VERSION "June 2, 2025"

NS_ :

BS_:

BU_: VEH CH Receiver Receiver ChassisBus VehicleBus PartyBus

BO_ 832 VCFRONT_alertMatrix: 8 VEH
 SG_ VCFRONT_matrixIndex M : 0|4@1+ (1,0) [0|0] "" Vector__XXX
 SG_ VCFRONT_a001_WatchdogReset m0 : 4|1@1+ (1,0) [0|0] "" Vector__XXX
 SG_ VCFRONT_a002_PowerLossReset m0 : 5|1@1+ (1,0) [0|0] "" Vector__XXX
 SG_ VCFRONT_a003_SWAssertion m0 : 6|1@1+ (1,0) [0|0] "" Vector__XXX
 SG_ VCFRONT_a010_ExtSupplyVoltError m0 : 13|1@1+ (1,0) [0|0] "" Vector__XXX
 SG_ VCFRONT_a012_CPUReset m0 : 15|1@1+ (1,0) [0|0] "" Vector__XXX
 SG_ VCFRONT_a013_AlertManagerFault m0 : 16|1@1+ (1,0) [0|0] "" Vector__XXX
 SG_ VCFRONT_a015_NVMMAlert m0 : 18|1@1+ (1,0) [0|0] "" Vector__XXX
 SG_ VCFRONT_a021_TaskSchedulerError m0 : 24|1@1+ (1,0) [0|0] "" Vector__XXX
 SG_ VCFRONT_a022_TaskInitError m0 : 25|1@1+ (1,0) [0|0] "" Vector__XXX
 SG_ VCFRONT_a031_UDSActive m0 : 34|1@1+ (1,0) [0|0] "" Vector__XXX
 SG_ VCFRONT_a041_HighCPULoad m0 : 44|1@1+ (1,0) [0|0] "" Vector__XXX
 SG_ VCFRONT_a042_HighStackUsage m0 : 45|1@1+ (1,0) [0|0] "" Vector__XXX
 SG_ VCFRONT_a043_Task1msError m0 : 46|1@1+ (1,0) [0|0] "" Vector__XXX
 SG_ VCFRONT_a044_Task10msError m0 : 47|1@1+ (1,0) [0|0] "" Vector__XXX
 SG_ VCFRONT_a045_Task100msError m0 : 48|1@1+ (1,0) [0|0] "" Vector__XXX
 SG_ VCFRONT_a046_Task1000msError m0 : 49|1@1+ (1,0) [0|0] "" Vector__XXX
 SG_ VCFRONT_a059_inputResistanceHigh m0 : 62|1@1+ (1,0) [0|0] "" Vector__XXX
 SG_ VCFRONT_a060_engineeringBuild m0 : 63|1@1+ (1,0) [0|0] "" Vector__XXX
 SG_ VCFRONT_a061_XCPConnected m1 : 4|1@1+ (1,0) [0|0] "" Vector__XXX
 SG_ VCFRONT_a062_XCPWasConnected m1 : 5|1@1+ (1,0) [0|0] "" Vector__XXX
 SG_ VCFRONT_a063_SwitchFault m1 : 6|1@1+ (1,0) [0|0] "" Vector__XXX
 SG_ VCFRONT_a064_busSleepReqTimeout m1 : 7|1@1+ (1,0) [0|0] "" Vector__XXX
 SG_ VCFRONT_a097_CMP_MIA m1 : 40|1@1+ (1,0) [0|0] "" Vector__XXX
 SG_ VCFRONT_a098_DI_THERMAL_MIA m1 : 41|1@1+ (1,0) [0|0] "" Vector__XXX
 SG_ VCFRONT_a099_PARK_MIA m1 : 42|1@1+ (1,0) [0|0] "" Vector__XXX
 SG_ VCFRONT_a100_CANbus_MIA m1 : 43|1@1+ (1,0) [0|0] "" Vector__XXX
 SG_ VCFRONT_a101_PM_MIA m1 : 44|1@1+ (1,0) [0|0] "" Vector__XXX
 SG_ VCFRONT_a102_PTC_MIA m1 : 45|1@1+ (1,0) [0|0] "" Vector__XXX
 SG_ VCFRONT_a103_CP_MIA m1 : 46|1@1+ (1,0) [0|0] "" Vector__XXX
 SG_ VCFRONT_a104_DAS_MIA m1 : 47|1@1+ (1,0) [0|0] "" Vector__XXX
 SG_ VCFRONT_a105_TAS_MIA m1 : 48|1@1+ (1,0) [0|0] "" Vector__XXX
 SG_ VCFRONT_a106_PCS_MIA m1 : 49|1@1+ (1,0) [0|0] "" Vector__XXX
 SG_ VCFRONT_a107_BMS_MIA m1 : 50|1@1+ (1,0) [0|0] "" Vector__XXX
 SG_ VCFRONT_a108_DIS_MIA m1 : 51|1@1+ (1,0) [0|0] "" Vector__XXX
 SG_ VCFRONT_a109_RCM_MIA m1 : 52|1@1+ (1,0) [0|0] "" Vector__XXX
 SG_ VCFRONT_a110_GTW_MIA m1 : 53|1@1+ (1,0) [0|0] "" Vector__XXX
 SG_ VCFRONT_a111_EPBR_MIA m1 : 54|1@1+ (1,0) [0|0] "" Vector__XXX
 SG_ VCFRONT_a112_EPBL_MIA m1 : 55|1@1+ (1,0) [0|0] "" Vector__XXX
 SG_ VCFRONT_a113_UI_MIA m1 : 56|1@1+ (1,0) [0|0] "" Vector__XXX
 SG_ VCFRONT_a114_ESP_MIA m1 : 57|1@1+ (1,0) [0|0] "" Vector__XXX
 SG_ VCFRONT_a115_VCSEC_MIA m1 : 58|1@1+ (1,0) [0|0] "" Vector__XXX
 SG_ VCFRONT_a116_VCRIGHT_MIA m1 : 59|1@1+ (1,0) [0|0] "" Vector__XXX
 SG_ VCFRONT_a117_VCLEFT_MIA m1 : 60|1@1+ (1,0) [0|0] "" Vector__XXX
 SG_ VCFRONT_a118_VCFRONT_MIA m1 : 61|1@1+ (1,0) [0|0] "" Vector__XXX
 SG_ VCFRONT_a119_SCCM_MIA m1 : 62|1@1+ (1,0) [0|0] "" Vector__XXX
 SG_ VCFRONT_a120_DI_DRIVE_MIA m1 : 63|1@1+ (1,0) [0|0] "" Vector__XXX
 SG_ VCFRONT_a121_pumpBatICLatchFault m2 : 4|1@1+ (1,0) [0|0] "" Vector__XXX
 SG_ VCFRONT_a122_pumpBatICWarning m2 : 5|1@1+ (1,0) [0|0] "" Vector__XXX
 SG_ VCFRONT_a123_pumpPtICLatchFault m2 : 6|1@1+ (1,0) [0|0] "" Vector__XXX
 SG_ VCFRONT_a124_pumpPtICWarning m2 : 7|1@1+ (1,0) [0|0] "" Vector__XXX
 SG_ VCFRONT_a125_thmlFanICLatchFault m2 : 8|1@1+ (1,0) [0|0] "" Vector__XXX
 SG_ VCFRONT_a126_thmlFanICWarning m2 : 9|1@1+ (1,0) [0|0] "" Vector__XXX
 SG_ VCFRONT_a127_vcleftEFuseTrip m2 : 10|1@1+ (1,0) [0|0] "" Vector__XXX
 SG_ VCFRONT_a128_vcrightEFuseTrip m2 : 11|1@1+ (1,0) [0|0] "" Vector__XXX
 SG_ VCFRONT_a129_pcsEFuseTrip m2 : 12|1@1+ (1,0) [0|0] "" Vector__XXX
 SG_ VCFRONT_a130_epas3pEFuseTrip m2 : 13|1@1+ (1,0) [0|0] "" Vector__XXX
 SG_ VCFRONT_a131_epas3sEFuseTrip m2 : 14|1@1+ (1,0) [0|0] "" Vector__XXX
 SG_ VCFRONT_a132_iBoosterEFuseTrip m2 : 15|1@1+ (1,0) [0|0] "" Vector__XXX
 SG_ VCFRONT_a133_espEFuseTrip m2 : 16|1@1+ (1,0) [0|0] "" Vector__XXX
 SG_ VCFRONT_a134_fusedHighEFuseTrip m2 : 17|1@1+ (1,0) [0|0] "" Vector__XXX
 SG_ VCFRONT_a135_coolantLevelLow m2 : 18|1@1+ (1,0) [0|0] "" Vector__XXX
 SG_ VCFRONT_a136_refrigDischTempSns m2 : 19|1@1+ (1,0) [0|0] "" Vector__XXX
 SG_ VCFRONT_a137_refrigDischPresSns m2 : 20|1@1+ (1,0) [0|0] "" Vector__XXX
 SG_ VCFRONT_a138_refrigSuctTempSns m2 : 21|1@1+ (1,0) [0|0] "" Vector__XXX
 SG_ VCFRONT_a139_refrigSuctPresSns m2 : 22|1@1+ (1,0) [0|0] "" Vector__XXX
 SG_ VCFRONT_a140_coolantTempPtSns m2 : 23|1@1+ (1,0) [0|0] "" Vector__XXX
 SG_ VCFRONT_a141_coolantTempBatSns m2 : 24|1@1+ (1,0) [0|0] "" Vector__XXX
 SG_ VCFRONT_a142_exvMotorFault m2 : 25|1@1+ (1,0) [0|0] "" Vector__XXX
 SG_ VCFRONT_a143_pumpBatICTransFault m2 : 26|1@1+ (1,0) [0|0] "" Vector__XXX
 SG_ VCFRONT_a144_pumpPtICTransFault m2 : 27|1@1+ (1,0) [0|0] "" Vector__XXX
 SG_ VCFRONT_a145_thmlFanICTransFault m2 : 28|1@1+ (1,0) [0|0] "" Vector__XXX
 SG_ VCFRONT_a146_pumpBatSoftStall m2 : 29|1@1+ (1,0) [0|0] "" Vector__XXX
 SG_ VCFRONT_a147_pumpPtSoftStall m2 : 30|1@1+ (1,0) [0|0] "" Vector__XXX
 SG_ VCFRONT_a148_thmlFanSoftStall m2 : 31|1@1+ (1,0) [0|0] "" Vector__XXX
 SG_ VCFRONT_a149_BLEFrontPowerCycled m2 : 32|1@1+ (1,0) [0|0] "" Vector__XXX
 SG_ VCFRONT_a150_pumpBatLowRPMCBang m2 : 33|1@1+ (1,0) [0|0] "" Vector__XXX
 SG_ VCFRONT_a151_pumpPtLowRPMCBang m2 : 34|1@1+ (1,0) [0|0] "" Vector__XXX
 SG_ VCFRONT_a152_thmlFanLowRPMCBang m2 : 35|1@1+ (1,0) [0|0] "" Vector__XXX
 SG_ VCFRONT_a156_louverBlockage m2 : 39|1@1+ (1,0) [0|0] "" Vector__XXX
 SG_ VCFRONT_a157_louverBreakage m2 : 40|1@1+ (1,0) [0|0] "" Vector__XXX
 SG_ VCFRONT_a158_louverDisconnected m2 : 41|1@1+ (1,0) [0|0] "" Vector__XXX
 SG_ VCFRONT_a159_fiveWayValveFault m2 : 42|1@1+ (1,0) [0|0] "" Vector__XXX
 SG_ VCFRONT_a160_compressorInhibited m2 : 43|1@1+ (1,0) [0|0] "" Vector__XXX
 SG_ VCFRONT_a161_compressorSelfFault m2 : 44|1@1+ (1,0) [0|0] "" Vector__XXX
 SG_ VCFRONT_a164_eFuseLckoutMissing m2 : 47|1@1+ (1,0) [0|0] "" Vector__XXX
 SG_ VCFRONT_a165_unxpctdEFuseLckout m2 : 48|1@1+ (1,0) [0|0] "" Vector__XXX
 SG_ VCFRONT_a166_rightHCMMIA m2 : 49|1@1+ (1,0) [0|0] "" Vector__XXX
 SG_ VCFRONT_a167_leftHCMMIA m2 : 50|1@1+ (1,0) [0|0] "" Vector__XXX
 SG_ VCFRONT_a168_hcmShortToVBAT m2 : 51|1@1+ (1,0) [0|0] "" Vector__XXX
 SG_ VCFRONT_a169_hcmPhaseEnableFail m2 : 52|1@1+ (1,0) [0|0] "" Vector__XXX
 SG_ VCFRONT_a170_hcmUnderVoltage m2 : 53|1@1+ (1,0) [0|0] "" Vector__XXX
 SG_ VCFRONT_a171_driveBlckdByMsmtch m2 : 54|1@1+ (1,0) [0|0] "" Vector__XXX
 SG_ VCFRONT_a172_wsteHtBlckdByMsmtch m2 : 55|1@1+ (1,0) [0|0] "" Vector__XXX
 SG_ VCFRONT_a173_HVBlckdByMsmtch m2 : 56|1@1+ (1,0) [0|0] "" Vector__XXX
 SG_ VCFRONT_a174_driveNotAuthed m2 : 57|1@1+ (1,0) [0|0] "" Vector__XXX
 SG_ VCFRONT_a175_ambientTempSns m2 : 58|1@1+ (1,0) [0|0] "" Vector__XXX
 SG_ VCFRONT_a176_vehicleInSelfTest m2 : 59|1@1+ (1,0) [0|0] "" Vector__XXX
 SG_ VCFRONT_a177_mcuAudioEFuseFault m2 : 60|1@1+ (1,0) [0|0] "" Vector__XXX
 SG_ VCFRONT_a179_highLVAmpsIntoPCS m2 : 62|1@1+ (1,0) [0|0] "" Vector__XXX
 SG_ VCFRONT_a180_12VNotSupported m2 : 63|1@1+ (1,0) [0|0] "" Vector__XXX
 SG_ VCFRONT_a182_replace12VBattery m3 : 5|1@1+ (1,0) [0|0] "" Vector__XXX
 SG_ VCFRONT_a183_low12VCapacity m3 : 6|1@1+ (1,0) [0|0] "" Vector__XXX
 SG_ VCFRONT_a185_washerFluidLow m3 : 8|1@1+ (1,0) [0|0] "" Vector__XXX
 SG_ VCFRONT_a186_noDriveChgCableCon m3 : 9|1@1+ (1,0) [0|0] "" Vector__XXX
 SG_ VCFRONT_a187_busesNotSleeping m3 : 10|1@1+ (1,0) [0|0] "" Vector__XXX
 SG_ VCFRONT_a188_sleepFailed m3 : 11|1@1+ (1,0) [0|0] "" Vector__XXX
 SG_ VCFRONT_a189_IBSMIA m3 : 12|1@1+ (1,0) [0|0] "" Vector__XXX
 SG_ VCFRONT_a190_DCDCNotOperational m3 : 13|1@1+ (1,0) [0|0] "" Vector__XXX
 SG_ VCFRONT_a191_exitDriveLow12V m3 : 14|1@1+ (1,0) [0|0] "" Vector__XXX
 SG_ VCFRONT_a192_criticalLoadShed m3 : 15|1@1+ (1,0) [0|0] "" Vector__XXX
 SG_ VCFRONT_a193_mcuAudioRetry m3 : 16|1@1+ (1,0) [0|0] "" Vector__XXX
 SG_ VCFRONT_a194_iBoosterRetry m3 : 17|1@1+ (1,0) [0|0] "" Vector__XXX
 SG_ VCFRONT_a195_drveBlckdVltgeTooHgh m3 : 18|1@1+ (1,0) [0|0] "" Vector__XXX
 SG_ VCFRONT_a196_discnctd12VBattery m3 : 19|1@1+ (1,0) [0|0] "" Vector__XXX
 SG_ VCFRONT_a198_PRVCANOverterminate m3 : 21|1@1+ (1,0) [0|0] "" Vector__XXX
 SG_ VCFRONT_a199_PRVCANUndertrminate m3 : 22|1@1+ (1,0) [0|0] "" Vector__XXX
 SG_ VCFRONT_a200_vcleftSelfTestFail m3 : 23|1@1+ (1,0) [0|0] "" Vector__XXX
 SG_ VCFRONT_a201_vcrightSelfTestFail m3 : 24|1@1+ (1,0) [0|0] "" Vector__XXX
 SG_ VCFRONT_a202_pcsSelfTestFail m3 : 25|1@1+ (1,0) [0|0] "" Vector__XXX
 SG_ VCFRONT_a203_epas3pSelfTestFail m3 : 26|1@1+ (1,0) [0|0] "" Vector__XXX
 SG_ VCFRONT_a204_epas3sSelfTestFail m3 : 27|1@1+ (1,0) [0|0] "" Vector__XXX
 SG_ VCFRONT_a205_iBoosterSelfTestFail m3 : 28|1@1+ (1,0) [0|0] "" Vector__XXX
 SG_ VCFRONT_a206_espSelfTestFail m3 : 29|1@1+ (1,0) [0|0] "" Vector__XXX
 SG_ VCFRONT_a207_vbatFusdSelfTestFail m3 : 30|1@1+ (1,0) [0|0] "" Vector__XXX
 SG_ VCFRONT_a208_brakeFluidLow m3 : 31|1@1+ (1,0) [0|0] "" Vector__XXX
 SG_ VCFRONT_a209_brakeFluidSNA m3 : 32|1@1+ (1,0) [0|0] "" Vector__XXX
 SG_ VCFRONT_a210_fiveWayValveCalib m3 : 33|1@1+ (1,0) [0|0] "" Vector__XXX
 SG_ VCFRONT_a211_I2CFault m3 : 34|1@1+ (1,0) [0|0] "" Vector__XXX
 SG_ VCFRONT_a212_IBSOverTemp m3 : 35|1@1+ (1,0) [0|0] "" Vector__XXX
 SG_ VCFRONT_a213_12VOvercharge m3 : 36|1@1+ (1,0) [0|0] "" Vector__XXX
 SG_ VCFRONT_a214_airCompUnderCurrent m3 : 37|1@1+ (1,0) [0|0] "" Vector__XXX
 SG_ VCFRONT_a215_airCompDriverFault m3 : 38|1@1+ (1,0) [0|0] "" Vector__XXX
 SG_ VCFRONT_a219_12VVoltFloorRchd m3 : 42|1@1+ (1,0) [0|0] "" Vector__XXX
 SG_ VCFRONT_a220_reverseBatteryFault m3 : 43|1@1+ (1,0) [0|0] "" Vector__XXX
 SG_ VCFRONT_a221_leftTurnLightFault m3 : 44|1@1+ (1,0) [0|0] "" Vector__XXX
 SG_ VCFRONT_a222_rightTurnLightFault m3 : 45|1@1+ (1,0) [0|0] "" Vector__XXX
 SG_ VCFRONT_a223_12VTempSensDiscnect m3 : 46|1@1+ (1,0) [0|0] "" Vector__XXX
 SG_ VCFRONT_a224_revBatChrgPmpFault m3 : 47|1@1+ (1,0) [0|0] "" Vector__XXX
 SG_ VCFRONT_a225_driveBlckdByShowroom m3 : 48|1@1+ (1,0) [0|0] "" Vector__XXX
 SG_ VCFRONT_a226_railAPoweredForFrunk m3 : 49|1@1+ (1,0) [0|0] "" Vector__XXX
 SG_ VCFRONT_a228_pumpBatFbkSanity m3 : 51|1@1+ (1,0) [0|0] "" Vector__XXX
 SG_ VCFRONT_a229_pumpPtFbkSanity m3 : 52|1@1+ (1,0) [0|0] "" Vector__XXX
 SG_ VCFRONT_a230_thmlFanFbkSanity m3 : 53|1@1+ (1,0) [0|0] "" Vector__XXX
 SG_ VCFRONT_a231_12VTempSensShort m3 : 54|1@1+ (1,0) [0|0] "" Vector__XXX
 SG_ VCFRONT_a233_autopilot1EFuseFault m3 : 56|1@1+ (1,0) [0|0] "" Vector__XXX
 SG_ VCFRONT_a234_autopilot2EFuseFault m3 : 57|1@1+ (1,0) [0|0] "" Vector__XXX
 SG_ VCFRONT_a235_ptTempSnsIrrational m3 : 58|1@1+ (1,0) [0|0] "" Vector__XXX
 SG_ VCFRONT_a236_batTempSnsIrrational m3 : 59|1@1+ (1,0) [0|0] "" Vector__XXX
 SG_ VCFRONT_a237_pumpBatChipComms m3 : 60|1@1+ (1,0) [0|0] "" Vector__XXX
 SG_ VCFRONT_a238_pumpPtChipComms m3 : 61|1@1+ (1,0) [0|0] "" Vector__XXX
 SG_ VCFRONT_a239_thmlFanChipComms m3 : 62|1@1+ (1,0) [0|0] "" Vector__XXX
 SG_ VCFRONT_a243_12VOverchargeInstc m4 : 6|1@1+ (1,0) [0|0] "" Vector__XXX
 SG_ VCFRONT_a244_sleepBypassFault m4 : 7|1@1+ (1,0) [0|0] "" Vector__XXX
 SG_ VCFRONT_a245_pump1EFuseFault m4 : 8|1@1+ (1,0) [0|0] "" Vector__XXX
 SG_ VCFRONT_a246_pump2EFuseFault m4 : 9|1@1+ (1,0) [0|0] "" Vector__XXX
 SG_ VCFRONT_a247_evapSolenoidFault m4 : 10|1@1+ (1,0) [0|0] "" Vector__XXX
 SG_ VCFRONT_a248_voltageOutOfSpec m4 : 11|1@1+ (1,0) [0|0] "" Vector__XXX
 SG_ VCFRONT_a249_fiveWayValveBadMode m4 : 12|1@1+ (1,0) [0|0] "" Vector__XXX
 SG_ VCFRONT_a250_headlampsNotAimed m4 : 13|1@1+ (1,0) [0|0] "" Vector__XXX
 SG_ VCFRONT_a251_UIWakeupTrigger m4 : 14|1@1+ (1,0) [0|0] "" Vector__XXX
 SG_ VCFRONT_a252_frontControllerWakeup m4 : 15|1@1+ (1,0) [0|0] "" Vector__XXX
 SG_ VCFRONT_a253_maxChrgeSssionTmeout m4 : 16|1@1+ (1,0) [0|0] "" Vector__XXX
 SG_ VCFRONT_a254_pumpBatStopped m4 : 17|1@1+ (1,0) [0|0] "" Vector__XXX
 SG_ VCFRONT_a255_pumpPtStopped m4 : 18|1@1+ (1,0) [0|0] "" Vector__XXX
 SG_ VCFRONT_a256_compTornShaftSeal m4 : 19|1@1+ (1,0) [0|0] "" Vector__XXX
 SG_ VCFRONT_a257_portExpanderVOR m4 : 20|1@1+ (1,0) [0|0] "" Vector__XXX
 SG_ VCFRONT_a258_resistanceEstimationRun m4 : 21|1@1+ (1,0) [0|0] "" Vector__XXX
 SG_ VCFRONT_a259_12vVoltageDropOnHighLoadCurrent m4 : 22|1@1+ (1,0) [0|0] "" Vector__XXX

BO_ 837 PTC_info: 8 VEH
 SG_ PTC_infoIndex M : 0|8@1+ (1,0) [0|0] "" Vector__XXX
 SG_ PTC_infoBuildType m10 : 8|3@1+ (1,0) [0|0] "" Vector__XXX
 SG_ PTC_infoBuildConfigId m10 : 16|16@1+ (1,0) [0|0] "" Vector__XXX
 SG_ PTC_infoHardwareId m10 : 32|16@1+ (1,0) [0|0] "" Vector__XXX
 SG_ PTC_infoComponentId m10 : 48|16@1+ (1,0) [0|0] "" Vector__XXX
 SG_ PTC_infoPcbaId m11 : 16|8@1+ (1,0) [0|0] "" Vector__XXX
 SG_ PTC_infoAssemblyId m11 : 24|8@1+ (1,0) [0|0] "" Vector__XXX
 SG_ PTC_infoUsageId m11 : 32|16@1+ (1,0) [0|0] "" Vector__XXX
 SG_ PTC_infoSubUsageId m11 : 48|16@1+ (1,0) [0|0] "" Vector__XXX
 SG_ PTC_infoBootUdsProtoVersion m20 : 8|8@1+ (1,0) [0|0] "" Vector__XXX
 SG_ PTC_infoBootCrc m20 : 32|32@1+ (1,0) [0|0] "" Vector__XXX
 SG_ PTC_infoPlatformType m13 : 8|8@1+ (1,0) [0|0] "" Vector__XXX
 SG_ PTC_infoAppCrc m13 : 32|32@1+ (1,0) [0|0] "" Vector__XXX

BO_ 840 GTW_status: 1 VEH
 SG_ GTW_autopilotTrial : 0|1@1+ (1,0) [0|0] "" Vector__XXX
 SG_ GTW_vehicleVersionMatchStatus : 1|2@1+ (1,0) [0|0] "" Vector__XXX

BO_ 841 DAS_warningMatrix2: 8 VEH
 SG_ DAS_w129_mainCamExtNotCal : 0|1@1+ (1,0) [0|0] "" Vector__XXX
 SG_ DAS_w130_narrowCamExtNotCal : 1|1@1+ (1,0) [0|0] "" Vector__XXX
 SG_ DAS_w131_mainCamCalSaved : 2|1@1+ (1,0) [0|0] "" Vector__XXX
 SG_ DAS_w132_narrowCamCalSaved : 3|1@1+ (1,0) [0|0] "" Vector__XXX
 SG_ DAS_w133_mainCamInitFault : 4|1@1+ (1,0) [0|0] "" Vector__XXX
 SG_ DAS_w134_narrowCamInitFault : 5|1@1+ (1,0) [0|0] "" Vector__XXX
 SG_ DAS_w135_fisheyeCamInitFault : 6|1@1+ (1,0) [0|0] "" Vector__XXX
 SG_ DAS_w136_lPillarCamInitFault : 7|1@1+ (1,0) [0|0] "" Vector__XXX
 SG_ DAS_w137_rPillarCamInitFault : 8|1@1+ (1,0) [0|0] "" Vector__XXX
 SG_ DAS_w138_lRepeatCamInitFault : 9|1@1+ (1,0) [0|0] "" Vector__XXX
 SG_ DAS_w139_rRepeatCamInitFault : 10|1@1+ (1,0) [0|0] "" Vector__XXX
 SG_ DAS_w140_backupCamInitFault : 11|1@1+ (1,0) [0|0] "" Vector__XXX
 SG_ DAS_w141_ECU_Thermal_Issue : 12|1@1+ (1,0) [0|0] "" Vector__XXX
 SG_ DAS_w142_fwdCamPitchProblem : 13|1@1+ (1,0) [0|0] "" Vector__XXX
 SG_ DAS_w143_IDF_event : 14|1@1+ (1,0) [0|0] "" Vector__XXX
 SG_ DAS_w144_selfieCamInitFault : 15|1@1+ (1,0) [0|0] "" Vector__XXX
 SG_ DAS_w171_fisheyeCamExtNotCal : 42|1@1+ (1,0) [0|0] "" Vector__XXX
 SG_ DAS_w172_lPillarCamExtNotCal : 43|1@1+ (1,0) [0|0] "" Vector__XXX
 SG_ DAS_w173_rPillarCamExtNotCal : 44|1@1+ (1,0) [0|0] "" Vector__XXX
 SG_ DAS_w174_lRepeatCamExtNotCal : 45|1@1+ (1,0) [0|0] "" Vector__XXX
 SG_ DAS_w175_rRepeatCamExtNotCal : 46|1@1+ (1,0) [0|0] "" Vector__XXX
 SG_ DAS_w177_fisheyeCamCalSaved : 48|1@1+ (1,0) [0|0] "" Vector__XXX
 SG_ DAS_w178_lPillarCamCalSaved : 49|1@1+ (1,0) [0|0] "" Vector__XXX
 SG_ DAS_w179_rPillarCamCalSaved : 50|1@1+ (1,0) [0|0] "" Vector__XXX
 SG_ DAS_w180_lRepeatCamCalSaved : 51|1@1+ (1,0) [0|0] "" Vector__XXX
 SG_ DAS_w181_rRepeatCamCalSaved : 52|1@1+ (1,0) [0|0] "" Vector__XXX

BO_ 845 TAS_warningMatrix1: 8 VEH
 SG_ TAS_w001_WatchdogReset : 0|1@1+ (1,0) [0|0] "" Vector__XXX
 SG_ TAS_w002_PowerLossReset : 1|1@1+ (1,0) [0|0] "" Vector__XXX
 SG_ TAS_w003_SWAssertion : 2|1@1+ (1,0) [0|0] "" Vector__XXX
 SG_ TAS_w004_CANMIA : 3|1@1+ (1,0) [0|0] "" Vector__XXX
 SG_ TAS_w005_CANHighError : 4|1@1+ (1,0) [0|0] "" Vector__XXX
 SG_ TAS_w006_CANLowError : 5|1@1+ (1,0) [0|0] "" Vector__XXX
 SG_ TAS_w007_LINTimeout : 6|1@1+ (1,0) [0|0] "" Vector__XXX
 SG_ TAS_w008_LIN2Error : 7|1@1+ (1,0) [0|0] "" Vector__XXX
 SG_ TAS_w009_LIN3Error : 8|1@1+ (1,0) [0|0] "" Vector__XXX
 SG_ TAS_w010_ExtSupplyVoltError : 9|1@1+ (1,0) [0|0] "" Vector__XXX
 SG_ TAS_w011_ECUSupplyVoltError : 10|1@1+ (1,0) [0|0] "" Vector__XXX
 SG_ TAS_w012_CPUReset : 11|1@1+ (1,0) [0|0] "" Vector__XXX
 SG_ TAS_w013_Shared13 : 12|1@1+ (1,0) [0|0] "" Vector__XXX
 SG_ TAS_w014_BridgeFault : 13|1@1+ (1,0) [0|0] "" Vector__XXX
 SG_ TAS_w015_NVMMAlert : 14|1@1+ (1,0) [0|0] "" Vector__XXX
 SG_ TAS_w016_MessageTimingError : 15|1@1+ (1,0) [0|0] "" Vector__XXX
 SG_ TAS_w017_AwakeForTooLong : 16|1@1+ (1,0) [0|0] "" Vector__XXX
 SG_ TAS_w018_ADCError : 17|1@1+ (1,0) [0|0] "" Vector__XXX
 SG_ TAS_w019_I2CError : 18|1@1+ (1,0) [0|0] "" Vector__XXX
 SG_ TAS_w020_PWMError : 19|1@1+ (1,0) [0|0] "" Vector__XXX
 SG_ TAS_w021_TaskSchedulerError : 20|1@1+ (1,0) [0|0] "" Vector__XXX
 SG_ TAS_w022_TaskInitError : 21|1@1+ (1,0) [0|0] "" Vector__XXX
 SG_ TAS_w023_SleepError : 22|1@1+ (1,0) [0|0] "" Vector__XXX
 SG_ TAS_w024_WakeError : 23|1@1+ (1,0) [0|0] "" Vector__XXX
 SG_ TAS_w025_CrashEvent : 24|1@1+ (1,0) [0|0] "" Vector__XXX
 SG_ TAS_w026_FlashMemoryError : 25|1@1+ (1,0) [0|0] "" Vector__XXX
 SG_ TAS_w027_NVRAMCorruption : 26|1@1+ (1,0) [0|0] "" Vector__XXX
 SG_ TAS_w028_NVRAMNotResponding : 27|1@1+ (1,0) [0|0] "" Vector__XXX
 SG_ TAS_w029_NVRAMUninitialized : 28|1@1+ (1,0) [0|0] "" Vector__XXX
 SG_ TAS_w030_PWMerrorFL : 29|1@1+ (1,0) [0|0] "" Vector__XXX
 SG_ TAS_w031_PWMerrorFR : 30|1@1+ (1,0) [0|0] "" Vector__XXX
 SG_ TAS_w032_PWMerrorRL : 31|1@1+ (1,0) [0|0] "" Vector__XXX
 SG_ TAS_w033_PWMerrorRR : 32|1@1+ (1,0) [0|0] "" Vector__XXX
 SG_ TAS_w034_PWMshortFL : 33|1@1+ (1,0) [0|0] "" Vector__XXX
 SG_ TAS_w035_PWMshortFR : 34|1@1+ (1,0) [0|0] "" Vector__XXX
 SG_ TAS_w036_PWMshortRL : 35|1@1+ (1,0) [0|0] "" Vector__XXX
 SG_ TAS_w037_PWMshortRR : 36|1@1+ (1,0) [0|0] "" Vector__XXX
 SG_ TAS_w038_PWMopenFL : 37|1@1+ (1,0) [0|0] "" Vector__XXX
 SG_ TAS_w039_PWMopenFR : 38|1@1+ (1,0) [0|0] "" Vector__XXX
 SG_ TAS_w040_PWMopenRL : 39|1@1+ (1,0) [0|0] "" Vector__XXX
 SG_ TAS_w041_PWMopenRR : 40|1@1+ (1,0) [0|0] "" Vector__XXX

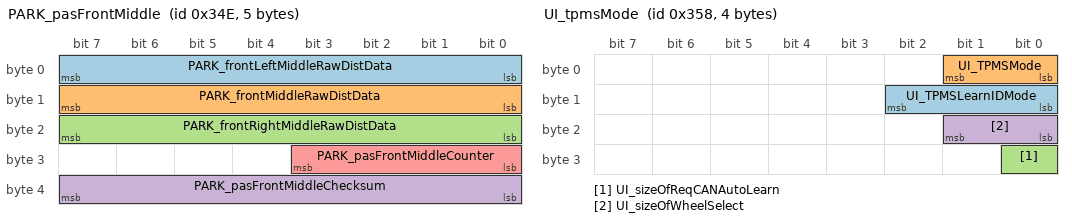
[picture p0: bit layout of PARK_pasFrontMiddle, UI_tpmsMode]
BO_ 846 PARK_pasFrontMiddle: 5 CH
 SG_ PARK_frontLeftMiddleRawDistData : 0|8@1+ (1,0) [0|0] "cm" Vector__XXX
 SG_ PARK_frontMiddleRawDistData : 8|8@1+ (1,0) [0|0] "cm" Vector__XXX
 SG_ PARK_frontRightMiddleRawDistData : 16|8@1+ (1,0) [0|0] "cm" Vector__XXX
 SG_ PARK_pasFrontMiddleChecksum : 32|8@1+ (1,0) [0|0] "" Vector__XXX
 SG_ PARK_pasFrontMiddleCounter : 24|4@1+ (1,0) [0|0] "" Vector__XXX

BO_ 848 APS_warningMatrix3: 8 CH
 SG_ APS_w193_camWindshieldUnclean : 0|1@1+ (1,0) [0|0] "" Vector__XXX
 SG_ APS_w194_accDriverResumeRqrd : 1|1@1+ (1,0) [0|0] "" Vector__XXX
 SG_ APS_w195_scwUnavailable : 2|1@1+ (1,0) [0|0] "" Vector__XXX
 SG_ APS_w196_stopSignWarning : 3|1@1+ (1,0) [0|0] "" Vector__XXX
 SG_ APS_w197_redLightWarning : 4|1@1+ (1,0) [0|0] "" Vector__XXX
 SG_ APS_w198_tsrUnavailable : 5|1@1+ (1,0) [0|0] "" Vector__XXX
 SG_ APS_w199_apcAbort : 6|1@1+ (1,0) [0|0] "" Vector__XXX
 SG_ APS_w200_lcSlowdown : 7|1@1+ (1,0) [0|0] "" Vector__XXX
 SG_ APS_w201_lcAborting : 8|1@1+ (1,0) [0|0] "" Vector__XXX
 SG_ APS_w202_scwNoisyEnvironment : 9|1@1+ (1,0) [0|0] "" Vector__XXX
 SG_ APS_w203_apcActivation : 10|1@1+ (1,0) [0|0] "" Vector__XXX
 SG_ APS_w204_apcFinalFront : 11|1@1+ (1,0) [0|0] "" Vector__XXX
 SG_ APS_w205_apcFinalRear : 12|1@1+ (1,0) [0|0] "" Vector__XXX
 SG_ APS_w206_autosteerNotEnabled : 13|1@1+ (1,0) [0|0] "" Vector__XXX
 SG_ APS_w207_autosteerUnavailable : 14|1@1+ (1,0) [0|0] "" Vector__XXX
 SG_ APS_w208_rackDetected : 15|1@1+ (1,0) [0|0] "" Vector__XXX
 SG_ APS_w209_autoSummonRequest : 16|1@1+ (1,0) [0|0] "" Vector__XXX
 SG_ APS_w210_camObstrcted : 17|1@1+ (1,0) [0|0] "" Vector__XXX
 SG_ APS_w211_accNoSeatBelt : 18|1@1+ (1,0) [0|0] "" Vector__XXX
 SG_ APS_w212_lcUnavailableStrikeOut : 19|1@1+ (1,0) [0|0] "" Vector__XXX
 SG_ APS_w213_autosteerStruckOut : 20|1@1+ (1,0) [0|0] "" Vector__XXX
 SG_ APS_w214_driverNotIntracting : 21|1@1+ (1,0) [0|0] "" Vector__XXX
 SG_ APS_w215_contDriverNotIntracting : 22|1@1+ (1,0) [0|0] "" Vector__XXX
 SG_ APS_w216_driverOverriding : 23|1@1+ (1,0) [0|0] "" Vector__XXX
 SG_ APS_w217_lcUnavailableSpeeding : 24|1@1+ (1,0) [0|0] "" Vector__XXX
 SG_ APS_w218_lcSpeedExceededLimit : 25|1@1+ (1,0) [0|0] "" Vector__XXX
 SG_ APS_w219_lcTempUnavailableSpeed : 26|1@1+ (1,0) [0|0] "" Vector__XXX
 SG_ APS_w220_lcTempUnavailableRoad : 27|1@1+ (1,0) [0|0] "" Vector__XXX
 SG_ APS_w221_accRadarBlind : 28|1@1+ (1,0) [0|0] "" Vector__XXX
 SG_ APS_w222_accCameraBlind : 29|1@1+ (1,0) [0|0] "" Vector__XXX
 SG_ APS_w223_accObjectInPath : 30|1@1+ (1,0) [0|0] "" Vector__XXX
 SG_ APS_w224_accCameraCalibration : 31|1@1+ (1,0) [0|0] "" Vector__XXX
 SG_ APS_w225_lcDegradedVisSpeedLmt : 32|1@1+ (1,0) [0|0] "" Vector__XXX
 SG_ APS_w226_lcCamCalNeededSpeedLmt : 33|1@1+ (1,0) [0|0] "" Vector__XXX
 SG_ APS_w227_virtualWallBlocked : 34|1@1+ (1,0) [0|0] "" Vector__XXX
 SG_ APS_w228_DEPRECATED : 35|1@1+ (1,0) [0|0] "" Vector__XXX
 SG_ APS_w229_alcUltrasoundDamaged : 36|1@1+ (1,0) [0|0] "" Vector__XXX
 SG_ APS_w230_alcUltrasoundBlocked : 37|1@1+ (1,0) [0|0] "" Vector__XXX

BO_ 849 RCM_info: 8 CH
 SG_ RCM_infoIndex M : 0|8@1+ (1,0) [0|0] "" Vector__XXX
 SG_ RCM_infoBuildType m10 : 8|8@1+ (1,0) [0|0] "" Vector__XXX
 SG_ RCM_infoComponentID m10 : 48|16@1+ (1,0) [0|0] "" Vector__XXX
 SG_ RCM_infoPcbaID m11 : 16|8@1+ (1,0) [0|0] "" Vector__XXX
 SG_ RCM_infoAssemblyID m11 : 24|8@1+ (1,0) [0|0] "" Vector__XXX
 SG_ RCM_infoUsageID m11 : 32|16@1+ (1,0) [0|0] "" Vector__XXX
 SG_ RCM_infoBootUdsProtoVersion m20 : 8|8@1+ (1,0) [0|0] "" Vector__XXX
 SG_ RCM_infoBootloaderCRC m20 : 32|32@1+ (1,0) [0|0] "" Vector__XXX
 SG_ RCM_infoApplicationCRC m13 : 32|32@1+ (1,0) [0|0] "" Vector__XXX
 SG_ RCM_infoVariantCRC m22 : 32|32@1+ (1,0) [0|0] "" Vector__XXX

BO_ 850 BMS_energyStatus: 8 VEH
 SG_ BMS_energyStatusIndex M : 0|2@1+ (1,0) [0|0] "" Vector__XXX
 SG_ BMS_nominalFullPackEnergy m0 : 16|16@1+ (0.02,0) [0|0] "kWh" Vector__XXX
 SG_ BMS_nominalEnergyRemaining m0 : 32|16@1+ (0.02,0) [0|0] "kWh" Vector__XXX
 SG_ BMS_idealEnergyRemaining m0 : 48|16@1+ (0.02,0) [0|0] "kWh" Vector__XXX
 SG_ BMS_fullyCharged m1 : 15|1@1+ (1,0) [0|1] "" Vector__XXX
 SG_ BMS_energyBuffer m1 : 16|16@1+ (0.01,0) [0|0] "kWh" Vector__XXX
 SG_ BMS_expectedEnergyRemaining m1 : 32|16@1+ (0.02,0) [0|0] "kWh" Vector__XXX
 SG_ BMS_energyToChargeComplete m1 : 48|16@1+ (0.02,0) [0|0] "kWh" Vector__XXX

BO_ 851 UI_status: 7 VEH
 SG_ UI_audioActive : 1|1@1+ (1,0) [0|0] "" Vector__XXX
 SG_ UI_autopilotTrial : 12|2@1+ (1,0) [0|0] "" Vector__XXX
 SG_ UI_bluetoothActive : 2|1@1+ (1,0) [0|0] "" Vector__XXX
 SG_ UI_cameraActive : 49|1@1+ (1,0) [0|0] "" Vector__XXX
 SG_ UI_cellActive : 3|1@1+ (1,0) [0|0] "" Vector__XXX
 SG_ UI_cellConnected : 10|1@1+ (1,0) [0|0] "" Vector__XXX
 SG_ UI_cellNetworkTechnology : 19|4@1+ (1,0) [0|0] "" Vector__XXX
 SG_ UI_cellReceiverPower : 32|8@1+ (1,-128) [-128|127] "dB" Vector__XXX
 SG_ UI_cellSignalBars : 24|3@1+ (1,0) [0|7] "" Vector__XXX
 SG_ UI_developmentCar : 48|1@1+ (1,0) [0|0] "" Vector__XXX
 SG_ UI_displayOn : 5|1@1+ (1,0) [0|0] "" Vector__XXX
 SG_ UI_displayReady : 4|1@1+ (1,0) [0|0] "" Vector__XXX
 SG_ UI_factoryReset : 14|2@1+ (1,0) [0|0] "" Vector__XXX
 SG_ UI_falseTouchCounter : 40|8@1+ (1,0) [0|0] "1" Vector__XXX
 SG_ UI_gpsActive : 16|1@1+ (1,0) [0|0] "" Vector__XXX
 SG_ UI_radioActive : 18|1@1+ (1,0) [0|0] "" Vector__XXX
 SG_ UI_readyForDrive : 9|1@1+ (1,0) [0|0] "" Vector__XXX
 SG_ UI_screenshotActive : 17|1@1+ (1,0) [0|0] "" Vector__XXX
 SG_ UI_systemActive : 8|1@1+ (1,0) [0|0] "" Vector__XXX
 SG_ UI_touchActive : 0|1@1+ (1,0) [0|0] "" Vector__XXX
 SG_ UI_vpnActive : 11|1@1+ (1,0) [0|0] "" Vector__XXX
 SG_ UI_wifiActive : 6|1@1+ (1,0) [0|0] "" Vector__XXX
 SG_ UI_wifiConnected : 7|1@1+ (1,0) [0|0] "" Vector__XXX

BO_ 854 DI_alertMatrix1: 8 VEH
 SG_ DI_a001_hwPhaseAgateDrive : 0|1@1+ (1,0) [0|0] "" Vector__XXX
 SG_ DI_a002_hwPhaseBgateDrive : 1|1@1+ (1,0) [0|0] "" Vector__XXX
 SG_ DI_a003_hwPhaseCgateDrive : 2|1@1+ (1,0) [0|0] "" Vector__XXX
 SG_ DI_a004_hwPhaseApeak : 3|1@1+ (1,0) [0|0] "" Vector__XXX
 SG_ DI_a005_hwPhaseBpeak : 4|1@1+ (1,0) [0|0] "" Vector__XXX
 SG_ DI_a006_hwPhaseCpeak : 5|1@1+ (1,0) [0|0] "" Vector__XXX
 SG_ DI_a007_hwHvilNotPresent : 6|1@1+ (1,0) [0|0] "" Vector__XXX
 SG_ DI_a008_hwEncoderA : 7|1@1+ (1,0) [0|0] "" Vector__XXX
 SG_ DI_a009_hwEncoderB : 8|1@1+ (1,0) [0|0] "" Vector__XXX
 SG_ DI_a011_swPowerStageNotReady : 10|1@1+ (1,0) [0|0] "" Vector__XXX
 SG_ DI_a012_accel5VSupply : 11|1@1+ (1,0) [0|0] "" Vector__XXX
 SG_ DI_a014_activeDamping : 13|1@1+ (1,0) [0|0] "" Vector__XXX
 SG_ DI_a015_immobilizer : 14|1@1+ (1,0) [0|0] "" Vector__XXX
 SG_ DI_a016_safeStateApplied : 15|1@1+ (1,0) [0|0] "" Vector__XXX
 SG_ DI_a017_hwPedalMonitor : 16|1@1+ (1,0) [0|0] "" Vector__XXX
 SG_ DI_a018_hw12vSupplyUV : 17|1@1+ (1,0) [0|0] "" Vector__XXX
 SG_ DI_a019_hwAccelPedalPower : 18|1@1+ (1,0) [0|0] "" Vector__XXX
 SG_ DI_a020_hwMotorEncoder : 19|1@1+ (1,0) [0|0] "" Vector__XXX
 SG_ DI_a021_hwBusOV : 20|1@1+ (1,0) [0|0] "" Vector__XXX
 SG_ DI_a022_hw5vSupplyUV : 21|1@1+ (1,0) [0|0] "" Vector__XXX
 SG_ DI_a023_carNotParked : 22|1@1+ (1,0) [0|0] "" Vector__XXX
 SG_ DI_a024_selfTest : 23|1@1+ (1,0) [0|0] "" Vector__XXX
 SG_ DI_a025_phaseApeak : 24|1@1+ (1,0) [0|0] "" Vector__XXX
 SG_ DI_a026_phaseBpeak : 25|1@1+ (1,0) [0|0] "" Vector__XXX
 SG_ DI_a027_phaseCpeak : 26|1@1+ (1,0) [0|0] "" Vector__XXX
 SG_ DI_a028_phaseArms : 27|1@1+ (1,0) [0|0] "" Vector__XXX
 SG_ DI_a029_phaseBrms : 28|1@1+ (1,0) [0|0] "" Vector__XXX
 SG_ DI_a030_phaseCrms : 29|1@1+ (1,0) [0|0] "" Vector__XXX
 SG_ DI_a031_phaseAcurrentOffset : 30|1@1+ (1,0) [0|0] "" Vector__XXX
 SG_ DI_a032_phaseBcurrentOffset : 31|1@1+ (1,0) [0|0] "" Vector__XXX
 SG_ DI_a033_phaseAcurrentSensor : 32|1@1+ (1,0) [0|0] "" Vector__XXX
 SG_ DI_a034_phaseBcurrentSensor : 33|1@1+ (1,0) [0|0] "" Vector__XXX
 SG_ DI_a035_phaseCurrentBalance : 34|1@1+ (1,0) [0|0] "" Vector__XXX
 SG_ DI_a036_busOV : 35|1@1+ (1,0) [0|0] "" Vector__XXX
 SG_ DI_a037_busUV : 36|1@1+ (1,0) [0|0] "" Vector__XXX
 SG_ DI_a038_busVsensor : 37|1@1+ (1,0) [0|0] "" Vector__XXX
 SG_ DI_a039_noRegen : 38|1@1+ (1,0) [0|0] "" Vector__XXX
 SG_ DI_a040_disMIA : 39|1@1+ (1,0) [0|0] "" Vector__XXX
 SG_ DI_a041_driverBrakeApplyCheck : 40|1@1+ (1,0) [0|0] "" Vector__XXX
 SG_ DI_a042_inletSensor : 41|1@1+ (1,0) [0|0] "" Vector__XXX
 SG_ DI_a043_outletOT : 42|1@1+ (1,0) [0|0] "" Vector__XXX
 SG_ DI_a044_outletUT : 43|1@1+ (1,0) [0|0] "" Vector__XXX
 SG_ DI_a045_outletSensor : 44|1@1+ (1,0) [0|0] "" Vector__XXX
 SG_ DI_a046_statorOT : 45|1@1+ (1,0) [0|0] "" Vector__XXX
 SG_ DI_a047_statorSensor1 : 46|1@1+ (1,0) [0|0] "" Vector__XXX
 SG_ DI_a050_noStatorSensor : 49|1@1+ (1,0) [0|0] "" Vector__XXX
 SG_ DI_a051_batteryOvercurrent : 50|1@1+ (1,0) [0|0] "" Vector__XXX
 SG_ DI_a054_driveInverterOT : 53|1@1+ (1,0) [0|0] "" Vector__XXX
 SG_ DI_a055_trqCrossCheck : 54|1@1+ (1,0) [0|0] "" Vector__XXX
 SG_ DI_a056_ambientOT : 55|1@1+ (1,0) [0|0] "" Vector__XXX
 SG_ DI_a057_ambientUT : 56|1@1+ (1,0) [0|0] "" Vector__XXX
 SG_ DI_a058_ambientSensor : 57|1@1+ (1,0) [0|0] "" Vector__XXX
 SG_ DI_a059_heatsinkOT : 58|1@1+ (1,0) [0|0] "" Vector__XXX
 SG_ DI_a060_heatsinkUT : 59|1@1+ (1,0) [0|0] "" Vector__XXX
 SG_ DI_a061_heatsinkSensor : 60|1@1+ (1,0) [0|0] "" Vector__XXX
 SG_ DI_a062_systemLimpMode : 61|1@1+ (1,0) [0|0] "" Vector__XXX
 SG_ DI_a063_systemGracefulPowerOff : 62|1@1+ (1,0) [0|0] "" Vector__XXX
 SG_ DI_a064_torqueIntervention : 63|1@1+ (1,0) [0|0] "" Vector__XXX

BO_ 855 DI_alertMatrix2: 8 VEH
 SG_ DI_a065_canHardwareBusB : 0|1@1+ (1,0) [0|0] "" Vector__XXX
 SG_ DI_a066_canDataBusB : 1|1@1+ (1,0) [0|0] "" Vector__XXX
 SG_ DI_a067_canOverrunBusB : 2|1@1+ (1,0) [0|0] "" Vector__XXX
 SG_ DI_a070_12vSupplySensor : 5|1@1+ (1,0) [0|0] "" Vector__XXX
 SG_ DI_a071_busDisconnected : 6|1@1+ (1,0) [0|0] "" Vector__XXX
 SG_ DI_a072_gateDriveFaultCounter : 7|1@1+ (1,0) [0|0] "" Vector__XXX
 SG_ DI_a073_motorSpeed : 8|1@1+ (1,0) [0|0] "" Vector__XXX
 SG_ DI_a074_motorEncoder : 9|1@1+ (1,0) [0|0] "" Vector__XXX
 SG_ DI_a075_motorSpeedMismatch : 10|1@1+ (1,0) [0|0] "" Vector__XXX
 SG_ DI_a076_12vSupplyOV : 11|1@1+ (1,0) [0|0] "" Vector__XXX
 SG_ DI_a077_12vSupplyUV : 12|1@1+ (1,0) [0|0] "" Vector__XXX
 SG_ DI_a078_adcRefLow : 13|1@1+ (1,0) [0|0] "" Vector__XXX
 SG_ DI_a079_adcRefHigh : 14|1@1+ (1,0) [0|0] "" Vector__XXX
 SG_ DI_a080_accelSynch : 15|1@1+ (1,0) [0|0] "" Vector__XXX
 SG_ DI_a081_accelTrack1 : 16|1@1+ (1,0) [0|0] "" Vector__XXX
 SG_ DI_a082_accelTrack2 : 17|1@1+ (1,0) [0|0] "" Vector__XXX
 SG_ DI_a083_brakePedalSensor : 18|1@1+ (1,0) [0|0] "" Vector__XXX
 SG_ DI_a085_proximityInEnable : 20|1@1+ (1,0) [0|0] "" Vector__XXX
 SG_ DI_a086_hvilNotPresent : 21|1@1+ (1,0) [0|0] "" Vector__XXX
 SG_ DI_a087_gtwMIA : 22|1@1+ (1,0) [0|0] "" Vector__XXX
 SG_ DI_a088_uiMIA : 23|1@1+ (1,0) [0|0] "" Vector__XXX
 SG_ DI_a089_sccmMIA : 24|1@1+ (1,0) [0|0] "" Vector__XXX
 SG_ DI_a090_pmMIA : 25|1@1+ (1,0) [0|0] "" Vector__XXX
 SG_ DI_a091_espMIA : 26|1@1+ (1,0) [0|0] "" Vector__XXX
 SG_ DI_a092_bmsMIA : 27|1@1+ (1,0) [0|0] "" Vector__XXX
 SG_ DI_a093_canHardwareBusA : 28|1@1+ (1,0) [0|0] "" Vector__XXX
 SG_ DI_a094_canDataBusA : 29|1@1+ (1,0) [0|0] "" Vector__XXX
 SG_ DI_a095_canOverrunBusA : 30|1@1+ (1,0) [0|0] "" Vector__XXX
 SG_ DI_a096_memoryError : 31|1@1+ (1,0) [0|0] "" Vector__XXX
 SG_ DI_a097_eepromError : 32|1@1+ (1,0) [0|0] "" Vector__XXX
 SG_ DI_a098_intTimeTooLong : 33|1@1+ (1,0) [0|0] "" Vector__XXX
 SG_ DI_a099_threadOverrun : 34|1@1+ (1,0) [0|0] "" Vector__XXX
 SG_ DI_a100_assertion : 35|1@1+ (1,0) [0|0] "" Vector__XXX
 SG_ DI_a103_lowFlow : 38|1@1+ (1,0) [0|0] "" Vector__XXX
 SG_ DI_a104_proximityIrrational : 39|1@1+ (1,0) [0|0] "" Vector__XXX
 SG_ DI_a105_cpMIA : 40|1@1+ (1,0) [0|0] "" Vector__XXX
 SG_ DI_a106_absMIA : 41|1@1+ (1,0) [0|0] "" Vector__XXX
 SG_ DI_a108_stateTrans : 43|1@1+ (1,0) [0|0] "" Vector__XXX
 SG_ DI_a109_cruiseMIA : 44|1@1+ (1,0) [0|0] "" Vector__XXX
 SG_ DI_a110_brakeMIA : 45|1@1+ (1,0) [0|0] "" Vector__XXX
 SG_ DI_a112_noPhaseCurrent : 47|1@1+ (1,0) [0|0] "" Vector__XXX
 SG_ DI_a113_noFuncHeatsinkSensor : 48|1@1+ (1,0) [0|0] "" Vector__XXX
 SG_ DI_a114_noMotorSpeed : 49|1@1+ (1,0) [0|0] "" Vector__XXX
 SG_ DI_a115_heatsinkTempImbalance : 50|1@1+ (1,0) [0|0] "" Vector__XXX
 SG_ DI_a116_powerConvIrrational : 51|1@1+ (1,0) [0|0] "" Vector__XXX
 SG_ DI_a117_diMIA : 52|1@1+ (1,0) [0|0] "" Vector__XXX
 SG_ DI_a121_motorControlRegulation : 56|1@1+ (1,0) [0|0] "" Vector__XXX
 SG_ DI_a122_highStackUsage : 57|1@1+ (1,0) [0|0] "" Vector__XXX
 SG_ DI_a123_lossMotorControl : 58|1@1+ (1,0) [0|0] "" Vector__XXX
 SG_ DI_a124_cruiseFault : 59|1@1+ (1,0) [0|0] "" Vector__XXX
 SG_ DI_a125_noBatteryPower : 60|1@1+ (1,0) [0|0] "" Vector__XXX
 SG_ DI_a126_limpMode : 61|1@1+ (1,0) [0|0] "" Vector__XXX
 SG_ DI_a127_gracefulPowerOff : 62|1@1+ (1,0) [0|0] "" Vector__XXX

BO_ 856 UI_tpmsMode: 4 VEH
 SG_ UI_TPMSLearnIDMode : 8|3@1+ (1,0) [0|0] "" Vector__XXX
 SG_ UI_TPMSMode : 0|2@1+ (1,0) [0|0] "" Vector__XXX
 SG_ UI_sizeOfReqCANAutoLearn : 24|1@1+ (1,0) [0|0] "" Vector__XXX
 SG_ UI_sizeOfWheelSelect : 16|2@1+ (1,0) [0|0] "" Vector__XXX

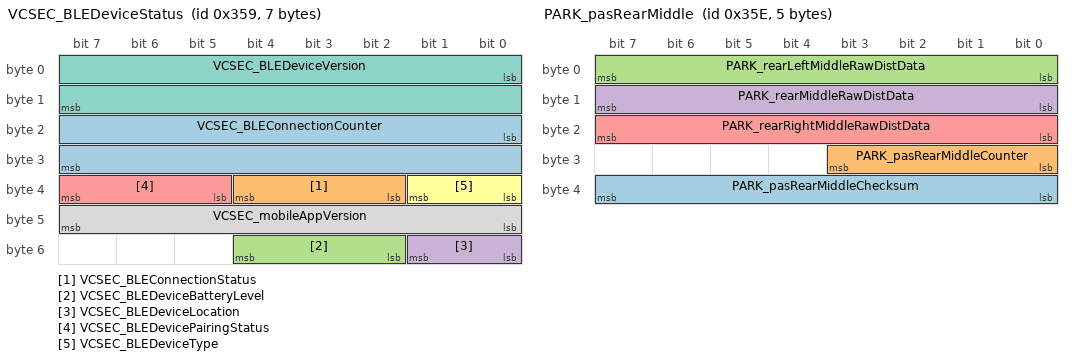
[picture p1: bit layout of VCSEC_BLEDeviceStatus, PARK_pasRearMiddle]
BO_ 857 VCSEC_BLEDeviceStatus: 7 VEH
 SG_ VCSEC_BLEConnectionCounter : 16|16@1+ (1,0) [0|0] "" Vector__XXX
 SG_ VCSEC_BLEConnectionStatus : 34|3@1+ (1,0) [0|0] "" Vector__XXX
 SG_ VCSEC_BLEDeviceBatteryLevel : 50|3@1+ (1,0) [0|0] "" Vector__XXX
 SG_ VCSEC_BLEDeviceLocation : 48|2@1+ (1,0) [0|0] "" Vector__XXX
 SG_ VCSEC_BLEDevicePairingStatus : 37|3@1+ (1,0) [0|0] "" Vector__XXX
 SG_ VCSEC_BLEDeviceType : 32|2@1+ (1,0) [0|0] "" Vector__XXX
 SG_ VCSEC_BLEDeviceVersion : 0|16@1+ (1,0) [0|0] "" Vector__XXX
 SG_ VCSEC_mobileAppVersion : 40|8@1+ (1,0) [0|0] "" Vector__XXX

BO_ 858 DI_alertMatrix3: 8 VEH
 SG_ DI_a129_epbNotApplied : 0|1@1+ (1,0) [0|0] "" Vector__XXX
 SG_ DI_a130_aebFault : 1|1@1+ (1,0) [0|0] "" Vector__XXX
 SG_ DI_a131_highSpeedWearLimit : 2|1@1+ (1,0) [0|0] "" Vector__XXX
 SG_ DI_a133_capacitorOT : 4|1@1+ (1,0) [0|0] "" Vector__XXX
 SG_ DI_a134_wheelSpeedIrrational : 5|1@1+ (1,0) [0|0] "" Vector__XXX
 SG_ DI_a135_vehicleHoldFault : 6|1@1+ (1,0) [0|0] "" Vector__XXX
 SG_ DI_a136_spiError : 7|1@1+ (1,0) [0|0] "" Vector__XXX
 SG_ DI_a137_noCapableDriveUnits : 8|1@1+ (1,0) [0|0] "" Vector__XXX
 SG_ DI_a138_frontUnitDisabled : 9|1@1+ (1,0) [0|0] "" Vector__XXX
 SG_ DI_a139_rearUnitDisabled : 10|1@1+ (1,0) [0|0] "" Vector__XXX
 SG_ DI_a141_dasMIA : 12|1@1+ (1,0) [0|0] "" Vector__XXX
 SG_ DI_a142_highLashAngle : 13|1@1+ (1,0) [0|0] "" Vector__XXX
 SG_ DI_a143_mcuLimitActive : 14|1@1+ (1,0) [0|0] "" Vector__XXX
 SG_ DI_a144_configMismatch : 15|1@1+ (1,0) [0|0] "" Vector__XXX
 SG_ DI_a145_pbrkPanicSkid : 16|1@1+ (1,0) [0|0] "" Vector__XXX
 SG_ DI_a146_pbrkPanicEpbFault : 17|1@1+ (1,0) [0|0] "" Vector__XXX
 SG_ DI_a147_highTorqueWearLimit : 18|1@1+ (1,0) [0|0] "" Vector__XXX
 SG_ DI_a148_overtorqueUsed : 19|1@1+ (1,0) [0|0] "" Vector__XXX
 SG_ DI_a149_oilPumpFailure : 20|1@1+ (1,0) [0|0] "" Vector__XXX
 SG_ DI_a150_busVD : 21|1@1+ (1,0) [0|0] "" Vector__XXX
 SG_ DI_a151_shockTorqueLimiter : 22|1@1+ (1,0) [0|0] "" Vector__XXX
 SG_ DI_a152_linError : 23|1@1+ (1,0) [0|0] "" Vector__XXX
 SG_ DI_a153_oilPump : 24|1@1+ (1,0) [0|0] "" Vector__XXX
 SG_ DI_a154_resolver : 25|1@1+ (1,0) [0|0] "" Vector__XXX
 SG_ DI_a155_vcfrontMIA : 26|1@1+ (1,0) [0|0] "" Vector__XXX
 SG_ DI_a156_currentObserver : 27|1@1+ (1,0) [0|0] "" Vector__XXX
 SG_ DI_a157_rcmMIA : 28|1@1+ (1,0) [0|0] "" Vector__XXX
 SG_ DI_a158_ibstMIA : 29|1@1+ (1,0) [0|0] "" Vector__XXX
 SG_ DI_a159_cruiseSelfCheck : 30|1@1+ (1,0) [0|0] "" Vector__XXX
 SG_ DI_a160_busVoltageAnomaly : 31|1@1+ (1,0) [0|0] "" Vector__XXX
 SG_ DI_a161_epas3pMIA : 32|1@1+ (1,0) [0|0] "" Vector__XXX
 SG_ DI_a162_shiftDenied : 33|1@1+ (1,0) [0|0] "" Vector__XXX
 SG_ DI_a163_unparkReq : 34|1@1+ (1,0) [0|0] "" Vector__XXX
 SG_ DI_a164_brakeOverride : 35|1@1+ (1,0) [0|0] "" Vector__XXX
 SG_ DI_a165_cruiseCancelled : 36|1@1+ (1,0) [0|0] "" Vector__XXX
 SG_ DI_a166_driverLeft : 37|1@1+ (1,0) [0|0] "" Vector__XXX
 SG_ DI_a167_keyNotAuthenticated : 38|1@1+ (1,0) [0|0] "" Vector__XXX
 SG_ DI_a168_proximityDriveDenial : 39|1@1+ (1,0) [0|0] "" Vector__XXX
 SG_ DI_a169_regenOffOverride : 40|1@1+ (1,0) [0|0] "" Vector__XXX
 SG_ DI_a170_pedalFoul : 41|1@1+ (1,0) [0|0] "" Vector__XXX
 SG_ DI_a171_driveRailNotRequested : 42|1@1+ (1,0) [0|0] "" Vector__XXX
 SG_ DI_a172_accelPressedInNP : 43|1@1+ (1,0) [0|0] "" Vector__XXX
 SG_ DI_a173_bothPedalsPressed : 44|1@1+ (1,0) [0|0] "" Vector__XXX
 SG_ DI_a174_notOkToStartDrive : 45|1@1+ (1,0) [0|0] "" Vector__XXX
 SG_ DI_a175_crsNotAvailable : 46|1@1+ (1,0) [0|0] "" Vector__XXX
 SG_ DI_a176_EBRreleased : 47|1@1+ (1,0) [0|0] "" Vector__XXX
 SG_ DI_a177_tireFitmentChanged : 48|1@1+ (1,0) [0|0] "" Vector__XXX
 SG_ DI_a180_crsSeatbeltUnbuckled : 51|1@1+ (1,0) [0|0] "" Vector__XXX
 SG_ DI_a181_rearMotorMode : 52|1@1+ (1,0) [0|0] "" Vector__XXX
 SG_ DI_a182_frontMotorMode : 53|1@1+ (1,0) [0|0] "" Vector__XXX
 SG_ DI_a183_holdReleaseRqrd : 54|1@1+ (1,0) [0|0] "" Vector__XXX
 SG_ DI_a184_autoparkCanceled : 55|1@1+ (1,0) [0|0] "" Vector__XXX
 SG_ DI_a185_autoparkAborted : 56|1@1+ (1,0) [0|0] "" Vector__XXX
 SG_ DI_a186_brakeStand : 57|1@1+ (1,0) [0|0] "" Vector__XXX
 SG_ DI_a187_pedalMisapplication : 58|1@1+ (1,0) [0|0] "" Vector__XXX
 SG_ DI_a189_garageShiftWithPedal : 60|1@1+ (1,0) [0|0] "" Vector__XXX
 SG_ DI_a191_brakeShiftReq : 62|1@1+ (1,0) [0|0] "" Vector__XXX
 SG_ DI_a192_invalidOdometer : 63|1@1+ (1,0) [0|0] "" Vector__XXX

BO_ 859 DI_alertMatrix4: 8 VEH
 SG_ DI_a193_vdcEspBrakeTorqueFr : 0|1@1+ (1,0) [0|0] "" Vector__XXX
 SG_ DI_a194_vdcEspBrakeTorqueRe : 1|1@1+ (1,0) [0|0] "" Vector__XXX
 SG_ DI_a195_vdcEspSlipFr : 2|1@1+ (1,0) [0|0] "" Vector__XXX
 SG_ DI_a196_vdcEspSlipRe : 3|1@1+ (1,0) [0|0] "" Vector__XXX
 SG_ DI_a197_vdcEspWheelSaturations : 4|1@1+ (1,0) [0|0] "" Vector__XXX
 SG_ DI_a198_vdcEspMCPressAndSteering : 5|1@1+ (1,0) [0|0] "" Vector__XXX
 SG_ DI_a199_vdcFaulted : 6|1@1+ (1,0) [0|0] "" Vector__XXX
 SG_ DI_a200_vdcModelBasedPlausibility : 7|1@1+ (1,0) [0|0] "" Vector__XXX
 SG_ DI_a201_regenLimited : 8|1@1+ (1,0) [0|0] "" Vector__XXX
 SG_ DI_a202_excessHeatUnavailable : 9|1@1+ (1,0) [0|0] "" Vector__XXX
 SG_ DI_a203_TCReducedByADD : 10|1@1+ (1,0) [0|0] "" Vector__XXX
 SG_ DI_a204_vdcRcmLongitudinal : 11|1@1+ (1,0) [0|0] "" Vector__XXX
 SG_ DI_a205_vdcRcmLateral : 12|1@1+ (1,0) [0|0] "" Vector__XXX
 SG_ DI_a206_vdcRcmVertical : 13|1@1+ (1,0) [0|0] "" Vector__XXX
 SG_ DI_a207_vdcPowertrainTorqueFr : 14|1@1+ (1,0) [0|0] "" Vector__XXX
 SG_ DI_a208_vdcPowertrainTorqueRe : 15|1@1+ (1,0) [0|0] "" Vector__XXX
 SG_ DI_a209_vdcVehicleSpeed : 16|1@1+ (1,0) [0|0] "" Vector__XXX
 SG_ DI_a210_vdcOtherControllerStates : 17|1@1+ (1,0) [0|0] "" Vector__XXX
 SG_ DI_a211_vdcMotorSpeeds : 18|1@1+ (1,0) [0|0] "" Vector__XXX
 SG_ DI_a212_velEstWheelSpeedCGFr : 19|1@1+ (1,0) [0|0] "" Vector__XXX
 SG_ DI_a213_velEstWheelSpeedCGRe : 20|1@1+ (1,0) [0|0] "" Vector__XXX
 SG_ DI_a214_velEstWheelSpeedNonCGFr : 21|1@1+ (1,0) [0|0] "" Vector__XXX
 SG_ DI_a215_velEstWheelSpeedNonCGRe : 22|1@1+ (1,0) [0|0] "" Vector__XXX
 SG_ DI_a216_vdcMBPAlmostTripped : 23|1@1+ (1,0) [0|0] "" Vector__XXX
 SG_ DI_a217_vdcOutputIrrational : 24|1@1+ (1,0) [0|0] "" Vector__XXX
 SG_ DI_a218_vdcOSPreControlActive : 25|1@1+ (1,0) [0|0] "" Vector__XXX
 SG_ DI_a219_vdcOversteerdMzActive : 26|1@1+ (1,0) [0|0] "" Vector__XXX
 SG_ DI_a220_vdcUndersteerDecelActive : 27|1@1+ (1,0) [0|0] "" Vector__XXX
 SG_ DI_a221_vdcUndersteerdMzActive : 28|1@1+ (1,0) [0|0] "" Vector__XXX
 SG_ DI_a222_vdcDisabled : 29|1@1+ (1,0) [0|0] "" Vector__XXX
 SG_ DI_a223_tractionControlDisabled : 30|1@1+ (1,0) [0|0] "" Vector__XXX
 SG_ DI_a224_brakeOverTemp : 31|1@1+ (1,0) [0|0] "" Vector__XXX
 SG_ DI_a225_tmpEstPlausibility : 32|1@1+ (1,0) [0|0] "" Vector__XXX
 SG_ DI_a226_sysStartConditionNotMet : 33|1@1+ (1,0) [0|0] "" Vector__XXX
 SG_ DI_a227_contactorsNotClosed : 34|1@1+ (1,0) [0|0] "" Vector__XXX
 SG_ DI_a228_brakeTempEstUnavailable : 35|1@1+ (1,0) [0|0] "" Vector__XXX
 SG_ DI_a229_batteryIsHeating : 36|1@1+ (1,0) [0|0] "" Vector__XXX
 SG_ DI_a230_cmpMIA : 37|1@1+ (1,0) [0|0] "" Vector__XXX
 SG_ DI_a231_ptcMIA : 38|1@1+ (1,0) [0|0] "" Vector__XXX
 SG_ DI_a232_velocityEstimatorDegraded : 39|1@1+ (1,0) [0|0] "" Vector__XXX
 SG_ DI_a233_diMsgMissed : 40|1@1+ (1,0) [0|0] "" Vector__XXX
 SG_ DI_a234_pcsMIA : 41|1@1+ (1,0) [0|0] "" Vector__XXX
 SG_ DI_a235_trackModeActive : 42|1@1+ (1,0) [0|0] "" Vector__XXX
 SG_ DI_a238_brakeOverTempBrembo : 45|1@1+ (1,0) [0|0] "" Vector__XXX
 SG_ DI_a239_neutralRequestByPM : 46|1@1+ (1,0) [0|0] "" Vector__XXX
 SG_ DI_a241_systemThermallyLimited : 48|1@1+ (1,0) [0|0] "" Vector__XXX

BO_ 861 IBST_alertMatrix: 8 CH
 SG_ IBST_matrixIndex M : 0|4@1+ (1,0) [0|0] "" Vector__XXX
 SG_ IBST_a001_microSupplyError m0 : 4|1@1+ (1,0) [0|0] "" Vector__XXX
 SG_ IBST_a002_HWBISTError m0 : 5|1@1+ (1,0) [0|0] "" Vector__XXX
 SG_ IBST_a003_RAMFault m0 : 6|1@1+ (1,0) [0|0] "" Vector__XXX
 SG_ IBST_a004_flashFault m0 : 7|1@1+ (1,0) [0|0] "" Vector__XXX
 SG_ IBST_a005_microSafetyFault m0 : 8|1@1+ (1,0) [0|0] "" Vector__XXX
 SG_ IBST_a006_microSafetyLogicFault m0 : 9|1@1+ (1,0) [0|0] "" Vector__XXX
 SG_ IBST_a007_RBCPUException m0 : 10|1@1+ (1,0) [0|0] "" Vector__XXX
 SG_ IBST_a008_stackOverUnderFlow m0 : 11|1@1+ (1,0) [0|0] "" Vector__XXX
 SG_ IBST_a009_systemErrorHook m0 : 12|1@1+ (1,0) [0|0] "" Vector__XXX
 SG_ IBST_a010_OSErrorHook m0 : 13|1@1+ (1,0) [0|0] "" Vector__XXX
 SG_ IBST_a011_systemTaskOverRun m0 : 14|1@1+ (1,0) [0|0] "" Vector__XXX
 SG_ IBST_a012_OSTaskSchemeError m0 : 15|1@1+ (1,0) [0|0] "" Vector__XXX
 SG_ IBST_a013_systemTaskJitter m0 : 16|1@1+ (1,0) [0|0] "" Vector__XXX
 SG_ IBST_a014_DMATransferError m0 : 17|1@1+ (1,0) [0|0] "" Vector__XXX
 SG_ IBST_a015_asicOscillatorError m0 : 18|1@1+ (1,0) [0|0] "" Vector__XXX
 SG_ IBST_a016_RBBLMShaftShiftError m0 : 19|1@1+ (1,0) [0|0] "" Vector__XXX
 SG_ IBST_a017_assertionFault m0 : 20|1@1+ (1,0) [0|0] "" Vector__XXX
 SG_ IBST_a018_unsupportedHW m0 : 21|1@1+ (1,0) [0|0] "" Vector__XXX
 SG_ IBST_a019_supplyASICInitFault m0 : 22|1@1+ (1,0) [0|0] "" Vector__XXX
 SG_ IBST_a020_VPREU5VOutOfRange m0 : 23|1@1+ (1,0) [0|0] "" Vector__XXX
 SG_ IBST_a021_IREFOutOfRange m0 : 24|1@1+ (1,0) [0|0] "" Vector__XXX
 SG_ IBST_a022_U5VTestFault m0 : 25|1@1+ (1,0) [0|0] "" Vector__XXX
 SG_ IBST_a023_U5VOutOfRange m0 : 26|1@1+ (1,0) [0|0] "" Vector__XXX
 SG_ IBST_a024_chargePumpFault m0 : 27|1@1+ (1,0) [0|0] "" Vector__XXX
 SG_ IBST_a025_ecuClockTestFault m0 : 28|1@1+ (1,0) [0|0] "" Vector__XXX
 SG_ IBST_a026_ecuBistCmdTestFault m0 : 29|1@1+ (1,0) [0|0] "" Vector__XXX
 SG_ IBST_a027_ecuFastWdTestFault m0 : 30|1@1+ (1,0) [0|0] "" Vector__XXX
 SG_ IBST_a028_ecuBistFaultCtrFault m0 : 31|1@1+ (1,0) [0|0] "" Vector__XXX
 SG_ IBST_a029_ecuErrpinCounterFault m0 : 32|1@1+ (1,0) [0|0] "" Vector__XXX
 SG_ IBST_a030_ecuEnableElLowFault m0 : 33|1@1+ (1,0) [0|0] "" Vector__XXX
 SG_ IBST_a031_decoupleBitTestFault m0 : 34|1@1+ (1,0) [0|0] "" Vector__XXX
 SG_ IBST_a032_ecuEnableElHighFault m0 : 35|1@1+ (1,0) [0|0] "" Vector__XXX
 SG_ IBST_a033_ecuWdStartuptestFault m0 : 36|1@1+ (1,0) [0|0] "" Vector__XXX
 SG_ IBST_a034_ecuEnableHyHighFault m0 : 37|1@1+ (1,0) [0|0] "" Vector__XXX
 SG_ IBST_a035_ecuEnableHyLowFault m0 : 38|1@1+ (1,0) [0|0] "" Vector__XXX
 SG_ IBST_a036_MRGPathTestFault m0 : 39|1@1+ (1,0) [0|0] "" Vector__XXX
 SG_ IBST_a037_ecuWdSContinuousError m0 : 40|1@1+ (1,0) [0|0] "" Vector__XXX
 SG_ IBST_a038_ecuEnContinuousError m0 : 41|1@1+ (1,0) [0|0] "" Vector__XXX
 SG_ IBST_a039_GTMRefFrequencyError m0 : 42|1@1+ (1,0) [0|0] "" Vector__XXX
 SG_ IBST_a040_GTMTbuMonError m0 : 43|1@1+ (1,0) [0|0] "" Vector__XXX
 SG_ IBST_a041_micAsicClkInError m0 : 44|1@1+ (1,0) [0|0] "" Vector__XXX
 SG_ IBST_a042_micAsicInitTestError m0 : 45|1@1+ (1,0) [0|0] "" Vector__XXX
 SG_ IBST_a043_micSpiTransferError m0 : 46|1@1+ (1,0) [0|0] "" Vector__XXX
 SG_ IBST_a044_NvMEepromWIP m0 : 47|1@1+ (1,0) [0|0] "" Vector__XXX
 SG_ IBST_a045_WdhAsicWdErrorCntStuck m0 : 48|1@1+ (1,0) [0|0] "" Vector__XXX
 SG_ IBST_a046_WdhAsicWdErrorCntLimit m0 : 49|1@1+ (1,0) [0|0] "" Vector__XXX
 SG_ IBST_a047_WdhAsicWdCmdMissing m0 : 50|1@1+ (1,0) [0|0] "" Vector__XXX
 SG_ IBST_a048_WdhSwBistConCnt m0 : 51|1@1+ (1,0) [0|0] "" Vector__XXX
 SG_ IBST_a049_WdhTaskMonConCnt m0 : 52|1@1+ (1,0) [0|0] "" Vector__XXX
 SG_ IBST_a050_VPreExternalFeeding m0 : 53|1@1+ (1,0) [0|0] "" Vector__XXX
 SG_ IBST_a051_ecuBandgap m0 : 54|1@1+ (1,0) [0|0] "" Vector__XXX
 SG_ IBST_a052_AdcPinTest m0 : 55|1@1+ (1,0) [0|0] "" Vector__XXX
 SG_ IBST_a053_AdcSelftestC5P m0 : 56|1@1+ (1,0) [0|0] "" Vector__XXX
 SG_ IBST_a054_AdcPeripheralFault m0 : 57|1@1+ (1,0) [0|0] "" Vector__XXX
 SG_ IBST_a055_UB6SupplyPathFault m0 : 58|1@1+ (1,0) [0|0] "" Vector__XXX
 SG_ IBST_a056_UB6PlausiMonFault m0 : 59|1@1+ (1,0) [0|0] "" Vector__XXX
 SG_ IBST_a057_microRegisterFault m0 : 60|1@1+ (1,0) [0|0] "" Vector__XXX
 SG_ IBST_a058_NvMWriteCycleExceed m0 : 61|1@1+ (1,0) [0|0] "" Vector__XXX
 SG_ IBST_a059_NvMEepromSize m0 : 62|1@1+ (1,0) [0|0] "" Vector__XXX
 SG_ IBST_a060_NvMMigrationFault m0 : 63|1@1+ (1,0) [0|0] "" Vector__XXX
 SG_ IBST_a061_AswSystemTimeOut m1 : 4|1@1+ (1,0) [0|0] "" Vector__XXX
 SG_ IBST_a062_MICB6TransferError m1 : 5|1@1+ (1,0) [0|0] "" Vector__XXX
 SG_ IBST_a063_tempSens2ShortToSupply m1 : 6|1@1+ (1,0) [0|0] "" Vector__XXX
 SG_ IBST_a064_tempSens1ShortToGround m1 : 7|1@1+ (1,0) [0|0] "" Vector__XXX
 SG_ IBST_a065_tempSens2ShortToGround m1 : 8|1@1+ (1,0) [0|0] "" Vector__XXX
 SG_ IBST_a066_tempSens1ShortToSupply m1 : 9|1@1+ (1,0) [0|0] "" Vector__XXX
 SG_ IBST_a067_tempSensImplausVoltage m1 : 10|1@1+ (1,0) [0|0] "" Vector__XXX
 SG_ IBST_a068_chargePumpUndervoltage m1 : 11|1@1+ (1,0) [0|0] "" Vector__XXX
 SG_ IBST_a069_greasingRoutineFault m1 : 12|1@1+ (1,0) [0|0] "" Vector__XXX
 SG_ IBST_a070_notShutDownNvMWrite m1 : 13|1@1+ (1,0) [0|0] "" Vector__XXX
 SG_ IBST_a071_notShutDownNvMRead m1 : 14|1@1+ (1,0) [0|0] "" Vector__XXX
 SG_ IBST_a072_notShutDownRight m1 : 15|1@1+ (1,0) [0|0] "" Vector__XXX
 SG_ IBST_a073_jumpInAdjustNvMRead m1 : 16|1@1+ (1,0) [0|0] "" Vector__XXX
 SG_ IBST_a074_FindIdleDataNvMWrite m1 : 17|1@1+ (1,0) [0|0] "" Vector__XXX
 SG_ IBST_a075_FindIdleRoutineFault m1 : 18|1@1+ (1,0) [0|0] "" Vector__XXX
 SG_ IBST_a076_masterCylLengthRead m1 : 19|1@1+ (1,0) [0|0] "" Vector__XXX
 SG_ IBST_a077_runOutMotorSaturated m1 : 20|1@1+ (1,0) [0|0] "" Vector__XXX
 SG_ IBST_a078_wearOffsetCompNVMRead m1 : 21|1@1+ (1,0) [0|0] "" Vector__XXX
 SG_ IBST_a079_motorTempHighLevel1 m1 : 22|1@1+ (1,0) [0|0] "" Vector__XXX
 SG_ IBST_a080_motorTempHighLevel2 m1 : 23|1@1+ (1,0) [0|0] "" Vector__XXX
 SG_ IBST_a081_travelDeviation m1 : 24|1@1+ (1,0) [0|0] "" Vector__XXX
 SG_ IBST_a082_motorSpeedDeviation m1 : 25|1@1+ (1,0) [0|0] "" Vector__XXX
 SG_ IBST_a083_spindlePositionTooHigh m1 : 26|1@1+ (1,0) [0|0] "" Vector__XXX
 SG_ IBST_a084_CANTransceiverHWFault m1 : 27|1@1+ (1,0) [0|0] "" Vector__XXX
 SG_ IBST_a085_supplyUndervoltageLvl3 m1 : 28|1@1+ (1,0) [0|0] "" Vector__XXX
 SG_ IBST_a086_supplyOvervoltageLvl3 m1 : 29|1@1+ (1,0) [0|0] "" Vector__XXX
 SG_ IBST_a087_rotorSinOutOfRangeLow m1 : 30|1@1+ (1,0) [0|0] "" Vector__XXX
 SG_ IBST_a088_rotorCosOutOfRangeLow m1 : 31|1@1+ (1,0) [0|0] "" Vector__XXX
 SG_ IBST_a089_rotorSinOutOfRangeHigh m1 : 32|1@1+ (1,0) [0|0] "" Vector__XXX
 SG_ IBST_a090_rotorCosOutOfRangeHigh m1 : 33|1@1+ (1,0) [0|0] "" Vector__XXX
 SG_ IBST_a091_SMMOneRequestsInit m1 : 34|1@1+ (1,0) [0|0] "" Vector__XXX
 SG_ IBST_a092_systemStartTimeOut m1 : 35|1@1+ (1,0) [0|0] "" Vector__XXX
 SG_ IBST_a093_UEXSOvertemperature m1 : 36|1@1+ (1,0) [0|0] "" Vector__XXX
 SG_ IBST_a094_XPASSEchoTimeDeviation m1 : 37|1@1+ (1,0) [0|0] "" Vector__XXX
 SG_ IBST_a095_XPASSTimeOut m1 : 38|1@1+ (1,0) [0|0] "" Vector__XXX
 SG_ IBST_a096_bridgeDriverMonError m1 : 39|1@1+ (1,0) [0|0] "" Vector__XXX
 SG_ IBST_a097_bridgeDriverError m1 : 40|1@1+ (1,0) [0|0] "" Vector__XXX
 SG_ IBST_a098_bridgeShortedPhase m1 : 41|1@1+ (1,0) [0|0] "" Vector__XXX
 SG_ IBST_a099_bridgeSwitchInitError m1 : 42|1@1+ (1,0) [0|0] "" Vector__XXX
 SG_ IBST_a100_current2OffsVEHigh m1 : 43|1@1+ (1,0) [0|0] "" Vector__XXX
 SG_ IBST_a101_current2OffsetLow m1 : 44|1@1+ (1,0) [0|0] "" Vector__XXX
 SG_ IBST_a102_current1OffsVEHigh m1 : 45|1@1+ (1,0) [0|0] "" Vector__XXX
 SG_ IBST_a103_current1OffsetLow m1 : 46|1@1+ (1,0) [0|0] "" Vector__XXX
 SG_ IBST_a104_bridgeDriverShort m1 : 47|1@1+ (1,0) [0|0] "" Vector__XXX
 SG_ IBST_a105_LiPSUndervoltage m1 : 48|1@1+ (1,0) [0|0] "" Vector__XXX
 SG_ IBST_a106_LiPS5VSupply m1 : 49|1@1+ (1,0) [0|0] "" Vector__XXX
 SG_ IBST_a107_LiPS2PwmLineHigh m1 : 50|1@1+ (1,0) [0|0] "" Vector__XXX
 SG_ IBST_a108_LiPS2PwmLineLow m1 : 51|1@1+ (1,0) [0|0] "" Vector__XXX
 SG_ IBST_a109_LiPS2PwmTransmission m1 : 52|1@1+ (1,0) [0|0] "" Vector__XXX
 SG_ IBST_a110_LiPS1SentLineHigh m1 : 53|1@1+ (1,0) [0|0] "" Vector__XXX
 SG_ IBST_a111_LiPS1SentLineLow m1 : 54|1@1+ (1,0) [0|0] "" Vector__XXX
 SG_ IBST_a112_LiPS1SentTransmission m1 : 55|1@1+ (1,0) [0|0] "" Vector__XXX
 SG_ IBST_a113_LiPS1SentSensor m1 : 56|1@1+ (1,0) [0|0] "" Vector__XXX
 SG_ IBST_a114_partyBusOff m1 : 57|1@1+ (1,0) [0|0] "" Vector__XXX
 SG_ IBST_a115_CHOff m1 : 58|1@1+ (1,0) [0|0] "" Vector__XXX
 SG_ IBST_a116_supplyUndervoltageLvl2 m1 : 59|1@1+ (1,0) [0|0] "" Vector__XXX
 SG_ IBST_a117_supplyOvervoltageLvl2 m1 : 60|1@1+ (1,0) [0|0] "" Vector__XXX
 SG_ IBST_a118_RPSNvMReadFault m1 : 61|1@1+ (1,0) [0|0] "" Vector__XXX
 SG_ IBST_a119_RPSWrongCalibData m1 : 62|1@1+ (1,0) [0|0] "" Vector__XXX
 SG_ IBST_a120_RPSVectorRangeHigh m1 : 63|1@1+ (1,0) [0|0] "" Vector__XXX
 SG_ IBST_a121_RPSVectorRangeLow m2 : 4|1@1+ (1,0) [0|0] "" Vector__XXX
 SG_ IBST_a122_RPSVectorOscillating m2 : 5|1@1+ (1,0) [0|0] "" Vector__XXX
 SG_ IBST_a123_bridgeDriverUnavail m2 : 6|1@1+ (1,0) [0|0] "" Vector__XXX
 SG_ IBST_a124_OBDCurrent1OORHigh m2 : 7|1@1+ (1,0) [0|0] "" Vector__XXX
 SG_ IBST_a125_OBDCurrent2OORHigh m2 : 8|1@1+ (1,0) [0|0] "" Vector__XXX
 SG_ IBST_a126_OBDCurrent1OORLow m2 : 9|1@1+ (1,0) [0|0] "" Vector__XXX
 SG_ IBST_a127_OBDCurrent2OORLow m2 : 10|1@1+ (1,0) [0|0] "" Vector__XXX
 SG_ IBST_a128_BLMMuxerTimeoutError m2 : 11|1@1+ (1,0) [0|0] "" Vector__XXX
 SG_ IBST_a129_loadDumpOnFSLTest m2 : 12|1@1+ (1,0) [0|0] "" Vector__XXX
 SG_ IBST_a130_DTSFunctionalRangeLow m2 : 13|1@1+ (1,0) [0|0] "" Vector__XXX
 SG_ IBST_a131_DTSFunctionalRangeHigh m2 : 14|1@1+ (1,0) [0|0] "" Vector__XXX
 SG_ IBST_a132_DTSPlausiCheck1vs2 m2 : 15|1@1+ (1,0) [0|0] "" Vector__XXX
 SG_ IBST_a133_DTSOffsetTooLow m2 : 16|1@1+ (1,0) [0|0] "" Vector__XXX
 SG_ IBST_a134_DTSOffsetTooHigh m2 : 17|1@1+ (1,0) [0|0] "" Vector__XXX
 SG_ IBST_a135_ESPparty1DLC m2 : 18|1@1+ (1,0) [0|0] "" Vector__XXX
 SG_ IBST_a136_ESPparty1Timeout m2 : 19|1@1+ (1,0) [0|0] "" Vector__XXX
 SG_ IBST_a137_ESPparty1Checksum m2 : 20|1@1+ (1,0) [0|0] "" Vector__XXX
 SG_ IBST_a138_ESPparty1Counter m2 : 21|1@1+ (1,0) [0|0] "" Vector__XXX
 SG_ IBST_a139_ESPparty2DLC m2 : 22|1@1+ (1,0) [0|0] "" Vector__XXX
 SG_ IBST_a140_ESPparty2Timeout m2 : 23|1@1+ (1,0) [0|0] "" Vector__XXX
 SG_ IBST_a141_ESPparty2Checksum m2 : 24|1@1+ (1,0) [0|0] "" Vector__XXX
 SG_ IBST_a142_ESPparty2Counter m2 : 25|1@1+ (1,0) [0|0] "" Vector__XXX
 SG_ IBST_a143_ESPparty3DLC m2 : 26|1@1+ (1,0) [0|0] "" Vector__XXX
 SG_ IBST_a144_ESPparty3Timeout m2 : 27|1@1+ (1,0) [0|0] "" Vector__XXX
 SG_ IBST_a145_ESPparty3Checksum m2 : 28|1@1+ (1,0) [0|0] "" Vector__XXX
 SG_ IBST_a146_ESPparty3Counter m2 : 29|1@1+ (1,0) [0|0] "" Vector__XXX
 SG_ IBST_a147_PSCMotorSizeReadFault m2 : 30|1@1+ (1,0) [0|0] "" Vector__XXX
 SG_ IBST_a148_MLIGainMechReadFault m2 : 31|1@1+ (1,0) [0|0] "" Vector__XXX
 SG_ IBST_a149_MLITMCAreaReadFault m2 : 32|1@1+ (1,0) [0|0] "" Vector__XXX
 SG_ IBST_a150_motorTestFault m2 : 33|1@1+ (1,0) [0|0] "" Vector__XXX
 SG_ IBST_a151_PSCGearRatioReadFault m2 : 34|1@1+ (1,0) [0|0] "" Vector__XXX
 SG_ IBST_a152_PSCVoltageImplausible m2 : 35|1@1+ (1,0) [0|0] "" Vector__XXX
 SG_ IBST_a153_PSCImpedanceTooHigh m2 : 36|1@1+ (1,0) [0|0] "" Vector__XXX
 SG_ IBST_a154_PSCImpedanceTooLow m2 : 37|1@1+ (1,0) [0|0] "" Vector__XXX
 SG_ IBST_a155_supplyUndervoltageLvl1 m2 : 38|1@1+ (1,0) [0|0] "" Vector__XXX
 SG_ IBST_a156_supplyOvervoltageLvl1 m2 : 39|1@1+ (1,0) [0|0] "" Vector__XXX
 SG_ IBST_a157_masterCylPressInvalid m2 : 40|1@1+ (1,0) [0|0] "" Vector__XXX
 SG_ IBST_a158_DTSOffsHighSuspicious m2 : 41|1@1+ (1,0) [0|0] "" Vector__XXX
 SG_ IBST_a159_FindIdleNvMReadError m2 : 42|1@1+ (1,0) [0|0] "" Vector__XXX
 SG_ IBST_a160_DTSIDTimeOut m2 : 43|1@1+ (1,0) [0|0] "" Vector__XXX
 SG_ IBST_a161_powerPackMismatch m2 : 44|1@1+ (1,0) [0|0] "" Vector__XXX
 SG_ IBST_a162_idlePosNotDetected m2 : 45|1@1+ (1,0) [0|0] "" Vector__XXX
 SG_ IBST_a163_ESPpEstMaxInvalid m2 : 46|1@1+ (1,0) [0|0] "" Vector__XXX
 SG_ IBST_a164_ESPVehicleSpeedInvalid m2 : 47|1@1+ (1,0) [0|0] "" Vector__XXX
 SG_ IBST_a165_ESPpForceBlendInvalid m2 : 48|1@1+ (1,0) [0|0] "" Vector__XXX
 SG_ IBST_a166_ESPpMcVirtualInvalid m2 : 49|1@1+ (1,0) [0|0] "" Vector__XXX
 SG_ IBST_a167_ESPqTargetExterInvalid m2 : 50|1@1+ (1,0) [0|0] "" Vector__XXX
 SG_ IBST_a168_CANOvervoltage m2 : 51|1@1+ (1,0) [0|0] "" Vector__XXX
 SG_ IBST_a169_CANUndervoltage m2 : 52|1@1+ (1,0) [0|0] "" Vector__XXX
 SG_ IBST_a170_LVPowerStateTimeout m2 : 53|1@1+ (1,0) [0|0] "" Vector__XXX
 SG_ IBST_a171_LVPowerStateChecksum m2 : 54|1@1+ (1,0) [0|0] "" Vector__XXX
 SG_ IBST_a172_LVPowerStateDLC m2 : 55|1@1+ (1,0) [0|0] "" Vector__XXX
 SG_ IBST_a173_LVPowerStateCounter m2 : 56|1@1+ (1,0) [0|0] "" Vector__XXX
 SG_ IBST_a174_LVOffStateInvalid m2 : 57|1@1+ (1,0) [0|0] "" Vector__XXX
 SG_ IBST_a175_LVGoingDownInvalid m2 : 58|1@1+ (1,0) [0|0] "" Vector__XXX

BO_ 862 PARK_pasRearMiddle: 5 CH
 SG_ PARK_pasRearMiddleChecksum : 32|8@1+ (1,0) [0|0] "" Vector__XXX
 SG_ PARK_pasRearMiddleCounter : 24|4@1+ (1,0) [0|0] "" Vector__XXX
 SG_ PARK_rearLeftMiddleRawDistData : 0|8@1+ (1,0) [0|0] "cm" Vector__XXX
 SG_ PARK_rearMiddleRawDistData : 8|8@1+ (1,0) [0|0] "cm" Vector__XXX
 SG_ PARK_rearRightMiddleRawDistData : 16|8@1+ (1,0) [0|0] "cm" Vector__XXX

BO_ 864 VCLEFT_alertMatrix: 8 VEH
 SG_ VCLEFT_matrixIndex M : 0|4@1+ (1,0) [0|0] "" Vector__XXX
 SG_ VCLEFT_a001_WatchdogReset m0 : 4|1@1+ (1,0) [0|0] "" Vector__XXX
 SG_ VCLEFT_a002_PowerLossReset m0 : 5|1@1+ (1,0) [0|0] "" Vector__XXX
 SG_ VCLEFT_a003_SWAssertion m0 : 6|1@1+ (1,0) [0|0] "" Vector__XXX
 SG_ VCLEFT_a010_ExtSupplyVoltError m0 : 13|1@1+ (1,0) [0|0] "" Vector__XXX
 SG_ VCLEFT_a012_CPUReset m0 : 15|1@1+ (1,0) [0|0] "" Vector__XXX
 SG_ VCLEFT_a013_AlertManagerFault m0 : 16|1@1+ (1,0) [0|0] "" Vector__XXX
 SG_ VCLEFT_a015_NVMMAlert m0 : 18|1@1+ (1,0) [0|0] "" Vector__XXX
 SG_ VCLEFT_a021_TaskSchedulerError m0 : 24|1@1+ (1,0) [0|0] "" Vector__XXX
 SG_ VCLEFT_a022_TaskInitError m0 : 25|1@1+ (1,0) [0|0] "" Vector__XXX
 SG_ VCLEFT_a031_UDSActive m0 : 34|1@1+ (1,0) [0|0] "" Vector__XXX
 SG_ VCLEFT_a041_HighCPULoad m0 : 44|1@1+ (1,0) [0|0] "" Vector__XXX
 SG_ VCLEFT_a042_HighStackUsage m0 : 45|1@1+ (1,0) [0|0] "" Vector__XXX
 SG_ VCLEFT_a043_Task1msError m0 : 46|1@1+ (1,0) [0|0] "" Vector__XXX
 SG_ VCLEFT_a044_Task10msError m0 : 47|1@1+ (1,0) [0|0] "" Vector__XXX
 SG_ VCLEFT_a045_Task100msError m0 : 48|1@1+ (1,0) [0|0] "" Vector__XXX
 SG_ VCLEFT_a046_Task1000msError m0 : 49|1@1+ (1,0) [0|0] "" Vector__XXX
 SG_ VCLEFT_a059_inputResistanceHigh m0 : 62|1@1+ (1,0) [0|0] "" Vector__XXX
 SG_ VCLEFT_a060_engineeringBuild m0 : 63|1@1+ (1,0) [0|0] "" Vector__XXX
 SG_ VCLEFT_a061_XCPConnected m1 : 4|1@1+ (1,0) [0|0] "" Vector__XXX
 SG_ VCLEFT_a062_XCPWasConnected m1 : 5|1@1+ (1,0) [0|0] "" Vector__XXX
 SG_ VCLEFT_a063_SwitchFault m1 : 6|1@1+ (1,0) [0|0] "" Vector__XXX
 SG_ VCLEFT_a064_busSleepReqTimeout m1 : 7|1@1+ (1,0) [0|0] "" Vector__XXX
 SG_ VCLEFT_a097_CMP_MIA m1 : 40|1@1+ (1,0) [0|0] "" Vector__XXX
 SG_ VCLEFT_a098_DI_THERMAL_MIA m1 : 41|1@1+ (1,0) [0|0] "" Vector__XXX
 SG_ VCLEFT_a099_PARK_MIA m1 : 42|1@1+ (1,0) [0|0] "" Vector__XXX
 SG_ VCLEFT_a100_CANbus_MIA m1 : 43|1@1+ (1,0) [0|0] "" Vector__XXX
 SG_ VCLEFT_a101_PM_MIA m1 : 44|1@1+ (1,0) [0|0] "" Vector__XXX
 SG_ VCLEFT_a102_PTC_MIA m1 : 45|1@1+ (1,0) [0|0] "" Vector__XXX
 SG_ VCLEFT_a103_CP_MIA m1 : 46|1@1+ (1,0) [0|0] "" Vector__XXX
 SG_ VCLEFT_a104_DAS_MIA m1 : 47|1@1+ (1,0) [0|0] "" Vector__XXX
 SG_ VCLEFT_a105_TAS_MIA m1 : 48|1@1+ (1,0) [0|0] "" Vector__XXX
 SG_ VCLEFT_a106_PCS_MIA m1 : 49|1@1+ (1,0) [0|0] "" Vector__XXX
 SG_ VCLEFT_a107_BMS_MIA m1 : 50|1@1+ (1,0) [0|0] "" Vector__XXX
 SG_ VCLEFT_a108_DIS_MIA m1 : 51|1@1+ (1,0) [0|0] "" Vector__XXX
 SG_ VCLEFT_a109_RCM_MIA m1 : 52|1@1+ (1,0) [0|0] "" Vector__XXX
 SG_ VCLEFT_a110_GTW_MIA m1 : 53|1@1+ (1,0) [0|0] "" Vector__XXX
 SG_ VCLEFT_a111_EPBR_MIA m1 : 54|1@1+ (1,0) [0|0] "" Vector__XXX
 SG_ VCLEFT_a112_EPBL_MIA m1 : 55|1@1+ (1,0) [0|0] "" Vector__XXX
 SG_ VCLEFT_a113_UI_MIA m1 : 56|1@1+ (1,0) [0|0] "" Vector__XXX
 SG_ VCLEFT_a114_ESP_MIA m1 : 57|1@1+ (1,0) [0|0] "" Vector__XXX
 SG_ VCLEFT_a115_VCSEC_MIA m1 : 58|1@1+ (1,0) [0|0] "" Vector__XXX
 SG_ VCLEFT_a116_VCRIGHT_MIA m1 : 59|1@1+ (1,0) [0|0] "" Vector__XXX
 SG_ VCLEFT_a117_VCLEFT_MIA m1 : 60|1@1+ (1,0) [0|0] "" Vector__XXX
 SG_ VCLEFT_a118_VCFRONT_MIA m1 : 61|1@1+ (1,0) [0|0] "" Vector__XXX
 SG_ VCLEFT_a119_SCCM_MIA m1 : 62|1@1+ (1,0) [0|0] "" Vector__XXX
 SG_ VCLEFT_a120_DI_DRIVE_MIA m1 : 63|1@1+ (1,0) [0|0] "" Vector__XXX
 SG_ VCLEFT_a129_blowerICLatchFault m2 : 12|1@1+ (1,0) [0|0] "" Vector__XXX
 SG_ VCLEFT_a130_blowerICWarning m2 : 13|1@1+ (1,0) [0|0] "" Vector__XXX
 SG_ VCLEFT_a131_blowerICTransFault m2 : 14|1@1+ (1,0) [0|0] "" Vector__XXX
 SG_ VCLEFT_a132_blowerSoftStall m2 : 15|1@1+ (1,0) [0|0] "" Vector__XXX
 SG_ VCLEFT_a133_blowerLowRPMCBang m2 : 16|1@1+ (1,0) [0|0] "" Vector__XXX
 SG_ VCLEFT_a134_SteerColUpDownUnCal m2 : 17|1@1+ (1,0) [0|0] "" Vector__XXX
 SG_ VCLEFT_a135_SteerColInOutUnCal m2 : 18|1@1+ (1,0) [0|0] "" Vector__XXX
 SG_ VCLEFT_a136_brakeSwitchMismatch m2 : 19|1@1+ (1,0) [0|0] "" Vector__XXX
 SG_ VCLEFT_a137_VCSECPowerCycled m2 : 20|1@1+ (1,0) [0|0] "" Vector__XXX
 SG_ VCLEFT_a138_consoleDoorAssist m2 : 21|1@1+ (1,0) [0|0] "" Vector__XXX
 SG_ VCLEFT_a139_BLERearPowerCycled m2 : 22|1@1+ (1,0) [0|0] "" Vector__XXX
 SG_ VCLEFT_a140_BLELeftPowerCycled m2 : 23|1@1+ (1,0) [0|0] "" Vector__XXX
 SG_ VCLEFT_a141_12VAuxPowerTrip m2 : 24|1@1+ (1,0) [0|0] "" Vector__XXX
 SG_ VCLEFT_a150_windowPinchFront m2 : 33|1@1+ (1,0) [0|0] "" Vector__XXX
 SG_ VCLEFT_a151_windowPinchRear m2 : 34|1@1+ (1,0) [0|0] "" Vector__XXX
 SG_ VCLEFT_a152_windowUncalFront m2 : 35|1@1+ (1,0) [0|0] "" Vector__XXX
 SG_ VCLEFT_a153_windowUncalRear m2 : 36|1@1+ (1,0) [0|0] "" Vector__XXX
 SG_ VCLEFT_a154_windowThermalFront m2 : 37|1@1+ (1,0) [0|0] "" Vector__XXX
 SG_ VCLEFT_a155_windowThermalRear m2 : 38|1@1+ (1,0) [0|0] "" Vector__XXX
 SG_ VCLEFT_a156_windowNoInputFront m2 : 39|1@1+ (1,0) [0|0] "" Vector__XXX
 SG_ VCLEFT_a157_windowNoInputRear m2 : 40|1@1+ (1,0) [0|0] "" Vector__XXX
 SG_ VCLEFT_a158_windowPinchOverideF m2 : 41|1@1+ (1,0) [0|0] "" Vector__XXX
 SG_ VCLEFT_a159_windowPinchOverideR m2 : 42|1@1+ (1,0) [0|0] "" Vector__XXX
 SG_ VCLEFT_a160_windowUndercurrentF m2 : 43|1@1+ (1,0) [0|0] "" Vector__XXX
 SG_ VCLEFT_a161_windowUndercurrentR m2 : 44|1@1+ (1,0) [0|0] "" Vector__XXX
 SG_ VCLEFT_a162_windowEncoderStallF m2 : 45|1@1+ (1,0) [0|0] "" Vector__XXX
 SG_ VCLEFT_a163_windowEncoderStallR m2 : 46|1@1+ (1,0) [0|0] "" Vector__XXX
 SG_ VCLEFT_a164_windowFactoryTest m2 : 47|1@1+ (1,0) [0|0] "" Vector__XXX
 SG_ VCLEFT_a165_windowFactoryTest2 m2 : 48|1@1+ (1,0) [0|0] "" Vector__XXX
 SG_ VCLEFT_a166_windowDebug m2 : 49|1@1+ (1,0) [0|0] "" Vector__XXX
 SG_ VCLEFT_a167_windowDebugPinchF m2 : 50|1@1+ (1,0) [0|0] "" Vector__XXX
 SG_ VCLEFT_a168_windowDebugPinchR m2 : 51|1@1+ (1,0) [0|0] "" Vector__XXX
 SG_ VCLEFT_a169_windowCurrentPeakF m2 : 52|1@1+ (1,0) [0|0] "" Vector__XXX
 SG_ VCLEFT_a170_windowCurrentPeakR m2 : 53|1@1+ (1,0) [0|0] "" Vector__XXX
 SG_ VCLEFT_a172_SPI_MIA m2 : 55|1@1+ (1,0) [0|0] "" Vector__XXX
 SG_ VCLEFT_a180_frontDoorLatchRehome m2 : 63|1@1+ (1,0) [0|0] "" Vector__XXX
 SG_ VCLEFT_a181_rearDoorLatchRehome m3 : 4|1@1+ (1,0) [0|0] "" Vector__XXX
 SG_ VCLEFT_a182_emergencyLatchRel m3 : 5|1@1+ (1,0) [0|0] "" Vector__XXX
 SG_ VCLEFT_a183_doorStateFactoryTest m3 : 6|1@1+ (1,0) [0|0] "" Vector__XXX
 SG_ VCLEFT_a185_summonAborted m3 : 8|1@1+ (1,0) [0|0] "" Vector__XXX
 SG_ VCLEFT_a186_latchReleaseFailedF m3 : 9|1@1+ (1,0) [0|0] "" Vector__XXX
 SG_ VCLEFT_a187_latchReleaseFailedR m3 : 10|1@1+ (1,0) [0|0] "" Vector__XXX
 SG_ VCLEFT_a188_latchUnableToRearmF m3 : 11|1@1+ (1,0) [0|0] "" Vector__XXX
 SG_ VCLEFT_a189_latchUnableToRearmR m3 : 12|1@1+ (1,0) [0|0] "" Vector__XXX
 SG_ VCLEFT_a190_eFuseMgmtVbatFused m3 : 13|1@1+ (1,0) [0|0] "" Vector__XXX
 SG_ VCLEFT_a191_TLCOvercurrent m3 : 14|1@1+ (1,0) [0|0] "" Vector__XXX
 SG_ VCLEFT_a196_VEHCANOverterminate m3 : 19|1@1+ (1,0) [0|0] "" Vector__XXX
 SG_ VCLEFT_a197_VEHCANUndertrminate m3 : 20|1@1+ (1,0) [0|0] "" Vector__XXX
 SG_ VCLEFT_a200_motorPhantomEncoder m3 : 23|1@1+ (1,0) [0|0] "" Vector__XXX
 SG_ VCLEFT_a201_motorDutyEncDisabl m3 : 24|1@1+ (1,0) [0|0] "" Vector__XXX
 SG_ VCLEFT_a202_epbmUnderIStatic m3 : 25|1@1+ (1,0) [0|0] "" Vector__XXX
 SG_ VCLEFT_a203_epbmOverIStatic m3 : 26|1@1+ (1,0) [0|0] "" Vector__XXX
 SG_ VCLEFT_a204_epbmUnderIDyn m3 : 27|1@1+ (1,0) [0|0] "" Vector__XXX
 SG_ VCLEFT_a205_epbmOverIDyn m3 : 28|1@1+ (1,0) [0|0] "" Vector__XXX
 SG_ VCLEFT_a206_epbWrongDirection m3 : 29|1@1+ (1,0) [0|0] "" Vector__XXX
 SG_ VCLEFT_a207_epbmEnableWrong m3 : 30|1@1+ (1,0) [0|0] "" Vector__XXX
 SG_ VCLEFT_a208_epbFaulted m3 : 31|1@1+ (1,0) [0|0] "" Vector__XXX
 SG_ VCLEFT_a209_epbStateMisTime m3 : 32|1@1+ (1,0) [0|0] "" Vector__XXX
 SG_ VCLEFT_a210_epbStateTime m3 : 33|1@1+ (1,0) [0|0] "" Vector__XXX
 SG_ VCLEFT_a211_epbmUnderIStaticNew m3 : 34|1@1+ (1,0) [0|0] "" Vector__XXX
 SG_ VCLEFT_a212_epbmOverIStaticNew m3 : 35|1@1+ (1,0) [0|0] "" Vector__XXX
 SG_ VCLEFT_a213_epbmUnderIDynNew m3 : 36|1@1+ (1,0) [0|0] "" Vector__XXX
 SG_ VCLEFT_a214_epbmOverIDynNew m3 : 37|1@1+ (1,0) [0|0] "" Vector__XXX
 SG_ VCLEFT_a215_currentDesyncWarning m3 : 38|1@1+ (1,0) [0|0] "" Vector__XXX
 SG_ VCLEFT_a216_SPI_MIA_debugData1 m3 : 39|1@1+ (1,0) [0|0] "" Vector__XXX
 SG_ VCLEFT_a217_SPI_MIA_debugData2 m3 : 40|1@1+ (1,0) [0|0] "" Vector__XXX
 SG_ VCLEFT_a218_motorDriverFault m3 : 41|1@1+ (1,0) [0|0] "" Vector__XXX
 SG_ VCLEFT_a219_motorCurrentDropout m3 : 42|1@1+ (1,0) [0|0] "" Vector__XXX
 SG_ VCLEFT_a220_seatCurrStallTrack m3 : 43|1@1+ (1,0) [0|0] "" Vector__XXX
 SG_ VCLEFT_a221_seatCurrStallBack m3 : 44|1@1+ (1,0) [0|0] "" Vector__XXX
 SG_ VCLEFT_a222_seatCurrStallTilt m3 : 45|1@1+ (1,0) [0|0] "" Vector__XXX
 SG_ VCLEFT_a223_seatCurrStallLift m3 : 46|1@1+ (1,0) [0|0] "" Vector__XXX
 SG_ VCLEFT_a224_seatEncStallTrack m3 : 47|1@1+ (1,0) [0|0] "" Vector__XXX
 SG_ VCLEFT_a225_seatEncStallBack m3 : 48|1@1+ (1,0) [0|0] "" Vector__XXX
 SG_ VCLEFT_a226_seatEncStallTilt m3 : 49|1@1+ (1,0) [0|0] "" Vector__XXX
 SG_ VCLEFT_a227_seatEncStallLift m3 : 50|1@1+ (1,0) [0|0] "" Vector__XXX
 SG_ VCLEFT_a228_seatEncOverTrack m3 : 51|1@1+ (1,0) [0|0] "" Vector__XXX
 SG_ VCLEFT_a229_seatEncOverBack m3 : 52|1@1+ (1,0) [0|0] "" Vector__XXX
 SG_ VCLEFT_a230_seatEncOverTilt m3 : 53|1@1+ (1,0) [0|0] "" Vector__XXX
 SG_ VCLEFT_a231_seatEncOverLift m3 : 54|1@1+ (1,0) [0|0] "" Vector__XXX
 SG_ VCLEFT_a232_seatCurrUnderTrack m3 : 55|1@1+ (1,0) [0|0] "" Vector__XXX
 SG_ VCLEFT_a233_seatCurrUnderBack m3 : 56|1@1+ (1,0) [0|0] "" Vector__XXX
 SG_ VCLEFT_a234_seatCurrUnderTilt m3 : 57|1@1+ (1,0) [0|0] "" Vector__XXX
 SG_ VCLEFT_a235_seatCurrUnderLift m3 : 58|1@1+ (1,0) [0|0] "" Vector__XXX
 SG_ VCLEFT_a236_lumbarOverPresA m3 : 59|1@1+ (1,0) [0|0] "" Vector__XXX
 SG_ VCLEFT_a237_lumbarOverPresB m3 : 60|1@1+ (1,0) [0|0] "" Vector__XXX
 SG_ VCLEFT_a238_lumbarValveMIA m3 : 61|1@1+ (1,0) [0|0] "" Vector__XXX
 SG_ VCLEFT_a239_seatHeatIFront m3 : 62|1@1+ (1,0) [0|0] "" Vector__XXX
 SG_ VCLEFT_a240_seatHeatShortFront m3 : 63|1@1+ (1,0) [0|0] "" Vector__XXX
 SG_ VCLEFT_a241_seatHeatMIAFront m4 : 4|1@1+ (1,0) [0|0] "" Vector__XXX
 SG_ VCLEFT_a242_seatHeatIRearL m4 : 5|1@1+ (1,0) [0|0] "" Vector__XXX
 SG_ VCLEFT_a243_seatHeatShortRearL m4 : 6|1@1+ (1,0) [0|0] "" Vector__XXX
 SG_ VCLEFT_a244_seatHeatMIARearL m4 : 7|1@1+ (1,0) [0|0] "" Vector__XXX
 SG_ VCLEFT_a251_seatUncalTrack m4 : 14|1@1+ (1,0) [0|0] "" Vector__XXX
 SG_ VCLEFT_a252_seatUncalBack m4 : 15|1@1+ (1,0) [0|0] "" Vector__XXX
 SG_ VCLEFT_a253_seatUncalTilt m4 : 16|1@1+ (1,0) [0|0] "" Vector__XXX
 SG_ VCLEFT_a254_seatUncalLift m4 : 17|1@1+ (1,0) [0|0] "" Vector__XXX
 SG_ VCLEFT_a259_latchDisarmDelayF m4 : 22|1@1+ (1,0) [0|0] "" Vector__XXX
 SG_ VCLEFT_a260_latchDisarmDelayR m4 : 23|1@1+ (1,0) [0|0] "" Vector__XXX
 SG_ VCLEFT_a263_seatTrackStallDebug m4 : 26|1@1+ (1,0) [0|0] "" Vector__XXX
 SG_ VCLEFT_a264_seatBackStallDebug m4 : 27|1@1+ (1,0) [0|0] "" Vector__XXX
 SG_ VCLEFT_a265_seatTiltStallDebug m4 : 28|1@1+ (1,0) [0|0] "" Vector__XXX
 SG_ VCLEFT_a266_seatLiftStallDebug m4 : 29|1@1+ (1,0) [0|0] "" Vector__XXX
 SG_ VCLEFT_a267_seatTrackHCEncStlDbg m4 : 30|1@1+ (1,0) [0|0] "" Vector__XXX
 SG_ VCLEFT_a268_seatBackHCEncStlDbg m4 : 31|1@1+ (1,0) [0|0] "" Vector__XXX
 SG_ VCLEFT_a269_seatTiltHCEncStlDbg m4 : 32|1@1+ (1,0) [0|0] "" Vector__XXX
 SG_ VCLEFT_a270_seatLiftHCEncStlDbg m4 : 33|1@1+ (1,0) [0|0] "" Vector__XXX
 SG_ VCLEFT_a272_vhclPwrStateMsmtch m4 : 35|1@1+ (1,0) [0|0] "" Vector__XXX
 SG_ VCLEFT_a273_handleStuckActiveF m4 : 36|1@1+ (1,0) [0|0] "" Vector__XXX
 SG_ VCLEFT_a274_handleStuckActiveR m4 : 37|1@1+ (1,0) [0|0] "" Vector__XXX
 SG_ VCLEFT_a275_leftTurnLightFault m4 : 38|1@1+ (1,0) [0|0] "" Vector__XXX
 SG_ VCLEFT_a276_mirrorDebug m4 : 39|1@1+ (1,0) [0|0] "" Vector__XXX
 SG_ VCLEFT_a277_BLELeftUnderVoltage m4 : 40|1@1+ (1,0) [0|0] "" Vector__XXX
 SG_ VCLEFT_a278_BLERearUnderVoltage m4 : 41|1@1+ (1,0) [0|0] "" Vector__XXX
 SG_ VCLEFT_a279_VCSECUnderVoltage m4 : 42|1@1+ (1,0) [0|0] "" Vector__XXX
 SG_ VCLEFT_a280_latchDidNotDisarmF m4 : 43|1@1+ (1,0) [0|0] "" Vector__XXX
 SG_ VCLEFT_a281_latchDidNotDisarmR m4 : 44|1@1+ (1,0) [0|0] "" Vector__XXX
 SG_ VCLEFT_a282_latchUnexpectedArmF m4 : 45|1@1+ (1,0) [0|0] "" Vector__XXX
 SG_ VCLEFT_a283_latchUnexpectedArmR m4 : 46|1@1+ (1,0) [0|0] "" Vector__XXX
 SG_ VCLEFT_a284_blowerFbkSanity m4 : 47|1@1+ (1,0) [0|0] "" Vector__XXX
 SG_ VCLEFT_a285_blowerChipComms m4 : 48|1@1+ (1,0) [0|0] "" Vector__XXX
 SG_ VCLEFT_a286_windowSpeedInvalidF m4 : 49|1@1+ (1,0) [0|0] "" Vector__XXX
 SG_ VCLEFT_a287_windowSpeedInvalidR m4 : 50|1@1+ (1,0) [0|0] "" Vector__XXX
 SG_ VCLEFT_a290_occupancyFaultedFront m4 : 53|1@1+ (1,0) [0|0] "" Vector__XXX
 SG_ VCLEFT_a291_buckleFaultedFront m4 : 54|1@1+ (1,0) [0|0] "" Vector__XXX
 SG_ VCLEFT_a292_occupancyFaultedRearL m4 : 55|1@1+ (1,0) [0|0] "" Vector__XXX
 SG_ VCLEFT_a293_occupancyFaultedRearC m4 : 56|1@1+ (1,0) [0|0] "" Vector__XXX
 SG_ VCLEFT_a294_occupancyFaultedRearR m4 : 57|1@1+ (1,0) [0|0] "" Vector__XXX
 SG_ VCLEFT_a295_buckleFaultedRearL m4 : 58|1@1+ (1,0) [0|0] "" Vector__XXX
 SG_ VCLEFT_a300_swcUnderVoltage m4 : 63|1@1+ (1,0) [0|0] "" Vector__XXX
 SG_ VCLEFT_a301_swcOverVoltage m5 : 4|1@1+ (1,0) [0|0] "" Vector__XXX
 SG_ VCLEFT_a302_blowerGeneralFault m5 : 5|1@1+ (1,0) [0|0] "" Vector__XXX
 SG_ VCLEFT_a303_eFuseMgmtWindowLift m5 : 6|1@1+ (1,0) [0|0] "" Vector__XXX
 SG_ VCLEFT_a304_frontIntHandleShorted m5 : 7|1@1+ (1,0) [0|0] "" Vector__XXX
 SG_ VCLEFT_a305_rearIntHandleShorted m5 : 8|1@1+ (1,0) [0|0] "" Vector__XXX
 SG_ VCLEFT_a306_handleDisconnectedF m5 : 9|1@1+ (1,0) [0|0] "" Vector__XXX
 SG_ VCLEFT_a307_handleDisconnectedR m5 : 10|1@1+ (1,0) [0|0] "" Vector__XXX

BO_ 867 CMP_info: 8 VEH
 SG_ CMP_infoIndex M : 0|8@1+ (1,0) [0|0] "" Vector__XXX
 SG_ CMP_infoBuildType m10 : 8|8@1+ (1,0) [0|0] "" Vector__XXX
 SG_ CMP_infoBuildConfigId m10 : 16|16@1+ (1,0) [0|0] "" Vector__XXX
 SG_ CMP_infoHardwareId m10 : 32|16@1+ (1,0) [0|0] "" Vector__XXX
 SG_ CMP_infoComponentId m10 : 48|16@1+ (1,0) [0|0] "" Vector__XXX
 SG_ CMP_infoPcbaId m11 : 16|8@1+ (1,0) [0|0] "" Vector__XXX
 SG_ CMP_infoAssemblyId m11 : 24|8@1+ (1,0) [0|0] "" Vector__XXX
 SG_ CMP_infoUsageId m11 : 32|16@1+ (1,0) [0|0] "" Vector__XXX
 SG_ CMP_infoSubUsageId m11 : 48|16@1+ (1,0) [0|0] "" Vector__XXX
 SG_ CMP_infoBootUdsProtoVersion m20 : 8|8@1+ (1,0) [0|0] "" Vector__XXX
 SG_ CMP_infoBootCrc m20 : 32|32@1+ (1,0) [0|0] "" Vector__XXX
 SG_ CMP_infoPlatformType m13 : 8|8@1+ (1,0) [0|0] "" Vector__XXX
 SG_ CMP_infoAppCrc m13 : 32|32@1+ (1,0) [0|0] "" Vector__XXX

BO_ 869 SCS_alertMatrix1: 8 VEH
 SG_ SCS_a001_hwDSPfault : 0|1@1+ (1,0) [0|0] "" Vector__XXX
 SG_ SCS_a002_hwIbatOC : 1|1@1+ (1,0) [0|0] "" Vector__XXX
 SG_ SCS_a003_hwCordOT : 2|1@1+ (1,0) [0|0] "" Vector__XXX
 SG_ SCS_a004_hwVbusOV : 3|1@1+ (1,0) [0|0] "" Vector__XXX
 SG_ SCS_a005_hwHVIL : 4|1@1+ (1,0) [0|0] "" Vector__XXX
 SG_ SCS_a006_hwWeld_V1 : 5|1@1+ (1,0) [0|0] "" Vector__XXX
 SG_ SCS_a007_hwWeld_V2 : 6|1@1+ (1,0) [0|0] "" Vector__XXX
 SG_ SCS_a008_hwOpen_V1 : 7|1@1+ (1,0) [0|0] "" Vector__XXX
 SG_ SCS_a009_hwOpen_V2 : 8|1@1+ (1,0) [0|0] "" Vector__XXX
 SG_ SCS_a010_hwIllegalCntrCmdV1 : 9|1@1+ (1,0) [0|0] "" Vector__XXX
 SG_ SCS_a011_hwIllegalCntrCmdInt : 10|1@1+ (1,0) [0|0] "" Vector__XXX
 SG_ SCS_a012_hwIllegalCntrCmdV2 : 11|1@1+ (1,0) [0|0] "" Vector__XXX
 SG_ SCS_a013_cordTempHiFoldBk : 12|1@1+ (1,0) [0|0] "" Vector__XXX
 SG_ SCS_a014_coolantTempHiFoldBk : 13|1@1+ (1,0) [0|0] "" Vector__XXX
 SG_ SCS_a015_unusedHW15 : 14|1@1+ (1,0) [0|0] "" Vector__XXX
 SG_ SCS_a016_unusedHW16 : 15|1@1+ (1,0) [0|0] "" Vector__XXX
 SG_ SCS_a017_unusedHW17 : 16|1@1+ (1,0) [0|0] "" Vector__XXX
 SG_ SCS_a018_unusedHW18 : 17|1@1+ (1,0) [0|0] "" Vector__XXX
 SG_ SCS_a019_unusedHW19 : 18|1@1+ (1,0) [0|0] "" Vector__XXX
 SG_ SCS_a020_unusedHW20 : 19|1@1+ (1,0) [0|0] "" Vector__XXX
 SG_ SCS_a021_unusedHW21 : 20|1@1+ (1,0) [0|0] "" Vector__XXX
 SG_ SCS_a022_fastChargeLimitActiveV1 : 21|1@1+ (1,0) [0|0] "" Vector__XXX
 SG_ SCS_a023_fastChargeLimitActiveV2 : 22|1@1+ (1,0) [0|0] "" Vector__XXX
 SG_ SCS_a024_emergencyShutdown : 23|1@1+ (1,0) [0|0] "" Vector__XXX
 SG_ SCS_a025_internalIsolationFault : 24|1@1+ (1,0) [0|0] "" Vector__XXX
 SG_ SCS_a026_internalIsolationLow : 25|1@1+ (1,0) [0|0] "" Vector__XXX
 SG_ SCS_a027_externalIsolationLow : 26|1@1+ (1,0) [0|0] "" Vector__XXX
 SG_ SCS_a028_isolationRationality : 27|1@1+ (1,0) [0|0] "" Vector__XXX
 SG_ SCS_a029_VbatOV : 28|1@1+ (1,0) [0|0] "" Vector__XXX
 SG_ SCS_a030_VbusOV : 29|1@1+ (1,0) [0|0] "" Vector__XXX
 SG_ SCS_a031_IbatOC : 30|1@1+ (1,0) [0|0] "" Vector__XXX
 SG_ SCS_a032_VBatRationality : 31|1@1+ (1,0) [0|0] "" Vector__XXX
 SG_ SCS_a033_VBusRationality : 32|1@1+ (1,0) [0|0] "" Vector__XXX
 SG_ SCS_a034_IBatRationality : 33|1@1+ (1,0) [0|0] "" Vector__XXX
 SG_ SCS_a035_unexpectedVbusBehavior : 34|1@1+ (1,0) [0|0] "" Vector__XXX
 SG_ SCS_a036_internalContactorWelded : 35|1@1+ (1,0) [0|0] "" Vector__XXX
 SG_ SCS_a037_outputContactorWelded : 36|1@1+ (1,0) [0|0] "" Vector__XXX
 SG_ SCS_a038_contactorFailedOpen : 37|1@1+ (1,0) [0|0] "" Vector__XXX
 SG_ SCS_a039_ibatRegulation : 38|1@1+ (1,0) [0|0] "" Vector__XXX
 SG_ SCS_a040_plus12VOutOfRange : 39|1@1+ (1,0) [0|0] "" Vector__XXX
 SG_ SCS_a041_minus12VOutOfRange : 40|1@1+ (1,0) [0|0] "" Vector__XXX
 SG_ SCS_a042_pilotOutOfRange : 41|1@1+ (1,0) [0|0] "" Vector__XXX
 SG_ SCS_a043_pilotRationality : 42|1@1+ (1,0) [0|0] "" Vector__XXX
 SG_ SCS_a044_proximityRationality : 43|1@1+ (1,0) [0|0] "" Vector__XXX
 SG_ SCS_a045_pcbaOT : 44|1@1+ (1,0) [0|0] "" Vector__XXX
 SG_ SCS_a046_coolantOT : 45|1@1+ (1,0) [0|0] "" Vector__XXX
 SG_ SCS_a047_cordOT : 46|1@1+ (1,0) [0|0] "" Vector__XXX
 SG_ SCS_a048_ambientOT : 47|1@1+ (1,0) [0|0] "" Vector__XXX
 SG_ SCS_a049_pcbaTempRationality : 48|1@1+ (1,0) [0|0] "" Vector__XXX
 SG_ SCS_a050_coolantTempRationality : 49|1@1+ (1,0) [0|0] "" Vector__XXX
 SG_ SCS_a051_cordTempRationality : 50|1@1+ (1,0) [0|0] "" Vector__XXX
 SG_ SCS_a052_ambientTempRationality : 51|1@1+ (1,0) [0|0] "" Vector__XXX
 SG_ SCS_a053_unexpectedThermalBehavi : 52|1@1+ (1,0) [0|0] "" Vector__XXX
 SG_ SCS_a054_pumpRegulation : 53|1@1+ (1,0) [0|0] "" Vector__XXX
 SG_ SCS_a055_coolantLevelLow : 54|1@1+ (1,0) [0|0] "" Vector__XXX
 SG_ SCS_a056_stateTransitionDenied : 55|1@1+ (1,0) [0|0] "" Vector__XXX
 SG_ SCS_a057_watchdogReset : 56|1@1+ (1,0) [0|0] "" Vector__XXX
 SG_ SCS_a058_adcRef : 57|1@1+ (1,0) [0|0] "" Vector__XXX
 SG_ SCS_a059_memoryError : 58|1@1+ (1,0) [0|0] "" Vector__XXX
 SG_ SCS_a060_swHVIL : 59|1@1+ (1,0) [0|0] "" Vector__XXX
 SG_ SCS_a061_postOutOfService : 60|1@1+ (1,0) [0|0] "" Vector__XXX
 SG_ SCS_a062_unused : 61|1@1+ (1,0) [0|0] "" Vector__XXX
 SG_ SCS_a063_canRationality : 62|1@1+ (1,0) [0|0] "" Vector__XXX
 SG_ SCS_a064_vehicleCommandTimeout : 63|1@1+ (1,0) [0|0] "" Vector__XXX

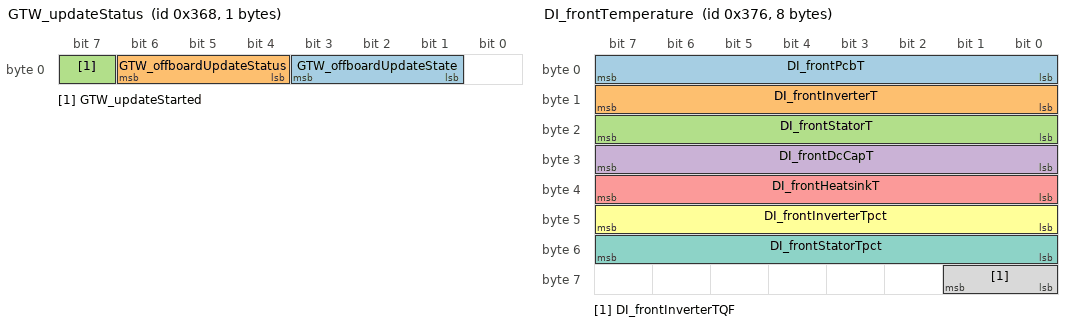
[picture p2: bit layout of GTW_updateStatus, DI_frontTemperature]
BO_ 872 GTW_updateStatus: 1 VEH
 SG_ GTW_offboardUpdateState : 1|3@1+ (1,0) [0|0] "" Vector__XXX
 SG_ GTW_offboardUpdateStatus : 4|3@1+ (1,0) [0|0] "" Vector__XXX
 SG_ GTW_updateStarted : 7|1@1+ (1,0) [0|0] "" Vector__XXX

BO_ 873 APP_warningMatrix1: 8 CH
 SG_ APP_w065_deserializerOvercurrent : 0|1@1+ (1,0) [0|0] "" Vector__XXX
 SG_ APP_w066_deserializerLockLost : 1|1@1+ (1,0) [0|0] "" Vector__XXX
 SG_ APP_w067_steeringAlignment : 2|1@1+ (1,0) [0|0] "" Vector__XXX
 SG_ APP_w068_vlInconsistency : 3|1@1+ (1,0) [0|0] "" Vector__XXX
 SG_ APP_w069_apcSpaceMasked : 4|1@1+ (1,0) [0|0] "" Vector__XXX
 SG_ APP_w070_apcIncompleteCal : 5|1@1+ (1,0) [0|0] "" Vector__XXX
 SG_ APP_w071_selfparkStarted : 6|1@1+ (1,0) [0|0] "" Vector__XXX
 SG_ APP_w072_selfparkComplete : 7|1@1+ (1,0) [0|0] "" Vector__XXX
 SG_ APP_w073_issueEscalatedLDW : 8|1@1+ (1,0) [0|0] "" Vector__XXX
 SG_ APP_w074_inPathStationaryObst : 9|1@1+ (1,0) [0|0] "" Vector__XXX
 SG_ APP_w075_scMia : 10|1@1+ (1,0) [0|0] "" Vector__XXX
 SG_ APP_w076_mobilEyeSetC : 11|1@1+ (1,0) [0|0] "" Vector__XXX
 SG_ APP_w077_pmmActive : 12|1@1+ (1,0) [0|0] "" Vector__XXX
 SG_ APP_w078_pmmActive2 : 13|1@1+ (1,0) [0|0] "" Vector__XXX
 SG_ APP_w079_edrAvailable : 14|1@1+ (1,0) [0|0] "" Vector__XXX
 SG_ APP_w080_accFailedActivation : 15|1@1+ (1,0) [0|0] "" Vector__XXX
 SG_ APP_w081_pmmActiveBraking : 16|1@1+ (1,0) [0|0] "" Vector__XXX
 SG_ APP_w082_inPathFSviolation : 17|1@1+ (1,0) [0|0] "" Vector__XXX
 SG_ APP_w083_inPathRADObject : 18|1@1+ (1,0) [0|0] "" Vector__XXX
 SG_ APP_w084_pmmIPSO : 19|1@1+ (1,0) [0|0] "" Vector__XXX
 SG_ APP_w085_pmmSteering : 20|1@1+ (1,0) [0|0] "" Vector__XXX
 SG_ APP_w086_robCollision : 21|1@1+ (1,0) [0|0] "" Vector__XXX
 SG_ APP_w087_DEPRECATED : 22|1@1+ (1,0) [0|0] "" Vector__XXX
 SG_ APP_w088_DEPRECATED : 23|1@1+ (1,0) [0|0] "" Vector__XXX
 SG_ APP_w089_DEPRECATED : 24|1@1+ (1,0) [0|0] "" Vector__XXX
 SG_ APP_w090_DEPRECATED : 25|1@1+ (1,0) [0|0] "" Vector__XXX
 SG_ APP_w091_DEPRECATED : 26|1@1+ (1,0) [0|0] "" Vector__XXX
 SG_ APP_w092_DEPRECATED : 27|1@1+ (1,0) [0|0] "" Vector__XXX
 SG_ APP_w093_DEPRECATED : 28|1@1+ (1,0) [0|0] "" Vector__XXX
 SG_ APP_w094_DEPRECATED : 29|1@1+ (1,0) [0|0] "" Vector__XXX
 SG_ APP_w095_DEPRECATED : 30|1@1+ (1,0) [0|0] "" Vector__XXX
 SG_ APP_w096_DEPRECATED : 31|1@1+ (1,0) [0|0] "" Vector__XXX
 SG_ APP_w097_DEPRECATED : 32|1@1+ (1,0) [0|0] "" Vector__XXX
 SG_ APP_w098_DEPRECATED : 33|1@1+ (1,0) [0|0] "" Vector__XXX
 SG_ APP_w099_DEPRECATED : 34|1@1+ (1,0) [0|0] "" Vector__XXX
 SG_ APP_w100_DEPRECATED : 35|1@1+ (1,0) [0|0] "" Vector__XXX
 SG_ APP_w101_DEPRECATED : 36|1@1+ (1,0) [0|0] "" Vector__XXX
 SG_ APP_w102_DEPRECATED : 37|1@1+ (1,0) [0|0] "" Vector__XXX
 SG_ APP_w103_robExperimentalAEB : 38|1@1+ (1,0) [0|0] "" Vector__XXX
 SG_ APP_w104_DEPRECATED : 39|1@1+ (1,0) [0|0] "" Vector__XXX
 SG_ APP_w105_DEPRECATED : 40|1@1+ (1,0) [0|0] "" Vector__XXX
 SG_ APP_w106_torsionBarOffset : 41|1@1+ (1,0) [0|0] "" Vector__XXX

BO_ 874 DAS_warningMatrix1: 8 VEH
 SG_ DAS_w065_deserializerOvercurrent : 0|1@1+ (1,0) [0|0] "" Vector__XXX
 SG_ DAS_w066_deserializerLockLost : 1|1@1+ (1,0) [0|0] "" Vector__XXX
 SG_ DAS_w067_steeringAlignment : 2|1@1+ (1,0) [0|0] "" Vector__XXX
 SG_ DAS_w068_vlInconsistency : 3|1@1+ (1,0) [0|0] "" Vector__XXX
 SG_ DAS_w069_apcSpaceMasked : 4|1@1+ (1,0) [0|0] "" Vector__XXX
 SG_ DAS_w070_apcIncompleteCal : 5|1@1+ (1,0) [0|0] "" Vector__XXX
 SG_ DAS_w071_selfparkStarted : 6|1@1+ (1,0) [0|0] "" Vector__XXX
 SG_ DAS_w072_selfparkComplete : 7|1@1+ (1,0) [0|0] "" Vector__XXX
 SG_ DAS_w073_issueEscalatedLDW : 8|1@1+ (1,0) [0|0] "" Vector__XXX
 SG_ DAS_w074_inPathStationaryObst : 9|1@1+ (1,0) [0|0] "" Vector__XXX
 SG_ DAS_w075_scMia : 10|1@1+ (1,0) [0|0] "" Vector__XXX
 SG_ DAS_w076_mobilEyeSetC : 11|1@1+ (1,0) [0|0] "" Vector__XXX
 SG_ DAS_w077_pmmActive : 12|1@1+ (1,0) [0|0] "" Vector__XXX
 SG_ DAS_w078_pmmActive2 : 13|1@1+ (1,0) [0|0] "" Vector__XXX
 SG_ DAS_w079_edrAvailable : 14|1@1+ (1,0) [0|0] "" Vector__XXX
 SG_ DAS_w080_accFailedActivation : 15|1@1+ (1,0) [0|0] "" Vector__XXX
 SG_ DAS_w081_pmmActiveBraking : 16|1@1+ (1,0) [0|0] "" Vector__XXX
 SG_ DAS_w082_inPathFSviolation : 17|1@1+ (1,0) [0|0] "" Vector__XXX
 SG_ DAS_w083_inPathRADObject : 18|1@1+ (1,0) [0|0] "" Vector__XXX
 SG_ DAS_w084_pmmIPSO : 19|1@1+ (1,0) [0|0] "" Vector__XXX
 SG_ DAS_w085_pmmSteering : 20|1@1+ (1,0) [0|0] "" Vector__XXX
 SG_ DAS_w086_robCollision : 21|1@1+ (1,0) [0|0] "" Vector__XXX
 SG_ DAS_w087_DEPRECATED : 22|1@1+ (1,0) [0|0] "" Vector__XXX
 SG_ DAS_w088_DEPRECATED : 23|1@1+ (1,0) [0|0] "" Vector__XXX
 SG_ DAS_w089_DEPRECATED : 24|1@1+ (1,0) [0|0] "" Vector__XXX
 SG_ DAS_w090_DEPRECATED : 25|1@1+ (1,0) [0|0] "" Vector__XXX
 SG_ DAS_w091_DEPRECATED : 26|1@1+ (1,0) [0|0] "" Vector__XXX
 SG_ DAS_w092_DEPRECATED : 27|1@1+ (1,0) [0|0] "" Vector__XXX
 SG_ DAS_w093_DEPRECATED : 28|1@1+ (1,0) [0|0] "" Vector__XXX
 SG_ DAS_w094_DEPRECATED : 29|1@1+ (1,0) [0|0] "" Vector__XXX
 SG_ DAS_w095_DEPRECATED : 30|1@1+ (1,0) [0|0] "" Vector__XXX
 SG_ DAS_w096_DEPRECATED : 31|1@1+ (1,0) [0|0] "" Vector__XXX
 SG_ DAS_w097_DEPRECATED : 32|1@1+ (1,0) [0|0] "" Vector__XXX
 SG_ DAS_w098_DEPRECATED : 33|1@1+ (1,0) [0|0] "" Vector__XXX
 SG_ DAS_w099_DEPRECATED : 34|1@1+ (1,0) [0|0] "" Vector__XXX
 SG_ DAS_w100_DEPRECATED : 35|1@1+ (1,0) [0|0] "" Vector__XXX
 SG_ DAS_w101_DEPRECATED : 36|1@1+ (1,0) [0|0] "" Vector__XXX
 SG_ DAS_w102_DEPRECATED : 37|1@1+ (1,0) [0|0] "" Vector__XXX
 SG_ DAS_w103_robExperimentalAEB : 38|1@1+ (1,0) [0|0] "" Vector__XXX
 SG_ DAS_w104_DEPRECATED : 39|1@1+ (1,0) [0|0] "" Vector__XXX
 SG_ DAS_w105_DEPRECATED : 40|1@1+ (1,0) [0|0] "" Vector__XXX
 SG_ DAS_w106_torsionBarCalibrated : 41|1@1+ (1,0) [0|0] "" Vector__XXX

BO_ 876 APS_warningMatrix1: 8 CH
 SG_ APS_w065_deserializerOvercurrent : 0|1@1+ (1,0) [0|0] "" Vector__XXX
 SG_ APS_w066_deserializerLockLost : 1|1@1+ (1,0) [0|0] "" Vector__XXX
 SG_ APS_w067_steeringAlignment : 2|1@1+ (1,0) [0|0] "" Vector__XXX
 SG_ APS_w068_vlInconsistency : 3|1@1+ (1,0) [0|0] "" Vector__XXX
 SG_ APS_w069_apcSpaceMasked : 4|1@1+ (1,0) [0|0] "" Vector__XXX
 SG_ APS_w070_apcIncompleteCal : 5|1@1+ (1,0) [0|0] "" Vector__XXX
 SG_ APS_w071_selfparkStarted : 6|1@1+ (1,0) [0|0] "" Vector__XXX
 SG_ APS_w072_selfparkComplete : 7|1@1+ (1,0) [0|0] "" Vector__XXX
 SG_ APS_w073_issueEscalatedLDW : 8|1@1+ (1,0) [0|0] "" Vector__XXX
 SG_ APS_w074_inPathStationaryObst : 9|1@1+ (1,0) [0|0] "" Vector__XXX
 SG_ APS_w075_scMia : 10|1@1+ (1,0) [0|0] "" Vector__XXX
 SG_ APS_w076_mobilEyeSetC : 11|1@1+ (1,0) [0|0] "" Vector__XXX
 SG_ APS_w077_pmmActive : 12|1@1+ (1,0) [0|0] "" Vector__XXX
 SG_ APS_w078_pmmActive2 : 13|1@1+ (1,0) [0|0] "" Vector__XXX
 SG_ APS_w079_edrAvailable : 14|1@1+ (1,0) [0|0] "" Vector__XXX
 SG_ APS_w080_accFailedActivation : 15|1@1+ (1,0) [0|0] "" Vector__XXX
 SG_ APS_w081_pmmActiveBraking : 16|1@1+ (1,0) [0|0] "" Vector__XXX
 SG_ APS_w082_inPathFSviolation : 17|1@1+ (1,0) [0|0] "" Vector__XXX
 SG_ APS_w083_inPathRADObject : 18|1@1+ (1,0) [0|0] "" Vector__XXX
 SG_ APS_w084_pmmIPSO : 19|1@1+ (1,0) [0|0] "" Vector__XXX
 SG_ APS_w085_pmmSteering : 20|1@1+ (1,0) [0|0] "" Vector__XXX
 SG_ APS_w086_robCollision : 21|1@1+ (1,0) [0|0] "" Vector__XXX
 SG_ APS_w087_DEPRECATED : 22|1@1+ (1,0) [0|0] "" Vector__XXX
 SG_ APS_w088_DEPRECATED : 23|1@1+ (1,0) [0|0] "" Vector__XXX
 SG_ APS_w089_DEPRECATED : 24|1@1+ (1,0) [0|0] "" Vector__XXX
 SG_ APS_w090_DEPRECATED : 25|1@1+ (1,0) [0|0] "" Vector__XXX
 SG_ APS_w091_DEPRECATED : 26|1@1+ (1,0) [0|0] "" Vector__XXX
 SG_ APS_w092_DEPRECATED : 27|1@1+ (1,0) [0|0] "" Vector__XXX
 SG_ APS_w093_DEPRECATED : 28|1@1+ (1,0) [0|0] "" Vector__XXX
 SG_ APS_w094_DEPRECATED : 29|1@1+ (1,0) [0|0] "" Vector__XXX
 SG_ APS_w095_DEPRECATED : 30|1@1+ (1,0) [0|0] "" Vector__XXX
 SG_ APS_w096_DEPRECATED : 31|1@1+ (1,0) [0|0] "" Vector__XXX
 SG_ APS_w097_DEPRECATED : 32|1@1+ (1,0) [0|0] "" Vector__XXX
 SG_ APS_w098_DEPRECATED : 33|1@1+ (1,0) [0|0] "" Vector__XXX
 SG_ APS_w099_DEPRECATED : 34|1@1+ (1,0) [0|0] "" Vector__XXX
 SG_ APS_w100_DEPRECATED : 35|1@1+ (1,0) [0|0] "" Vector__XXX
 SG_ APS_w101_DEPRECATED : 36|1@1+ (1,0) [0|0] "" Vector__XXX
 SG_ APS_w102_DEPRECATED : 37|1@1+ (1,0) [0|0] "" Vector__XXX
 SG_ APS_w103_robExperimentalAEB : 38|1@1+ (1,0) [0|0] "" Vector__XXX
 SG_ APS_w104_DEPRECATED : 39|1@1+ (1,0) [0|0] "" Vector__XXX
 SG_ APS_w105_DEPRECATED : 40|1@1+ (1,0) [0|0] "" Vector__XXX
 SG_ APS_w106_torsionBarOffset : 41|1@1+ (1,0) [0|0] "" Vector__XXX

BO_ 877 TAS_warningMatrix2: 8 VEH
 SG_ TAS_w070_lowVoltage12V : 5|1@1+ (1,0) [0|0] "" Vector__XXX
 SG_ TAS_w071_highVoltage12V : 6|1@1+ (1,0) [0|0] "" Vector__XXX
 SG_ TAS_w072_shortCircuit5VS0 : 7|1@1+ (1,0) [0|0] "" Vector__XXX
 SG_ TAS_w073_lowVoltage5VS0 : 8|1@1+ (1,0) [0|0] "" Vector__XXX
 SG_ TAS_w074_shortCircuit5VS1 : 9|1@1+ (1,0) [0|0] "" Vector__XXX
 SG_ TAS_w075_lowVoltage5VS1 : 10|1@1+ (1,0) [0|0] "" Vector__XXX
 SG_ TAS_w076_highVoltage5VS1 : 11|1@1+ (1,0) [0|0] "" Vector__XXX
 SG_ TAS_w077_pressureSigVTooLow : 12|1@1+ (1,0) [0|0] "" Vector__XXX
 SG_ TAS_w078_pressureSigVTooHigh : 13|1@1+ (1,0) [0|0] "" Vector__XXX
 SG_ TAS_w079_DvrSideCfgMismatch : 14|1@1+ (1,0) [0|0] "" Vector__XXX
 SG_ TAS_w080_pressureRefVTooLow : 15|1@1+ (1,0) [0|0] "" Vector__XXX
 SG_ TAS_w093_OTPError : 28|1@1+ (1,0) [0|0] "" Vector__XXX
 SG_ TAS_w098_VCFRONT_MIA : 33|1@1+ (1,0) [0|0] "" Vector__XXX
 SG_ TAS_w099_UI_MIA : 34|1@1+ (1,0) [0|0] "" Vector__XXX
 SG_ TAS_w100_RCM_MIA : 35|1@1+ (1,0) [0|0] "" Vector__XXX
 SG_ TAS_w101_ESP_MIA : 36|1@1+ (1,0) [0|0] "" Vector__XXX
 SG_ TAS_w102_DI_MIA : 37|1@1+ (1,0) [0|0] "" Vector__XXX
 SG_ TAS_w103_GTW_MIA : 38|1@1+ (1,0) [0|0] "" Vector__XXX
 SG_ TAS_w105_ECUDebugMode : 40|1@1+ (1,0) [0|0] "" Vector__XXX
 SG_ TAS_w106_HighCPULoad : 41|1@1+ (1,0) [0|0] "" Vector__XXX
 SG_ TAS_w107_HighStackUsage : 42|1@1+ (1,0) [0|0] "" Vector__XXX
 SG_ TAS_w121_maxDutyFL : 56|1@1+ (1,0) [0|0] "" Vector__XXX
 SG_ TAS_w122_maxDutyFR : 57|1@1+ (1,0) [0|0] "" Vector__XXX
 SG_ TAS_w123_maxDutyRL : 58|1@1+ (1,0) [0|0] "" Vector__XXX
 SG_ TAS_w124_maxDutyRR : 59|1@1+ (1,0) [0|0] "" Vector__XXX
 SG_ TAS_w125_maxDutyReservoir : 60|1@1+ (1,0) [0|0] "" Vector__XXX
 SG_ TAS_w126_maxDutyExhaust : 61|1@1+ (1,0) [0|0] "" Vector__XXX
 SG_ TAS_w127_maxDutyBoost : 62|1@1+ (1,0) [0|0] "" Vector__XXX
 SG_ TAS_w128_maxDutyCompressor : 63|1@1+ (1,0) [0|0] "" Vector__XXX

BO_ 879 TPMS_StatusC: 8 CH
 SG_ TPMS_WA_version : 3|1@1+ (1,0) [0|0] "" Vector__XXX
 SG_ TPMS_c_globalHardWarning : 0|1@1+ (1,0) [0|0] "" Vector__XXX
 SG_ TPMS_c_globalSoftWarning : 1|1@1+ (1,0) [0|0] "" Vector__XXX
 SG_ TPMS_deltaPressWarningFL : 20|1@1+ (1,0) [0|0] "" Vector__XXX
 SG_ TPMS_deltaPressWarningFR : 21|1@1+ (1,0) [0|0] "" Vector__XXX
 SG_ TPMS_deltaPressWarningRL : 22|1@1+ (1,0) [0|0] "" Vector__XXX
 SG_ TPMS_deltaPressWarningRR : 23|1@1+ (1,0) [0|0] "" Vector__XXX
 SG_ TPMS_ecuOverVoltage : 41|1@1+ (1,0) [0|0] "" Vector__XXX
 SG_ TPMS_ecuRamRomNvMFail : 42|1@1+ (1,0) [0|0] "" Vector__XXX
 SG_ TPMS_ecuUnderVoltage : 40|1@1+ (1,0) [0|0] "" Vector__XXX
 SG_ TPMS_eolNotCompleted : 47|1@1+ (1,0) [0|0] "" Vector__XXX
 SG_ TPMS_externalTemperatureFail : 46|1@1+ (1,0) [0|0] "" Vector__XXX
 SG_ TPMS_globalDeltaPressure : 4|1@1+ (1,0) [0|0] "" Vector__XXX
 SG_ TPMS_hardWarningFL : 15|1@1+ (1,0) [0|0] "" Vector__XXX
 SG_ TPMS_hardWarningFR : 13|1@1+ (1,0) [0|0] "" Vector__XXX
 SG_ TPMS_hardWarningRL : 11|1@1+ (1,0) [0|0] "" Vector__XXX
 SG_ TPMS_hardWarningRR : 9|1@1+ (1,0) [0|0] "" Vector__XXX
 SG_ TPMS_learningStatus : 16|2@1+ (1,0) [0|0] "" Vector__XXX
 SG_ TPMS_localisationStatus : 18|2@1+ (1,0) [0|0] "" Vector__XXX
 SG_ TPMS_newSensorLearnt : 5|3@1+ (1,0) [0|0] "" Vector__XXX
 SG_ TPMS_rcpFront : 48|8@1+ (0.025,0) [0|0] "bar" Vector__XXX
 SG_ TPMS_rcpRear : 56|8@1+ (0.025,0) [0|0] "bar" Vector__XXX
 SG_ TPMS_rfReceiverFail : 43|1@1+ (1,0) [0|0] "" Vector__XXX
 SG_ TPMS_sensorBatteryLowFL : 32|1@1+ (1,0) [0|0] "" Vector__XXX
 SG_ TPMS_sensorBatteryLowFR : 33|1@1+ (1,0) [0|0] "" Vector__XXX
 SG_ TPMS_sensorBatteryLowRL : 34|1@1+ (1,0) [0|0] "" Vector__XXX
 SG_ TPMS_sensorBatteryLowRR : 35|1@1+ (1,0) [0|0] "" Vector__XXX
 SG_ TPMS_sensorDefectiveFL : 36|1@1+ (1,0) [0|0] "" Vector__XXX
 SG_ TPMS_sensorDefectiveFR : 37|1@1+ (1,0) [0|0] "" Vector__XXX
 SG_ TPMS_sensorDefectiveRL : 38|1@1+ (1,0) [0|0] "" Vector__XXX
 SG_ TPMS_sensorDefectiveRR : 39|1@1+ (1,0) [0|0] "" Vector__XXX
 SG_ TPMS_sensorNoResponseFL : 24|1@1+ (1,0) [0|0] "" Vector__XXX
 SG_ TPMS_sensorNoResponseFR : 25|1@1+ (1,0) [0|0] "" Vector__XXX
 SG_ TPMS_sensorNoResponseRL : 26|1@1+ (1,0) [0|0] "" Vector__XXX
 SG_ TPMS_sensorNoResponseRR : 27|1@1+ (1,0) [0|0] "" Vector__XXX
 SG_ TPMS_sensorThermShutdownFL : 28|1@1+ (1,0) [0|0] "" Vector__XXX
 SG_ TPMS_sensorThermShutdownFR : 29|1@1+ (1,0) [0|0] "" Vector__XXX
 SG_ TPMS_sensorThermShutdownRL : 30|1@1+ (1,0) [0|0] "" Vector__XXX
 SG_ TPMS_sensorThermShutdownRR : 31|1@1+ (1,0) [0|0] "" Vector__XXX
 SG_ TPMS_softWarningFL : 14|1@1+ (1,0) [0|0] "" Vector__XXX
 SG_ TPMS_softWarningFR : 12|1@1+ (1,0) [0|0] "" Vector__XXX
 SG_ TPMS_softWarningRL : 10|1@1+ (1,0) [0|0] "" Vector__XXX
 SG_ TPMS_softWarningRR : 8|1@1+ (1,0) [0|0] "" Vector__XXX
 SG_ TPMS_systemMalfunction : 2|1@1+ (1,0) [0|0] "" Vector__XXX
 SG_ TPMS_vehicleSpeedFail : 45|1@1+ (1,0) [0|0] "" Vector__XXX
 SG_ TPMS_wheelPulseMissing : 44|1@1+ (1,0) [0|0] "" Vector__XXX

BO_ 880 SCS_alertMatrix2: 8 CH
 SG_ SCS_a065_vBatRationalityStage1 : 0|1@1+ (1,0) [0|0] "" Vector__XXX
 SG_ SCS_a066_vBatRationalityStage2 : 1|1@1+ (1,0) [0|0] "" Vector__XXX
 SG_ SCS_a067_vBatRationalityStage3 : 2|1@1+ (1,0) [0|0] "" Vector__XXX
 SG_ SCS_a068_vBatRationalityStage4 : 3|1@1+ (1,0) [0|0] "" Vector__XXX
 SG_ SCS_a069_vStageRationalityV1 : 4|1@1+ (1,0) [0|0] "" Vector__XXX
 SG_ SCS_a070_vStageRationalityV2 : 5|1@1+ (1,0) [0|0] "" Vector__XXX
 SG_ SCS_a071_chargerMIA : 6|1@1+ (1,0) [0|0] "" Vector__XXX
 SG_ SCS_a072_gtwMIA : 7|1@1+ (1,0) [0|0] "" Vector__XXX
 SG_ SCS_a073_lccMIA : 8|1@1+ (1,0) [0|0] "" Vector__XXX
 SG_ SCS_a074_isoVDiffHi : 9|1@1+ (1,0) [0|0] "" Vector__XXX
 SG_ SCS_a075_leakageTestAbsDecayLow : 10|1@1+ (1,0) [0|0] "" Vector__XXX
 SG_ SCS_a076_bmsMIA : 11|1@1+ (1,0) [0|0] "" Vector__XXX
 SG_ SCS_a077_unexpectedVbatBehavior : 12|1@1+ (1,0) [0|0] "" Vector__XXX
 SG_ SCS_a078_voltageMatchTimeout : 13|1@1+ (1,0) [0|0] "" Vector__XXX
 SG_ SCS_a079_unexpectedVbat : 14|1@1+ (1,0) [0|0] "" Vector__XXX
 SG_ SCS_a080_lccFaulted : 15|1@1+ (1,0) [0|0] "" Vector__XXX
 SG_ SCS_a081_rmsInputVoltageHigh : 16|1@1+ (1,0) [0|0] "" Vector__XXX
 SG_ SCS_a082_VbatUV : 17|1@1+ (1,0) [0|0] "" Vector__XXX
 SG_ SCS_a083_chargeCurrentLimited : 18|1@1+ (1,0) [0|0] "" Vector__XXX
 SG_ SCS_a084_unused84 : 19|1@1+ (1,0) [0|0] "" Vector__XXX
 SG_ SCS_a085_unused85 : 20|1@1+ (1,0) [0|0] "" Vector__XXX
 SG_ SCS_a086_lccResetDetected : 21|1@1+ (1,0) [0|0] "" Vector__XXX
 SG_ SCS_a087_posCordTempRationality : 22|1@1+ (1,0) [0|0] "" Vector__XXX
 SG_ SCS_a088_negCordTempRationality : 23|1@1+ (1,0) [0|0] "" Vector__XXX
 SG_ SCS_a089_posCordOT : 24|1@1+ (1,0) [0|0] "" Vector__XXX
 SG_ SCS_a090_negCordOT : 25|1@1+ (1,0) [0|0] "" Vector__XXX
 SG_ SCS_a091_voltageRiseDetection : 26|1@1+ (1,0) [0|0] "" Vector__XXX
 SG_ SCS_a092_cabEnableDeasserted : 27|1@1+ (1,0) [0|0] "" Vector__XXX
 SG_ SCS_a093_unused93 : 28|1@1+ (1,0) [0|0] "" Vector__XXX
 SG_ SCS_a094_unused94 : 29|1@1+ (1,0) [0|0] "" Vector__XXX
 SG_ SCS_a095_unused95 : 30|1@1+ (1,0) [0|0] "" Vector__XXX
 SG_ SCS_a096_unused96 : 31|1@1+ (1,0) [0|0] "" Vector__XXX
 SG_ SCS_a097_unused97 : 32|1@1+ (1,0) [0|0] "" Vector__XXX
 SG_ SCS_a098_unused98 : 33|1@1+ (1,0) [0|0] "" Vector__XXX
 SG_ SCS_a099_unused99 : 34|1@1+ (1,0) [0|0] "" Vector__XXX
 SG_ SCS_a100_unused100 : 35|1@1+ (1,0) [0|0] "" Vector__XXX
 SG_ SCS_a101_unused101 : 36|1@1+ (1,0) [0|0] "" Vector__XXX
 SG_ SCS_a102_unused102 : 37|1@1+ (1,0) [0|0] "" Vector__XXX
 SG_ SCS_a103_unused103 : 38|1@1+ (1,0) [0|0] "" Vector__XXX
 SG_ SCS_a104_unused104 : 39|1@1+ (1,0) [0|0] "" Vector__XXX
 SG_ SCS_a105_unused105 : 40|1@1+ (1,0) [0|0] "" Vector__XXX
 SG_ SCS_a106_unused106 : 41|1@1+ (1,0) [0|0] "" Vector__XXX
 SG_ SCS_a107_unused107 : 42|1@1+ (1,0) [0|0] "" Vector__XXX
 SG_ SCS_a108_unused108 : 43|1@1+ (1,0) [0|0] "" Vector__XXX
 SG_ SCS_a109_unused109 : 44|1@1+ (1,0) [0|0] "" Vector__XXX
 SG_ SCS_a110_unused110 : 45|1@1+ (1,0) [0|0] "" Vector__XXX
 SG_ SCS_a111_unused111 : 46|1@1+ (1,0) [0|0] "" Vector__XXX
 SG_ SCS_a112_unused112 : 47|1@1+ (1,0) [0|0] "" Vector__XXX
 SG_ SCS_a113_unused113 : 48|1@1+ (1,0) [0|0] "" Vector__XXX
 SG_ SCS_a114_unused114 : 49|1@1+ (1,0) [0|0] "" Vector__XXX
 SG_ SCS_a115_unused115 : 50|1@1+ (1,0) [0|0] "" Vector__XXX
 SG_ SCS_a116_unused116 : 51|1@1+ (1,0) [0|0] "" Vector__XXX
 SG_ SCS_a117_unused117 : 52|1@1+ (1,0) [0|0] "" Vector__XXX
 SG_ SCS_a118_unused118 : 53|1@1+ (1,0) [0|0] "" Vector__XXX
 SG_ SCS_a119_unused119 : 54|1@1+ (1,0) [0|0] "" Vector__XXX
 SG_ SCS_a120_unused120 : 55|1@1+ (1,0) [0|0] "" Vector__XXX
 SG_ SCS_a121_unused121 : 56|1@1+ (1,0) [0|0] "" Vector__XXX
 SG_ SCS_a122_unused122 : 57|1@1+ (1,0) [0|0] "" Vector__XXX
 SG_ SCS_a123_unused123 : 58|1@1+ (1,0) [0|0] "" Vector__XXX
 SG_ SCS_a124_unused124 : 59|1@1+ (1,0) [0|0] "" Vector__XXX
 SG_ SCS_a125_unused125 : 60|1@1+ (1,0) [0|0] "" Vector__XXX
 SG_ SCS_a126_unused126 : 61|1@1+ (1,0) [0|0] "" Vector__XXX
 SG_ SCS_a127_unused127 : 62|1@1+ (1,0) [0|0] "" Vector__XXX
 SG_ SCS_a128_unused128 : 63|1@1+ (1,0) [0|0] "" Vector__XXX

BO_ 881 RCM_alertMatrix: 8 VEH
 SG_ RCM_matrixIndex M : 0|4@1+ (1,0) [0|0] "" Vector__XXX
 SG_ RCM_a000_crashDetected m0 : 4|1@1+ (1,0) [0|0] "" Vector__XXX
 SG_ RCM_a001_nearDeploy m0 : 5|1@1+ (1,0) [0|0] "" Vector__XXX
 SG_ RCM_a002_airbagsNotArmed m0 : 6|1@1+ (1,0) [0|0] "" Vector__XXX
 SG_ RCM_a003_warningIndicator m0 : 7|1@1+ (1,0) [0|0] "" Vector__XXX
 SG_ RCM_a004_internalFault m0 : 8|1@1+ (1,0) [0|0] "" Vector__XXX
 SG_ RCM_a005_crcError m0 : 9|1@1+ (1,0) [0|0] "" Vector__XXX
 SG_ RCM_a006_batteryVoltageRange m0 : 10|1@1+ (1,0) [0|0] "" Vector__XXX
 SG_ RCM_a007_powerSupplyExternal m0 : 11|1@1+ (1,0) [0|0] "" Vector__XXX
 SG_ RCM_a008_powerSupplyInternal m0 : 12|1@1+ (1,0) [0|0] "" Vector__XXX
 SG_ RCM_a009_reprogramLimit m0 : 13|1@1+ (1,0) [0|0] "" Vector__XXX
 SG_ RCM_a010_scmDisabled m0 : 14|1@1+ (1,0) [0|0] "" Vector__XXX
 SG_ RCM_a011_eepromDataLocked m0 : 15|1@1+ (1,0) [0|0] "" Vector__XXX
 SG_ RCM_a012_vinStorage m0 : 16|1@1+ (1,0) [0|0] "" Vector__XXX
 SG_ RCM_a013_driverOrientation m0 : 17|1@1+ (1,0) [0|0] "" Vector__XXX
 SG_ RCM_a014_driverABStage1 m0 : 18|1@1+ (1,0) [0|0] "" Vector__XXX
 SG_ RCM_a015_driverABStage2 m0 : 19|1@1+ (1,0) [0|0] "" Vector__XXX
 SG_ RCM_a016_passABStage1 m0 : 20|1@1+ (1,0) [0|0] "" Vector__XXX
 SG_ RCM_a017_passABStage2 m0 : 21|1@1+ (1,0) [0|0] "" Vector__XXX
 SG_ RCM_a018_passengerActiveVent m0 : 22|1@1+ (1,0) [0|0] "" Vector__XXX
 SG_ RCM_a019_pretenShldrFrontLeft m0 : 23|1@1+ (1,0) [0|0] "" Vector__XXX
 SG_ RCM_a020_pretenShldFrontRight m0 : 24|1@1+ (1,0) [0|0] "" Vector__XXX
 SG_ RCM_a021_pretenLapFrontLeft m0 : 25|1@1+ (1,0) [0|0] "" Vector__XXX
 SG_ RCM_a022_pretenLapFrontRight m0 : 26|1@1+ (1,0) [0|0] "" Vector__XXX
 SG_ RCM_a023_loadLimiterLeftSide m0 : 27|1@1+ (1,0) [0|0] "" Vector__XXX
 SG_ RCM_a024_loadLimiterRightSide m0 : 28|1@1+ (1,0) [0|0] "" Vector__XXX
 SG_ RCM_a025_kneeABDriver m0 : 29|1@1+ (1,0) [0|0] "" Vector__XXX
 SG_ RCM_a026_kneeABFrontPassenger m0 : 30|1@1+ (1,0) [0|0] "" Vector__XXX
 SG_ RCM_a027_sideAB1stRowLeft m0 : 31|1@1+ (1,0) [0|0] "" Vector__XXX
 SG_ RCM_a028_sideAB1stRowRight m0 : 32|1@1+ (1,0) [0|0] "" Vector__XXX
 SG_ RCM_a029_driverABActiveVent m0 : 33|1@1+ (1,0) [0|0] "" Vector__XXX
 SG_ RCM_a030_farSideInboardAirbag m0 : 34|1@1+ (1,0) [0|0] "" Vector__XXX
 SG_ RCM_a031_frontCenterAirbag m0 : 35|1@1+ (1,0) [0|0] "" Vector__XXX
 SG_ RCM_a032_curtainABLeft m0 : 36|1@1+ (1,0) [0|0] "" Vector__XXX
 SG_ RCM_a033_curtainABRight m0 : 37|1@1+ (1,0) [0|0] "" Vector__XXX
 SG_ RCM_a034_preten2ndRowLeft m0 : 38|1@1+ (1,0) [0|0] "" Vector__XXX
 SG_ RCM_a035_preten2ndRowRight m0 : 39|1@1+ (1,0) [0|0] "" Vector__XXX
 SG_ RCM_a036_curAB2ndRowLeft m0 : 40|1@1+ (1,0) [0|0] "" Vector__XXX
 SG_ RCM_a037_curAB2ndRowRight m0 : 41|1@1+ (1,0) [0|0] "" Vector__XXX
 SG_ RCM_a038_unusedA m0 : 42|1@1+ (1,0) [0|0] "" Vector__XXX
 SG_ RCM_a039_unusedB m0 : 43|1@1+ (1,0) [0|0] "" Vector__XXX
 SG_ RCM_a040_hoodActuatorRight m0 : 44|1@1+ (1,0) [0|0] "" Vector__XXX
 SG_ RCM_a041_hoodActuatorLeft m0 : 45|1@1+ (1,0) [0|0] "" Vector__XXX
 SG_ RCM_a042_ens1Line m0 : 46|1@1+ (1,0) [0|0] "" Vector__XXX
 SG_ RCM_a043_ens2Line m0 : 47|1@1+ (1,0) [0|0] "" Vector__XXX
 SG_ RCM_a044_upFrontSensorLeft m0 : 48|1@1+ (1,0) [0|0] "" Vector__XXX
 SG_ RCM_a045_upFrontSensorRight m0 : 49|1@1+ (1,0) [0|0] "" Vector__XXX
 SG_ RCM_a046_sideAccelBPillarLeft m0 : 50|1@1+ (1,0) [0|0] "" Vector__XXX
 SG_ RCM_a047_sideAccelBPillarRight m0 : 51|1@1+ (1,0) [0|0] "" Vector__XXX
 SG_ RCM_a048_sideAccelCPillarLeft m0 : 52|1@1+ (1,0) [0|0] "" Vector__XXX
 SG_ RCM_a049_sideAccelCPillarRight m0 : 53|1@1+ (1,0) [0|0] "" Vector__XXX
 SG_ RCM_a050_upFrontSensorCenter m0 : 54|1@1+ (1,0) [0|0] "" Vector__XXX
 SG_ RCM_a051_pressureFrontLftDoor m0 : 55|1@1+ (1,0) [0|0] "" Vector__XXX
 SG_ RCM_a052_pressureFrontRtDoor m0 : 56|1@1+ (1,0) [0|0] "" Vector__XXX
 SG_ RCM_a053_pressurePedProLeft m0 : 57|1@1+ (1,0) [0|0] "" Vector__XXX
 SG_ RCM_a054_pressurePedProRight m0 : 58|1@1+ (1,0) [0|0] "" Vector__XXX
 SG_ RCM_a055_inertialMeasurement m0 : 59|1@1+ (1,0) [0|0] "" Vector__XXX
 SG_ RCM_a056_passengerFrontOCS m0 : 60|1@1+ (1,0) [0|0] "" Vector__XXX
 SG_ RCM_a057_driverOCS m0 : 61|1@1+ (1,0) [0|0] "" Vector__XXX
 SG_ RCM_a058_buckle1stRowLeft m0 : 62|1@1+ (1,0) [0|0] "" Vector__XXX
 SG_ RCM_a059_buckle1stRowRight m0 : 63|1@1+ (1,0) [0|0] "" Vector__XXX
 SG_ RCM_a060_stpsLeft m1 : 4|1@1+ (1,0) [0|0] "" Vector__XXX
 SG_ RCM_a061_stpsRight m1 : 5|1@1+ (1,0) [0|0] "" Vector__XXX
 SG_ RCM_a062_alrSwitch m1 : 6|1@1+ (1,0) [0|0] "" Vector__XXX
 SG_ RCM_a063_sbsw2ndRowRight m1 : 7|1@1+ (1,0) [0|0] "" Vector__XXX
 SG_ RCM_a064_hardwareCodingPin1 m1 : 8|1@1+ (1,0) [0|0] "" Vector__XXX
 SG_ RCM_a065_driverOrientConfigPin m1 : 9|1@1+ (1,0) [0|0] "" Vector__XXX
 SG_ RCM_a066_seatBackSw2ndRowLeft m1 : 10|1@1+ (1,0) [0|0] "" Vector__XXX
 SG_ RCM_a067_comCANInitFailure m1 : 11|1@1+ (1,0) [0|0] "" Vector__XXX
 SG_ RCM_a068_comCHOff m1 : 12|1@1+ (1,0) [0|0] "" Vector__XXX
 SG_ RCM_a069_comCHCANPH7 m1 : 13|1@1+ (1,0) [0|0] "" Vector__XXX
 SG_ RCM_a070_comCHCANPH8 m1 : 14|1@1+ (1,0) [0|0] "" Vector__XXX
 SG_ RCM_a071_comCHCANPH9 m1 : 15|1@1+ (1,0) [0|0] "" Vector__XXX
 SG_ RCM_a072_comUnused m1 : 16|1@1+ (1,0) [0|0] "" Vector__XXX
 SG_ RCM_a073_comCHCANPH4 m1 : 17|1@1+ (1,0) [0|0] "" Vector__XXX
 SG_ RCM_a074_comCHCANPH5 m1 : 18|1@1+ (1,0) [0|0] "" Vector__XXX
 SG_ RCM_a075_comCHCANPH6 m1 : 19|1@1+ (1,0) [0|0] "" Vector__XXX
 SG_ RCM_a076_comEPBLStatus m1 : 20|1@1+ (1,0) [0|0] "" Vector__XXX
 SG_ RCM_a077_comEPBRStatus m1 : 21|1@1+ (1,0) [0|0] "" Vector__XXX
 SG_ RCM_a078_comOCS1PStatus m1 : 22|1@1+ (1,0) [0|0] "" Vector__XXX
 SG_ RCM_a079_comOCS1DStatus m1 : 23|1@1+ (1,0) [0|0] "" Vector__XXX
 SG_ RCM_a080_comGTWACS m1 : 24|1@1+ (1,0) [0|0] "" Vector__XXX
 SG_ RCM_a081_comVCFRONTLVPwr m1 : 25|1@1+ (1,0) [0|0] "" Vector__XXX
 SG_ RCM_a082_comUIodo m1 : 26|1@1+ (1,0) [0|0] "" Vector__XXX
 SG_ RCM_a083_comGTWCarState m1 : 27|1@1+ (1,0) [0|0] "" Vector__XXX
 SG_ RCM_a084_comTPMSStatus m1 : 28|1@1+ (1,0) [0|0] "" Vector__XXX
 SG_ RCM_a085_comGTWCarConfig m1 : 29|1@1+ (1,0) [0|0] "" Vector__XXX
 SG_ RCM_a086_comVINMIA m1 : 30|1@1+ (1,0) [0|0] "" Vector__XXX
 SG_ RCM_a087_comCANSilent m1 : 31|1@1+ (1,0) [0|0] "" Vector__XXX
 SG_ RCM_a088_comCHCANPH2 m1 : 32|1@1+ (1,0) [0|0] "" Vector__XXX
 SG_ RCM_a089_comCHCANPH3 m1 : 33|1@1+ (1,0) [0|0] "" Vector__XXX
 SG_ RCM_a090_comPartyBusOff m1 : 34|1@1+ (1,0) [0|0] "" Vector__XXX
 SG_ RCM_a091_comEPAS3PsysStatus m1 : 35|1@1+ (1,0) [0|0] "" Vector__XXX
 SG_ RCM_a092_comDASISF m1 : 36|1@1+ (1,0) [0|0] "" Vector__XXX
 SG_ RCM_a093_comVCLEFTStatus m1 : 37|1@1+ (1,0) [0|0] "" Vector__XXX
 SG_ RCM_a094_comVCRIGHTStatus m1 : 38|1@1+ (1,0) [0|0] "" Vector__XXX
 SG_ RCM_a095_comESPstatus m1 : 39|1@1+ (1,0) [0|0] "" Vector__XXX
 SG_ RCM_a096_comESPwheelSpeeds m1 : 40|1@1+ (1,0) [0|0] "" Vector__XXX
 SG_ RCM_a097_comDIspeed m1 : 41|1@1+ (1,0) [0|0] "" Vector__XXX
 SG_ RCM_a098_comDIchassisControl m1 : 42|1@1+ (1,0) [0|0] "" Vector__XXX
 SG_ RCM_a099_comDItorque m1 : 43|1@1+ (1,0) [0|0] "" Vector__XXX
 SG_ RCM_a100_comDIsystemStatus m1 : 44|1@1+ (1,0) [0|0] "" Vector__XXX
 SG_ RCM_a101_idfSystem m1 : 45|1@1+ (1,0) [0|0] "" Vector__XXX
 SG_ RCM_a102_imuYawR8OffstCompLim m1 : 46|1@1+ (1,0) [0|0] "" Vector__XXX
 SG_ RCM_a103_imuPtchR8OffstCompLim m1 : 47|1@1+ (1,0) [0|0] "" Vector__XXX
 SG_ RCM_a104_imuRollR8OffstCompLim m1 : 48|1@1+ (1,0) [0|0] "" Vector__XXX
 SG_ RCM_a105_imuLongAccOffstCompLim m1 : 49|1@1+ (1,0) [0|0] "" Vector__XXX
 SG_ RCM_a106_imuLatAccOffstCompLim m1 : 50|1@1+ (1,0) [0|0] "" Vector__XXX
 SG_ RCM_a107_imuVertAccOffstCompLim m1 : 51|1@1+ (1,0) [0|0] "" Vector__XXX
 SG_ RCM_a108_crashAlgoWakeup m1 : 52|1@1+ (1,0) [0|0] "" Vector__XXX
 SG_ RCM_a109_abuseImmunity m1 : 53|1@1+ (1,0) [0|0] "" Vector__XXX
 SG_ RCM_a110_factoryMode m1 : 54|1@1+ (1,0) [0|0] "" Vector__XXX
 SG_ RCM_a111_diagnosticsEnabled m1 : 55|1@1+ (1,0) [0|0] "" Vector__XXX
 SG_ RCM_a112_imuYawRate m1 : 56|1@1+ (1,0) [0|0] "" Vector__XXX
 SG_ RCM_a113_imuPitchRate m1 : 57|1@1+ (1,0) [0|0] "" Vector__XXX
 SG_ RCM_a114_imuRollRate m1 : 58|1@1+ (1,0) [0|0] "" Vector__XXX
 SG_ RCM_a115_imuLinearAcceleration m1 : 59|1@1+ (1,0) [0|0] "" Vector__XXX
 SG_ RCM_a116_imuLateralAcceleration m1 : 60|1@1+ (1,0) [0|0] "" Vector__XXX
 SG_ RCM_a117_imuVerticalAcceleration m1 : 61|1@1+ (1,0) [0|0] "" Vector__XXX
 SG_ RCM_a118_imuInPlaneAcceleration m1 : 62|1@1+ (1,0) [0|0] "" Vector__XXX

BO_ 882 EPAS3S_sysStatus: 8 VEH
 SG_ EPAS3S_currentTuneMode : 5|3@1+ (1,0) [0|0] "" Vector__XXX
 SG_ EPAS3S_eacErrorCode : 20|4@1+ (1,0) [0|0] "" Vector__XXX
 SG_ EPAS3S_eacStatus : 53|3@1+ (1,0) [0|0] "" Vector__XXX
 SG_ EPAS3S_handsOnLevel : 38|2@1+ (1,0) [0|0] "" Vector__XXX
 SG_ EPAS3S_internalSAS : 32|14@0+ (0.1,-819.2) [0|0] "deg" Vector__XXX
 SG_ EPAS3S_internalSASQF : 4|1@1+ (1,0) [0|0] "" Vector__XXX
 SG_ EPAS3S_steeringFault : 2|1@1+ (1,0) [0|0] "" Vector__XXX
 SG_ EPAS3S_steeringRackForce : 0|10@0+ (50,-25575) [0|0] "N" Vector__XXX
 SG_ EPAS3S_steeringReduced : 3|1@1+ (1,0) [0|0] "" Vector__XXX
 SG_ EPAS3S_sysStatusChecksum : 56|8@1+ (1,0) [0|0] "" Vector__XXX
 SG_ EPAS3S_sysStatusCounter : 48|4@1+ (1,0) [0|0] "" Vector__XXX
 SG_ EPAS3S_torsionBarTorque : 16|12@0+ (0.01,-20.5) [0|0] "Nm" Vector__XXX

BO_ 883 EPAS3P_sysStatus: 8 VEH
 SG_ EPAS3P_currentTuneMode : 5|3@1+ (1,0) [0|0] "" Vector__XXX
 SG_ EPAS3P_eacErrorCode : 20|4@1+ (1,0) [0|0] "" Vector__XXX
 SG_ EPAS3P_eacStatus : 53|3@1+ (1,0) [0|0] "" Vector__XXX
 SG_ EPAS3P_handsOnLevel : 38|2@1+ (1,0) [0|0] "" Vector__XXX
 SG_ EPAS3P_internalSAS : 32|14@0+ (0.1,-819.2) [0|0] "deg" Vector__XXX
 SG_ EPAS3P_internalSASQF : 4|1@1+ (1,0) [0|0] "" Vector__XXX
 SG_ EPAS3P_steeringFault : 2|1@1+ (1,0) [0|0] "" Vector__XXX
 SG_ EPAS3P_steeringRackForce : 0|10@0+ (50,-25575) [0|0] "N" Vector__XXX
 SG_ EPAS3P_steeringReduced : 3|1@1+ (1,0) [0|0] "" Vector__XXX
 SG_ EPAS3P_sysStatusChecksum : 56|8@1+ (1,0) [0|0] "" Vector__XXX
 SG_ EPAS3P_sysStatusCounter : 48|4@1+ (1,0) [0|0] "" Vector__XXX
 SG_ EPAS3P_torsionBarTorque : 16|12@0+ (0.01,-20.5) [0|0] "Nm" Vector__XXX

BO_ 886 DI_frontTemperature: 8 VEH
 SG_ DI_frontPcbT : 0|8@1+ (1,-40) [0|0] "DegC" Vector__XXX
 SG_ DI_frontInverterT : 8|8@1+ (1,-40) [0|0] "DegC" Vector__XXX
 SG_ DI_frontStatorT : 16|8@1+ (1,-40) [0|0] "DegC" Vector__XXX
 SG_ DI_frontDcCapT : 24|8@1+ (1,-40) [0|0] "DegC" Vector__XXX
 SG_ DI_frontHeatsinkT : 32|8@1+ (1,-40) [0|0] "DegC" Vector__XXX
 SG_ DI_frontInverterTpct : 40|8@1+ (0.4,0) [0|0] "%" Vector__XXX
 SG_ DI_frontStatorTpct : 48|8@1+ (0.4,0) [0|0] "%" Vector__XXX
 SG_ DI_frontInverterTQF : 56|2@1+ (1,0) [0|0] "" Vector__XXX

BO_ 888 GTW_ECall: 1 VEH
 SG_ GTW_GSM_ECALL_nLOCK : 0|1@1+ (1,0) [0|0] "" Vector__XXX

BO_ 890 DAS_telemetryPeriodic: 8 VEH
 SG_ DAS_TP_multiplexer M : 0|5@1+ (1,0) [0|0] "" Vector__XXX
 SG_ DAS_TP_counter m0 : 5|3@1+ (1,0) [0|0] "" Vector__XXX
 SG_ DAS_TP_vlWidth m0 : 8|8@1+ (0.05,0) [0|0] "m" Vector__XXX
 SG_ DAS_TP_hppError m0 : 16|6@1+ (0.05,0) [0|0] "m" Vector__XXX
 SG_ DAS_TP_wipersActive m0 : 22|1@1+ (1,0) [0|0] "" Vector__XXX
 SG_ DAS_TP_handsOn m0 : 23|1@1+ (1,0) [0|0] "" Vector__XXX
 SG_ DAS_TP_sonicDistL m0 : 24|9@1+ (0.01,0) [0|0] "m" Vector__XXX
 SG_ DAS_TP_sonicDistR m0 : 33|9@1+ (0.01,0) [0|0] "m" Vector__XXX
 SG_ DAS_TP_hppValid m0 : 42|1@1+ (1,0) [0|0] "" Vector__XXX
 SG_ DAS_TP_restrictedAccess m0 : 43|1@1+ (1,0) [0|0] "" Vector__XXX
 SG_ DAS_TP_vehFuse m0 : 44|1@1+ (1,0) [0|0] "" Vector__XXX
 SG_ DAS_TP_accRestricted m0 : 46|1@1+ (1,0) [0|0] "" Vector__XXX
 SG_ DAS_TP_laneChange m0 : 48|2@1+ (1,0) [0|0] "" Vector__XXX
 SG_ DAS_TP_llType m0 : 50|3@1+ (1,0) [0|0] "" Vector__XXX
 SG_ DAS_TP_rlType m0 : 53|3@1+ (1,0) [0|0] "" Vector__XXX
 SG_ DAS_TP_plannerState m0 : 56|4@1+ (1,0) [0|0] "" Vector__XXX
 SG_ DAS_TP_lcState m0 : 60|4@1+ (1,0) [0|0] "" Vector__XXX
 SG_ DAS_TP_llCounter m1 : 5|3@1+ (1,0) [0|0] "" Vector__XXX
 SG_ DAS_TP_llC0 m1 : 8|10@1- (0.02,0) [0|0] "m" Vector__XXX
 SG_ DAS_TP_llC1 m1 : 18|9@1- (0.00195313,0) [0|0] "rad" Vector__XXX
 SG_ DAS_TP_llC2 m1 : 27|14@1- (4e-06,0) [0|0] "1/m" Vector__XXX
 SG_ DAS_TP_llC3 m1 : 41|14@1- (1.6e-08,0) [0|0] "1/m2" Vector__XXX
 SG_ DAS_TP_llQlty m1 : 55|1@1+ (1,0) [0|0] "" Vector__XXX
 SG_ DAS_TP_llRange m1 : 56|7@1+ (1,0) [0|0] "m" Vector__XXX
 SG_ DAS_TP_llFuse m1 : 63|1@1+ (1,0) [0|0] "" Vector__XXX
 SG_ DAS_TP_rlCounter m2 : 5|3@1+ (1,0) [0|0] "" Vector__XXX
 SG_ DAS_TP_rlC0 m2 : 8|10@1- (0.02,0) [0|0] "m" Vector__XXX
 SG_ DAS_TP_rlC1 m2 : 18|9@1- (0.00195313,0) [0|0] "rad" Vector__XXX
 SG_ DAS_TP_rlC2 m2 : 27|14@1- (4e-06,0) [0|0] "1/m" Vector__XXX
 SG_ DAS_TP_rlC3 m2 : 41|14@1- (1.6e-08,0) [0|0] "1/m2" Vector__XXX
 SG_ DAS_TP_rlQlty m2 : 55|1@1+ (1,0) [0|0] "" Vector__XXX
 SG_ DAS_TP_rlRange m2 : 56|7@1+ (1,0) [0|0] "m" Vector__XXX
 SG_ DAS_TP_rlFuse m2 : 63|1@1+ (1,0) [0|0] "" Vector__XXX
 SG_ DAS_TP_hppCounter m3 : 5|3@1+ (1,0) [0|0] "" Vector__XXX
 SG_ DAS_TP_hppC0 m3 : 8|10@1- (0.02,0) [0|0] "m" Vector__XXX
 SG_ DAS_TP_hppC1 m3 : 18|9@1- (0.00195313,0) [0|0] "rad" Vector__XXX
 SG_ DAS_TP_hppC2 m3 : 27|14@1- (4e-06,0) [0|0] "1/m" Vector__XXX
 SG_ DAS_TP_hppC3 m3 : 41|14@1- (1.6e-08,0) [0|0] "1/m2" Vector__XXX
 SG_ DAS_TP_hppQlty m3 : 55|1@1+ (1,0) [0|0] "" Vector__XXX
 SG_ DAS_TP_hppRange m3 : 56|7@1+ (1,0) [0|0] "m" Vector__XXX
 SG_ DAS_TP_hppFuse m3 : 63|1@1+ (1,0) [0|0] "" Vector__XXX
 SG_ DAS_TP_navCounter m4 : 5|3@1+ (1,0) [0|0] "" Vector__XXX
 SG_ DAS_TP_navC0 m4 : 8|10@1- (0.02,0) [0|0] "m" Vector__XXX
 SG_ DAS_TP_navC1 m4 : 18|9@1- (0.00195313,0) [0|0] "rad" Vector__XXX
 SG_ DAS_TP_navC2 m4 : 27|14@1- (4e-06,0) [0|0] "1/m" Vector__XXX
 SG_ DAS_TP_navC3 m4 : 41|14@1- (1.6e-08,0) [0|0] "1/m2" Vector__XXX
 SG_ DAS_TP_navQlty m4 : 55|1@1+ (1,0) [0|0] "" Vector__XXX
 SG_ DAS_TP_navRange m4 : 56|7@1+ (1,0) [0|0] "m" Vector__XXX
 SG_ DAS_TP_navFuse m4 : 63|1@1+ (1,0) [0|0] "" Vector__XXX
 SG_ DAS_TP_vlCounter m5 : 5|3@1+ (1,0) [0|0] "" Vector__XXX
 SG_ DAS_TP_vlC0 m5 : 8|10@1- (0.02,0) [0|0] "m" Vector__XXX
 SG_ DAS_TP_vlC1 m5 : 18|9@1- (0.00195313,0) [0|0] "rad" Vector__XXX
 SG_ DAS_TP_vlC2 m5 : 27|14@1- (4e-06,0) [0|0] "1/m" Vector__XXX
 SG_ DAS_TP_vlC3 m5 : 41|14@1- (1.6e-08,0) [0|0] "1/m2" Vector__XXX
 SG_ DAS_TP_vlQlty m5 : 55|1@1+ (1,0) [0|0] "" Vector__XXX
 SG_ DAS_TP_vlRange m5 : 56|7@1+ (1,0) [0|0] "m" Vector__XXX
 SG_ DAS_TP_vlFuse m5 : 63|1@1+ (1,0) [0|0] "" Vector__XXX
 SG_ DAS_TP_bdlCounter m6 : 5|3@1+ (1,0) [0|0] "" Vector__XXX
 SG_ DAS_TP_bdlC0 m6 : 8|10@1- (0.02,0) [0|0] "m" Vector__XXX
 SG_ DAS_TP_bdlC1 m6 : 18|9@1- (0.00195313,0) [0|0] "rad" Vector__XXX
 SG_ DAS_TP_bdlC2 m6 : 27|14@1- (4e-06,0) [0|0] "1/m" Vector__XXX
 SG_ DAS_TP_bdlC3 m6 : 41|14@1- (1.6e-08,0) [0|0] "1/m2" Vector__XXX
 SG_ DAS_TP_bdlQlty m6 : 55|1@1+ (1,0) [0|0] "" Vector__XXX
 SG_ DAS_TP_bdlRange m6 : 56|7@1+ (1,0) [0|0] "m" Vector__XXX
 SG_ DAS_TP_bdlFuse m6 : 63|1@1+ (1,0) [0|0] "" Vector__XXX
 SG_ DAS_TP_bdrCounter m7 : 5|3@1+ (1,0) [0|0] "" Vector__XXX
 SG_ DAS_TP_bdrC0 m7 : 8|10@1- (0.02,0) [0|0] "m" Vector__XXX
 SG_ DAS_TP_bdrC1 m7 : 18|9@1- (0.00195313,0) [0|0] "rad" Vector__XXX
 SG_ DAS_TP_bdrC2 m7 : 27|14@1- (4e-06,0) [0|0] "1/m" Vector__XXX
 SG_ DAS_TP_bdrC3 m7 : 41|14@1- (1.6e-08,0) [0|0] "1/m2" Vector__XXX
 SG_ DAS_TP_bdrQlty m7 : 55|1@1+ (1,0) [0|0] "" Vector__XXX
 SG_ DAS_TP_bdrRange m7 : 56|7@1+ (1,0) [0|0] "m" Vector__XXX
 SG_ DAS_TP_bdrFuse m7 : 63|1@1+ (1,0) [0|0] "" Vector__XXX
 SG_ DAS_TP_laneCounter m8 : 5|3@1+ (1,0) [0|0] "" Vector__XXX
 SG_ DAS_TP_llSegQ1 m8 : 8|4@1+ (10,0) [0|0] "%" Vector__XXX
 SG_ DAS_TP_llSegQ2 m8 : 12|4@1+ (10,0) [0|0] "%" Vector__XXX
 SG_ DAS_TP_llSegQ3 m8 : 16|4@1+ (10,0) [0|0] "%" Vector__XXX
 SG_ DAS_TP_llSegQ4 m8 : 20|4@1+ (10,0) [0|0] "%" Vector__XXX
 SG_ DAS_TP_rlSegQ1 m8 : 24|4@1+ (10,0) [0|0] "%" Vector__XXX
 SG_ DAS_TP_rlSegQ2 m8 : 28|4@1+ (10,0) [0|0] "%" Vector__XXX
 SG_ DAS_TP_rlSegQ3 m8 : 32|4@1+ (10,0) [0|0] "%" Vector__XXX
 SG_ DAS_TP_rlSegQ4 m8 : 36|4@1+ (10,0) [0|0] "%" Vector__XXX
 SG_ DAS_TP_llExist m8 : 40|4@1+ (10,0) [0|0] "%" Vector__XXX
 SG_ DAS_TP_rlExist m8 : 44|4@1+ (10,0) [0|0] "%" Vector__XXX
 SG_ DAS_TP_nllProb m8 : 48|4@1+ (0.1,0) [0|0] "1" Vector__XXX
 SG_ DAS_TP_nrlProb m8 : 52|4@1+ (0.1,0) [0|0] "1" Vector__XXX
 SG_ DAS_TP_llQltyME m8 : 56|2@1+ (1,0) [0|0] "" Vector__XXX
 SG_ DAS_TP_rlQltyME m8 : 58|2@1+ (1,0) [0|0] "" Vector__XXX
 SG_ DAS_TP_bdlQltyME m8 : 60|2@1+ (1,0) [0|0] "" Vector__XXX
 SG_ DAS_TP_bdrQltyME m8 : 62|2@1+ (1,0) [0|0] "" Vector__XXX
 SG_ DAS_TP_llrCounter m9 : 5|3@1+ (1,0) [0|0] "" Vector__XXX
 SG_ DAS_TP_numLanes m9 : 8|3@1+ (1,0) [0|0] "" Vector__XXX
 SG_ DAS_TP_lane1LLR m9 : 11|6@1+ (0.3125,-10) [0|0] "1" Vector__XXX
 SG_ DAS_TP_lane2LLR m9 : 17|6@1+ (0.3125,-10) [0|0] "1" Vector__XXX
 SG_ DAS_TP_lane3LLR m9 : 23|6@1+ (0.3125,-10) [0|0] "1" Vector__XXX
 SG_ DAS_TP_lane4LLR m9 : 29|6@1+ (0.3125,-10) [0|0] "1" Vector__XXX
 SG_ DAS_TP_lane5LLR m9 : 35|6@1+ (0.3125,-10) [0|0] "1" Vector__XXX
 SG_ DAS_TP_lane6LLR m9 : 41|6@1+ (0.3125,-10) [0|0] "1" Vector__XXX
 SG_ DAS_TP_lane7LLR m9 : 47|6@1+ (0.3125,-10) [0|0] "1" Vector__XXX
 SG_ DAS_TP_lane8LLR m9 : 53|6@1+ (0.3125,-10) [0|0] "1" Vector__XXX
 SG_ DAS_TP_egoLane m9 : 59|3@1+ (1,0) [0|0] "" Vector__XXX

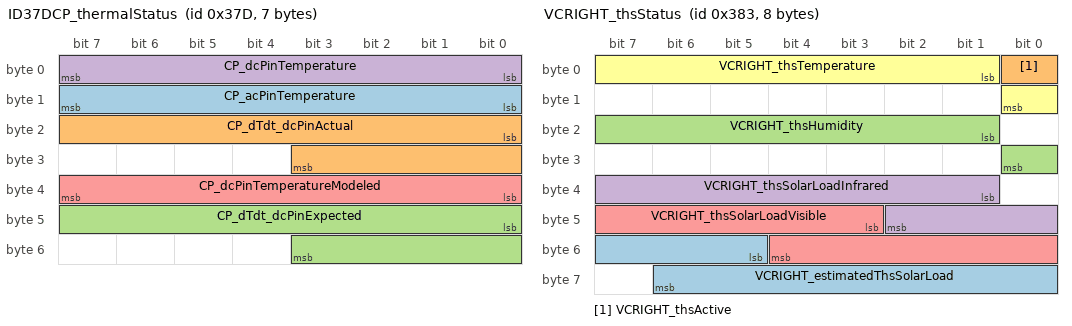
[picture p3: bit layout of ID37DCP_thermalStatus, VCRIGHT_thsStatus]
BO_ 893 ID37DCP_thermalStatus: 7 VehicleBus
 SG_ CP_acPinTemperature : 8|8@1+ (0.803922,-55) [-55|149.99] "C"  Receiver
 SG_ CP_dTdt_dcPinActual : 16|12@1+ (0.005,-10) [-10|10] "C"  Receiver
 SG_ CP_dTdt_dcPinExpected : 40|12@1+ (0.005,-10) [-10|10] "C"  Receiver
 SG_ CP_dcPinTemperature : 0|8@1+ (0.803922,-55) [-55|149.99] "C"  Receiver
 SG_ CP_dcPinTemperatureModeled : 32|8@1+ (0.803922,-55) [-55|149.99] "C"  Receiver

BO_ 894 PARK_warningMatrix: 8 CH
 SG_ PARK_matrixIndex M : 0|4@1+ (1,0) [0|0] "" Vector__XXX
 SG_ PARK_a001_s1_overTemp m0 : 4|1@1+ (1,0) [0|0] "" Vector__XXX
 SG_ PARK_a002_s1_internalFail m0 : 5|1@1+ (1,0) [0|0] "" Vector__XXX
 SG_ PARK_a003_s1_linCommError m0 : 6|1@1+ (1,0) [0|0] "" Vector__XXX
 SG_ PARK_a004_s1_blocked m0 : 7|1@1+ (1,0) [0|0] "" Vector__XXX
 SG_ PARK_a005_s1_crossTalk m0 : 8|1@1+ (1,0) [0|0] "" Vector__XXX
 SG_ PARK_a006_s2_overTemp m0 : 9|1@1+ (1,0) [0|0] "" Vector__XXX
 SG_ PARK_a007_s2_internalFail m0 : 10|1@1+ (1,0) [0|0] "" Vector__XXX
 SG_ PARK_a008_s2_linCommError m0 : 11|1@1+ (1,0) [0|0] "" Vector__XXX
 SG_ PARK_a009_s2_blocked m0 : 12|1@1+ (1,0) [0|0] "" Vector__XXX
 SG_ PARK_a010_s2_crossTalk m0 : 13|1@1+ (1,0) [0|0] "" Vector__XXX
 SG_ PARK_a011_s3_overTemp m0 : 14|1@1+ (1,0) [0|0] "" Vector__XXX
 SG_ PARK_a012_s3_internalFail m0 : 15|1@1+ (1,0) [0|0] "" Vector__XXX
 SG_ PARK_a013_s3_linCommError m0 : 16|1@1+ (1,0) [0|0] "" Vector__XXX
 SG_ PARK_a014_s3_blocked m0 : 17|1@1+ (1,0) [0|0] "" Vector__XXX
 SG_ PARK_a015_s3_crossTalk m0 : 18|1@1+ (1,0) [0|0] "" Vector__XXX
 SG_ PARK_a016_s4_overTemp m0 : 19|1@1+ (1,0) [0|0] "" Vector__XXX
 SG_ PARK_a017_s4_internalFail m0 : 20|1@1+ (1,0) [0|0] "" Vector__XXX
 SG_ PARK_a018_s4_linCommError m0 : 21|1@1+ (1,0) [0|0] "" Vector__XXX
 SG_ PARK_a019_s4_blocked m0 : 22|1@1+ (1,0) [0|0] "" Vector__XXX
 SG_ PARK_a020_s4_crossTalk m0 : 23|1@1+ (1,0) [0|0] "" Vector__XXX
 SG_ PARK_a021_s5_overTemp m0 : 24|1@1+ (1,0) [0|0] "" Vector__XXX
 SG_ PARK_a022_s5_internalFail m0 : 25|1@1+ (1,0) [0|0] "" Vector__XXX
 SG_ PARK_a023_s5_linCommError m0 : 26|1@1+ (1,0) [0|0] "" Vector__XXX
 SG_ PARK_a024_s5_blocked m0 : 27|1@1+ (1,0) [0|0] "" Vector__XXX
 SG_ PARK_a025_s5_crossTalk m0 : 28|1@1+ (1,0) [0|0] "" Vector__XXX
 SG_ PARK_a026_s6_overTemp m0 : 29|1@1+ (1,0) [0|0] "" Vector__XXX
 SG_ PARK_a027_s6_internalFail m0 : 30|1@1+ (1,0) [0|0] "" Vector__XXX
 SG_ PARK_a028_s6_linCommError m0 : 31|1@1+ (1,0) [0|0] "" Vector__XXX
 SG_ PARK_a029_s6_blocked m0 : 32|1@1+ (1,0) [0|0] "" Vector__XXX
 SG_ PARK_a030_s6_crossTalk m0 : 33|1@1+ (1,0) [0|0] "" Vector__XXX
 SG_ PARK_a031_s7_overTemp m0 : 34|1@1+ (1,0) [0|0] "" Vector__XXX
 SG_ PARK_a032_s7_internalFail m0 : 35|1@1+ (1,0) [0|0] "" Vector__XXX
 SG_ PARK_a033_s7_linCommError m0 : 36|1@1+ (1,0) [0|0] "" Vector__XXX
 SG_ PARK_a034_s7_blocked m0 : 37|1@1+ (1,0) [0|0] "" Vector__XXX
 SG_ PARK_a035_s7_crossTalk m0 : 38|1@1+ (1,0) [0|0] "" Vector__XXX
 SG_ PARK_a036_s8_overTemp m0 : 39|1@1+ (1,0) [0|0] "" Vector__XXX
 SG_ PARK_a037_s8_internalFail m0 : 40|1@1+ (1,0) [0|0] "" Vector__XXX
 SG_ PARK_a038_s8_linCommError m0 : 41|1@1+ (1,0) [0|0] "" Vector__XXX
 SG_ PARK_a039_s8_blocked m0 : 42|1@1+ (1,0) [0|0] "" Vector__XXX
 SG_ PARK_a040_s8_crossTalk m0 : 43|1@1+ (1,0) [0|0] "" Vector__XXX
 SG_ PARK_a041_s9_overTemp m0 : 44|1@1+ (1,0) [0|0] "" Vector__XXX
 SG_ PARK_a042_s9_internalFail m0 : 45|1@1+ (1,0) [0|0] "" Vector__XXX
 SG_ PARK_a043_s9_linCommError m0 : 46|1@1+ (1,0) [0|0] "" Vector__XXX
 SG_ PARK_a044_s9_blocked m0 : 47|1@1+ (1,0) [0|0] "" Vector__XXX
 SG_ PARK_a045_s9_crossTalk m0 : 48|1@1+ (1,0) [0|0] "" Vector__XXX
 SG_ PARK_a046_s10_overTemp m0 : 49|1@1+ (1,0) [0|0] "" Vector__XXX
 SG_ PARK_a047_s10_internalFail m0 : 50|1@1+ (1,0) [0|0] "" Vector__XXX
 SG_ PARK_a048_s10_linCommError m0 : 51|1@1+ (1,0) [0|0] "" Vector__XXX
 SG_ PARK_a049_s10_blocked m0 : 52|1@1+ (1,0) [0|0] "" Vector__XXX
 SG_ PARK_a050_s10_crossTalk m0 : 53|1@1+ (1,0) [0|0] "" Vector__XXX
 SG_ PARK_a051_s11_overTemp m0 : 54|1@1+ (1,0) [0|0] "" Vector__XXX
 SG_ PARK_a052_s11_internalFail m0 : 55|1@1+ (1,0) [0|0] "" Vector__XXX
 SG_ PARK_a053_s11_linCommError m0 : 56|1@1+ (1,0) [0|0] "" Vector__XXX
 SG_ PARK_a054_s11_blocked m0 : 57|1@1+ (1,0) [0|0] "" Vector__XXX
 SG_ PARK_a055_s11_crossTalk m0 : 58|1@1+ (1,0) [0|0] "" Vector__XXX
 SG_ PARK_a056_s12_overTemp m0 : 59|1@1+ (1,0) [0|0] "" Vector__XXX
 SG_ PARK_a057_s12_internalFail m0 : 60|1@1+ (1,0) [0|0] "" Vector__XXX
 SG_ PARK_a058_s12_linCommError m0 : 61|1@1+ (1,0) [0|0] "" Vector__XXX
 SG_ PARK_a059_s12_blocked m0 : 62|1@1+ (1,0) [0|0] "" Vector__XXX
 SG_ PARK_a060_s12_crossTalk m0 : 63|1@1+ (1,0) [0|0] "" Vector__XXX
 SG_ PARK_a061_ecuUnderVoltage m1 : 4|1@1+ (1,0) [0|0] "" Vector__XXX
 SG_ PARK_a062_ecuOverVoltage m1 : 5|1@1+ (1,0) [0|0] "" Vector__XXX
 SG_ PARK_a063_sensorVoltage m1 : 6|1@1+ (1,0) [0|0] "" Vector__XXX
 SG_ PARK_a064_ecuFault m1 : 7|1@1+ (1,0) [0|0] "" Vector__XXX
 SG_ PARK_a065_crcFault m1 : 8|1@1+ (1,0) [0|0] "" Vector__XXX
 SG_ PARK_a066_calibrationMissing m1 : 9|1@1+ (1,0) [0|0] "" Vector__XXX
 SG_ PARK_a067_privateCANBusOff m1 : 10|1@1+ (1,0) [0|0] "" Vector__XXX
 SG_ PARK_a068_hardwareWatchDog m1 : 11|1@1+ (1,0) [0|0] "" Vector__XXX
 SG_ PARK_a069_dasMia m1 : 12|1@1+ (1,0) [0|0] "" Vector__XXX
 SG_ PARK_a070_sccmMia m1 : 13|1@1+ (1,0) [0|0] "" Vector__XXX
 SG_ PARK_a071_diMia m1 : 14|1@1+ (1,0) [0|0] "" Vector__XXX
 SG_ PARK_a072_epasMia m1 : 15|1@1+ (1,0) [0|0] "" Vector__XXX
 SG_ PARK_a073_epbMia m1 : 16|1@1+ (1,0) [0|0] "" Vector__XXX
 SG_ PARK_a074_espMia m1 : 17|1@1+ (1,0) [0|0] "" Vector__XXX
 SG_ PARK_a075_rcmMia m1 : 18|1@1+ (1,0) [0|0] "" Vector__XXX
 SG_ PARK_a076_vcFrontMia m1 : 19|1@1+ (1,0) [0|0] "" Vector__XXX
 SG_ PARK_a077_dasError m1 : 20|1@1+ (1,0) [0|0] "" Vector__XXX
 SG_ PARK_a078_diError m1 : 21|1@1+ (1,0) [0|0] "" Vector__XXX
 SG_ PARK_a079_epasError m1 : 22|1@1+ (1,0) [0|0] "" Vector__XXX
 SG_ PARK_a080_epbError m1 : 23|1@1+ (1,0) [0|0] "" Vector__XXX
 SG_ PARK_a081_espError m1 : 24|1@1+ (1,0) [0|0] "" Vector__XXX
 SG_ PARK_a082_rcmError m1 : 25|1@1+ (1,0) [0|0] "" Vector__XXX
 SG_ PARK_a083_vcFrontError m1 : 26|1@1+ (1,0) [0|0] "" Vector__XXX
 SG_ PARK_a084_sccmError m1 : 27|1@1+ (1,0) [0|0] "" Vector__XXX
 SG_ PARK_a085_watchdogReset m1 : 28|1@1+ (1,0) [0|0] "" Vector__XXX
 SG_ PARK_a086_nvmFault m1 : 29|1@1+ (1,0) [0|0] "" Vector__XXX

BO_ 895 FC_alertMatrix3: 8 VEH
 SG_ FC_a129_CA_flyback_HW_OC : 0|1@1+ (1,0) [0|0] "" Vector__XXX
 SG_ FC_a130_CA_flyback_SW_OV : 1|1@1+ (1,0) [0|0] "" Vector__XXX
 SG_ FC_a131_CA_flyback_HW_OV : 2|1@1+ (1,0) [0|0] "" Vector__XXX
 SG_ FC_a132_CA_bmsMia : 3|1@1+ (1,0) [0|0] "" Vector__XXX
 SG_ FC_a133_CA_evseMia : 4|1@1+ (1,0) [0|0] "" Vector__XXX
 SG_ FC_a134_CA_vehTxBufOvf : 5|1@1+ (1,0) [0|0] "" Vector__XXX
 SG_ FC_a135_CA_vehRxBufOvf : 6|1@1+ (1,0) [0|0] "" Vector__XXX
 SG_ FC_a136_CA_evseTxBufOvf : 7|1@1+ (1,0) [0|0] "" Vector__XXX
 SG_ FC_a137_CA_evseRxBufOvf : 8|1@1+ (1,0) [0|0] "" Vector__XXX
 SG_ FC_a138_CA_hwProxTrip : 9|1@1+ (1,0) [0|0] "" Vector__XXX
 SG_ FC_a139_CA_ss2NotLow : 10|1@1+ (1,0) [0|0] "" Vector__XXX
 SG_ FC_a140_CA_bmsIncompatible : 11|1@1+ (1,0) [0|0] "" Vector__XXX
 SG_ FC_a141_CA_vehConn_OT : 12|1@1+ (1,0) [0|0] "" Vector__XXX
 SG_ FC_a142_CA_evseConn_OT : 13|1@1+ (1,0) [0|0] "" Vector__XXX
 SG_ FC_a143_CA_pcb_OT : 14|1@1+ (1,0) [0|0] "" Vector__XXX
 SG_ FC_a144_CA_flybackUnstable : 15|1@1+ (1,0) [0|0] "" Vector__XXX
 SG_ FC_a145_CA_flybackDataStale : 16|1@1+ (1,0) [0|0] "" Vector__XXX
 SG_ FC_a146_CA_flybackBusLoadHi : 17|1@1+ (1,0) [0|0] "" Vector__XXX
 SG_ FC_a147_CA_vehConn_UT : 18|1@1+ (1,0) [0|0] "" Vector__XXX
 SG_ FC_a148_CA_evseConn_UT : 19|1@1+ (1,0) [0|0] "" Vector__XXX
 SG_ FC_a149_CA_pcb_UT : 20|1@1+ (1,0) [0|0] "" Vector__XXX
 SG_ FC_a150_CA_vehToEvseDeltaHi : 21|1@1+ (1,0) [0|0] "" Vector__XXX
 SG_ FC_a151_CA_vehToEvseDeltaLo : 22|1@1+ (1,0) [0|0] "" Vector__XXX
 SG_ FC_a152_CA_vehToPcbDeltaHi : 23|1@1+ (1,0) [0|0] "" Vector__XXX
 SG_ FC_a153_CA_evseToPcbDeltaHi : 24|1@1+ (1,0) [0|0] "" Vector__XXX
 SG_ FC_a154_CA_vehToPcbDeltaLo : 25|1@1+ (1,0) [0|0] "" Vector__XXX
 SG_ FC_a155_CA_evseToPcbDeltaLo : 26|1@1+ (1,0) [0|0] "" Vector__XXX
 SG_ FC_a156_CA_flybackRunTimeout : 27|1@1+ (1,0) [0|0] "" Vector__XXX
 SG_ FC_a157_CA_unused : 28|1@1+ (1,0) [0|0] "" Vector__XXX
 SG_ FC_a158_CA_evseOverCurrent : 29|1@1+ (1,0) [0|0] "" Vector__XXX
 SG_ FC_a159_CA_wdtExpired : 30|1@1+ (1,0) [0|0] "" Vector__XXX
 SG_ FC_a160_CA_ss2Deasserted : 31|1@1+ (1,0) [0|0] "" Vector__XXX
 SG_ FC_a161_CA_vehTempHiFoldBk : 32|1@1+ (1,0) [0|0] "" Vector__XXX
 SG_ FC_a162_CA_evseTempHiFoldBk : 33|1@1+ (1,0) [0|0] "" Vector__XXX
 SG_ FC_a163_CA_pcbTempHiFoldBk : 34|1@1+ (1,0) [0|0] "" Vector__XXX
 SG_ FC_a164_CA_proxDisconnected : 35|1@1+ (1,0) [0|0] "" Vector__XXX
 SG_ FC_a165_CA_evseConnUnlocked : 36|1@1+ (1,0) [0|0] "" Vector__XXX
 SG_ FC_a166_CA_vehConnUnlocked : 37|1@1+ (1,0) [0|0] "" Vector__XXX
 SG_ FC_a167_CA_isoVoltageLow : 38|1@1+ (1,0) [0|0] "" Vector__XXX
 SG_ FC_a168_CA_proxTimeout : 39|1@1+ (1,0) [0|0] "" Vector__XXX
 SG_ FC_a169_CA_pilotAcceptTimeout : 40|1@1+ (1,0) [0|0] "" Vector__XXX
 SG_ FC_a170_CA_vehDataTimeout : 41|1@1+ (1,0) [0|0] "" Vector__XXX
 SG_ FC_a171_CA_vehConLockTimeout : 42|1@1+ (1,0) [0|0] "" Vector__XXX
 SG_ FC_a172_CA_ss2LowTimeout : 43|1@1+ (1,0) [0|0] "" Vector__XXX
 SG_ FC_a173_CA_evseDataTimeout : 44|1@1+ (1,0) [0|0] "" Vector__XXX
 SG_ FC_a174_CA_vehReadyTimeout : 45|1@1+ (1,0) [0|0] "" Vector__XXX
 SG_ FC_a175_CA_evseIsoTestTimeout : 46|1@1+ (1,0) [0|0] "" Vector__XXX
 SG_ FC_a176_CA_chargingBusTimeout : 47|1@1+ (1,0) [0|0] "" Vector__XXX
 SG_ FC_a177_CA_bmsCtrCloseTimeout : 48|1@1+ (1,0) [0|0] "" Vector__XXX
 SG_ FC_a178_CA_evseStartTimeout : 49|1@1+ (1,0) [0|0] "" Vector__XXX
 SG_ FC_a179_CA_startupProblem : 50|1@1+ (1,0) [0|0] "" Vector__XXX
 SG_ FC_a180_CA_chargingProblem : 51|1@1+ (1,0) [0|0] "" Vector__XXX
 SG_ FC_a181_CA_vRegBrownout : 52|1@1+ (1,0) [0|0] "" Vector__XXX
 SG_ FC_a182_CA_evseChrMalfunc : 53|1@1+ (1,0) [0|0] "" Vector__XXX
 SG_ FC_a183_CA_evseBatIncompat : 54|1@1+ (1,0) [0|0] "" Vector__XXX
 SG_ FC_a184_CA_evseBatMalfunc : 55|1@1+ (1,0) [0|0] "" Vector__XXX
 SG_ FC_a185_CA_vehReadyDeasserted : 56|1@1+ (1,0) [0|0] "" Vector__XXX
 SG_ FC_a186_CA_fcContOpenTimeout : 57|1@1+ (1,0) [0|0] "" Vector__XXX
 SG_ FC_a187_CA_evseConLockTimeout : 58|1@1+ (1,0) [0|0] "" Vector__XXX

BO_ 897 VCFRONT_logging1Hz: 8 VEH
 SG_ VCFRONT_logging1HzIndex M : 0|5@1+ (1,0) [0|19] ""  Receiver
 SG_ VCFRONT_CCQdotActual m9 : 21|7@1+ (80,0) [0|10100] "W"  Receiver
 SG_ VCFRONT_CCQdotFdFrwrdTarget m9 : 7|7@1+ (80,0) [0|10100] "W"  Receiver
 SG_ VCFRONT_CCQdotFdbk m9 : 14|7@1- (80,0) [-5000|5000] "W"  Receiver
 SG_ VCFRONT_CMPDischargeSuperheat m8 : 17|5@1- (1,6) [-10|21] "C"  Receiver
 SG_ VCFRONT_DIQdotA m9 : 42|7@1+ (80,0) [0|10000] "W"  Receiver
 SG_ VCFRONT_HCML_bladeTemp m3 : 32|8@1- (1,67) [-60|194] "C"  Receiver
 SG_ VCFRONT_HCML_diffuseTemp m3 : 40|8@1- (1,67) [-60|194] "C"  Receiver
 SG_ VCFRONT_HCML_highBeamTemp m3 : 16|8@1- (1,67) [-60|194] "C"  Receiver
 SG_ VCFRONT_HCML_lowBeamSpotTemp m3 : 8|8@1- (1,67) [-60|194] "C"  Receiver
 SG_ VCFRONT_HCML_turnTemp m3 : 24|8@1- (1,67) [-60|194] "C"  Receiver
 SG_ VCFRONT_HCMR_bladeTemp m4 : 32|8@1- (1,67) [-60|194] "C"  Receiver
 SG_ VCFRONT_HCMR_diffuseTemp m4 : 40|8@1- (1,67) [-60|194] "C"  Receiver
 SG_ VCFRONT_HCMR_highBeamTemp m4 : 16|8@1- (1,67) [-60|194] "C"  Receiver
 SG_ VCFRONT_HCMR_lowBeamSpotTemp m4 : 8|8@1- (1,67) [-60|194] "C"  Receiver
 SG_ VCFRONT_HCMR_turnTemp m4 : 24|8@1- (1,67) [-60|194] "C"  Receiver
 SG_ VCFRONT_PDischargeControllerOutp m14 : 24|8@1+ (0.5,0) [0|100] "%"  Receiver
 SG_ VCFRONT_PSuctionControllerOutput m14 : 40|8@1+ (0.5,0) [0|100] "%"  Receiver
 SG_ VCFRONT_ambientColderThanBatt m16 : 8|1@1+ (1,0) [0|1] ""  Receiver
 SG_ VCFRONT_ambientSourcingAvailable m16 : 9|1@1+ (1,0) [0|1] ""  Receiver
 SG_ VCFRONT_ambientSourcingDisabled m14 : 38|1@1+ (1,0) [0|1] ""  Receiver
 SG_ VCFRONT_battDissipation m12 : 8|8@1+ (140,0) [0|35000] "W"  Receiver
 SG_ VCFRONT_battLoopWorthCooling m16 : 15|1@1+ (1,0) [0|1] ""  Receiver
 SG_ VCFRONT_battOverStagUpperLimit m16 : 6|1@1+ (1,0) [0|1] ""  Receiver
 SG_ VCFRONT_battUnderStagUpperLimit m16 : 7|1@1+ (1,0) [0|1] ""  Receiver
 SG_ VCFRONT_cabinHeatEnergyDuringDri m8 : 42|7@1+ (150,0) [0|19000] "Wh"  Receiver
 SG_ VCFRONT_calibratedPositionHCML m6 : 5|10@1+ (1,0) [0|1023] "Steps"  Receiver
 SG_ VCFRONT_calibratedPositionHCMR m6 : 16|10@1+ (1,0) [0|1023] "Steps"  Receiver
 SG_ VCFRONT_ccLeftExvCalibFailed m11 : 60|1@1+ (1,0) [0|1] ""  Receiver
 SG_ VCFRONT_ccLeftExvCalibOffset m11 : 40|8@1- (4,0) [-510|510] "ticks"  Receiver
 SG_ VCFRONT_ccLeftExvRange m7 : 41|9@1+ (3,0) [0|1500] "ticks"  Receiver
 SG_ VCFRONT_ccRightExvCalibFailed m11 : 61|1@1+ (1,0) [0|1] ""  Receiver
 SG_ VCFRONT_ccRightExvCalibOffset m11 : 48|8@1- (4,0) [-510|510] "ticks"  Receiver
 SG_ VCFRONT_ccRightExvRange m7 : 50|9@1+ (3,0) [0|1500] "ticks"  Receiver
 SG_ VCFRONT_chillerExvCalibFailed m11 : 56|1@1+ (1,0) [0|1] ""  Receiver
 SG_ VCFRONT_chillerExvCalibOffset m11 : 8|8@1- (4,0) [-510|510] "ticks"  Receiver
 SG_ VCFRONT_chillerExvRange m7 : 5|9@1+ (3,0) [0|1500] "ticks"  Receiver
 SG_ VCFRONT_chillerInletTempEstimate m13 : 27|8@1- (1,0) [-40|85] "C"  Receiver
 SG_ VCFRONT_chillerLiftDisabledLowPs m14 : 39|1@1+ (1,0) [0|1] ""  Receiver
 SG_ VCFRONT_chillerPassiveCoolPower m12 : 24|8@1- (60,7560) [0|15000] "W"  Receiver
 SG_ VCFRONT_compEnergyDuringDrive m8 : 35|7@1+ (150,0) [0|19000] "Wh"  Receiver
 SG_ VCFRONT_condenserPressureLimit m1 : 8|6@1+ (0.16,10) [10|20] "bar"  Receiver
 SG_ VCFRONT_coolantLevelVoltage m0 : 55|9@1+ (0.01,0) [0|5] "V"  Receiver
 SG_ VCFRONT_coolantValveAngleDrift m2 : 18|10@1+ (0.25,-127) [-127|127] "degrees"  Receiver
 SG_ VCFRONT_coolantValveCountRange m2 : 8|10@1+ (1,375) [375|1375] "ticks"  Receiver
 SG_ VCFRONT_coolantValveRadBypass m2 : 56|7@1+ (1,0) [0|100] "%"  Receiver
 SG_ VCFRONT_coolantValveRecalCount m2 : 28|16@1+ (1,0) [0|65535] ""  Receiver
 SG_ VCFRONT_coolantValveRecalReason m2 : 5|3@1+ (1,0) [0|6] ""  Receiver
 SG_ VCFRONT_coolantValveWindupEstL m2 : 44|6@1+ (2,0) [0|126] "ticks"  Receiver
 SG_ VCFRONT_coolantValveWindupEstR m2 : 50|6@1+ (2,0) [0|126] "ticks"  Receiver
 SG_ VCFRONT_currentPositionHCML m6 : 26|10@1+ (1,0) [0|1023] "Steps"  Receiver
 SG_ VCFRONT_currentPositionHCMR m6 : 36|10@1+ (1,0) [0|1023] "Steps"  Receiver
 SG_ VCFRONT_cycleModelConverged m10 : 61|1@1+ (1,0) [0|1] ""  Receiver
 SG_ VCFRONT_diDissipation m12 : 16|8@1+ (80,0) [0|20000] "W"  Receiver
 SG_ VCFRONT_dischargePressureTarget m14 : 8|7@1+ (0.25,0) [0|26] "bar"  Receiver
 SG_ VCFRONT_estCompPower m16 : 48|8@1+ (50,0) [0|12750] "W"  Receiver
 SG_ VCFRONT_estCompPressureInlet m16 : 24|8@1+ (0.05,0) [0|12.75] "bar"  Receiver
 SG_ VCFRONT_estCompPressureOutlet m16 : 32|8@1+ (0.1,0) [1|26.5] "bar"  Receiver
 SG_ VCFRONT_estCompRefrigMassflow m16 : 17|7@1+ (2,0) [0|254] "g/s"  Receiver
 SG_ VCFRONT_estCompTempOutlet m16 : 40|8@1+ (1.5,0) [0|190.5] "C"  Receiver
 SG_ VCFRONT_estCompressorRpm m10 : 48|6@1+ (400,0) [0|25200] "rpm"  Receiver
 SG_ VCFRONT_estPressureDisch m10 : 19|7@1+ (0.25,0) [0|31.75] "bar"  Receiver
 SG_ VCFRONT_estPressureLiq m10 : 5|7@1+ (0.25,0) [0|31.75] "bar"  Receiver
 SG_ VCFRONT_estPressureSuct m10 : 12|7@1+ (0.125,0) [0|11.5] "bar"  Receiver
 SG_ VCFRONT_estQLift m10 : 54|7@1+ (100,0) [0|12700] "W"  Receiver
 SG_ VCFRONT_estTempDisch m10 : 40|8@1- (0.8,68.8) [-34|170] "C"  Receiver
 SG_ VCFRONT_estTempLiq m10 : 26|8@1- (0.8,68.8) [-34|170] "C"  Receiver
 SG_ VCFRONT_estTempSuct m10 : 34|6@1- (1,2) [-30|33] "C"  Receiver
 SG_ VCFRONT_evapDisabledLowPsCutout m14 : 15|1@1+ (1,0) [0|1] ""  Receiver
 SG_ VCFRONT_evapExvCalibFailed m11 : 57|1@1+ (1,0) [0|1] ""  Receiver
 SG_ VCFRONT_evapExvCalibOffset m11 : 16|8@1- (4,0) [-510|510] "ticks"  Receiver
 SG_ VCFRONT_evapExvRange m7 : 14|9@1+ (3,0) [0|1500] "ticks"  Receiver
 SG_ VCFRONT_evapFdFrwrdTarget m9 : 28|7@1+ (80,0) [0|10100] "W"  Receiver
 SG_ VCFRONT_evapFdFrwrdTargetMinimum m9 : 49|7@1+ (80,0) [0|10000] "W"  Receiver
 SG_ VCFRONT_evapFdbk m9 : 35|7@1- (80,0) [-5000|5000] "W"  Receiver
 SG_ VCFRONT_exteriorQuietModeAllowed m9 : 6|1@1+ (1,0) [0|1] ""  Receiver
 SG_ VCFRONT_exteriorQuietModeEnabled m9 : 5|1@1+ (1,0) [0|1] ""  Receiver
 SG_ VCFRONT_fanControlFeedfwdActive m15 : 49|1@1+ (1,0) [0|1] ""  Receiver
 SG_ VCFRONT_fanControlRadCanCool m15 : 48|1@1+ (1,0) [0|1] ""  Receiver
 SG_ VCFRONT_fanControlRadiatorInletT m15 : 57|6@1- (1.8,36) [-20|90] "C"  Receiver
 SG_ VCFRONT_fanControlRadiatorUa m15 : 50|7@1+ (8,0) [0|1000] "W/C"  Receiver
 SG_ VCFRONT_fanDemandCondenser m1 : 14|7@1+ (1,0) [0|100] "%"  Receiver
 SG_ VCFRONT_fanDemandRadiator m1 : 21|7@1+ (1,0) [0|100] "%"  Receiver
 SG_ VCFRONT_feedBackDuctTempControll m15 : 32|8@1+ (1,-100) [-100|100] "-"  Receiver
 SG_ VCFRONT_feedBackEvapTempControll m15 : 24|7@1+ (0.01,-0.5) [-0.5|0.5] "-"  Receiver
 SG_ VCFRONT_feedFwdFanDemand m13 : 35|7@1+ (1,0) [0|100] "%"  Receiver
 SG_ VCFRONT_feedFwdMDotCabinCondense m15 : 16|8@1+ (0.005,0) [0|1] "-"  Receiver
 SG_ VCFRONT_feedFwdMDotEvaporator m15 : 8|8@1+ (0.005,0) [0|1] "-"  Receiver
 SG_ VCFRONT_feedFwdPumpDemand m13 : 42|7@1+ (1,0) [0|100] "%"  Receiver
 SG_ VCFRONT_feedfwdLoadCoolingDomina m9 : 59|1@1+ (1,0) [0|1] ""  Receiver
 SG_ VCFRONT_homelinkRegionCode m5 : 8|4@1+ (1,0) [0|9] ""  Receiver
 SG_ VCFRONT_hpAmbientSource m17 : 6|1@1+ (1,0) [0|1] ""  Receiver
 SG_ VCFRONT_hpAtSteadyState m16 : 63|1@1+ (1,0) [0|1] ""  Receiver
 SG_ VCFRONT_hpBattStagTarget m8 : 28|7@1+ (1,-40) [-40|80] "C"  Receiver
 SG_ VCFRONT_hpBatteryCool m17 : 19|1@1+ (1,0) [0|1] ""  Receiver
 SG_ VCFRONT_hpBatteryCoolCabinConden m17 : 20|1@1+ (1,0) [0|1] ""  Receiver
 SG_ VCFRONT_hpBatteryCoolCabinReheat m17 : 21|1@1+ (1,0) [0|1] ""  Receiver
 SG_ VCFRONT_hpBatteryCoolEvaporator m17 : 22|1@1+ (1,0) [0|1] ""  Receiver
 SG_ VCFRONT_hpBatteryHeatAmbientSour m17 : 17|1@1+ (1,0) [0|1] ""  Receiver
 SG_ VCFRONT_hpBatteryHeatCOP1 m17 : 18|1@1+ (1,0) [0|1] ""  Receiver
 SG_ VCFRONT_hpCOP m8 : 22|6@1+ (0.1,0) [0|6] "-"  Receiver
 SG_ VCFRONT_hpCabinCoolEvaporator m17 : 15|1@1+ (1,0) [0|1] ""  Receiver
 SG_ VCFRONT_hpCabinCoolEvaporatorReh m17 : 16|1@1+ (1,0) [0|1] ""  Receiver
 SG_ VCFRONT_hpCabinHeatAmbientSource m17 : 8|1@1+ (1,0) [0|1] ""  Receiver
 SG_ VCFRONT_hpCabinHeatBatteryCoolRe m17 : 14|1@1+ (1,0) [0|1] ""  Receiver
 SG_ VCFRONT_hpCabinHeatBatteryHeatRe m17 : 13|1@1+ (1,0) [0|1] ""  Receiver
 SG_ VCFRONT_hpCabinHeatBlend m17 : 11|1@1+ (1,0) [0|1] ""  Receiver
 SG_ VCFRONT_hpCabinHeatCOP1 m17 : 12|1@1+ (1,0) [0|1] ""  Receiver
 SG_ VCFRONT_hpCabinHeatReheatAmbient m17 : 10|1@1+ (1,0) [0|1] ""  Receiver
 SG_ VCFRONT_hpCabinHeatReheatScaveng m17 : 9|1@1+ (1,0) [0|1] ""  Receiver
 SG_ VCFRONT_hpCabinHeatScavengeOnly m17 : 7|1@1+ (1,0) [0|1] ""  Receiver
 SG_ VCFRONT_hpCompPowerIndex m16 : 56|7@1+ (1,0) [0|127] "-"  Receiver
 SG_ VCFRONT_hpForceScavenge m16 : 5|1@1+ (1,0) [0|1] ""  Receiver
 SG_ VCFRONT_hpGeneral m17 : 5|1@1+ (1,0) [0|1] ""  Receiver
 SG_ VCFRONT_hpMode m16 : 10|5@1+ (1,0) [0|19] ""  Receiver
 SG_ VCFRONT_hpPotentialLowRefrig m9 : 61|1@1+ (1,0) [0|1] ""  Receiver
 SG_ VCFRONT_hpRefrigerantPurgeState m9 : 62|2@1+ (1,0) [0|2] ""  Receiver
 SG_ VCFRONT_hpSubcoolTarget m8 : 12|5@1+ (1,0) [0|31] "C"  Receiver
 SG_ VCFRONT_lccExvCalibFailed m11 : 59|1@1+ (1,0) [0|1] ""  Receiver
 SG_ VCFRONT_lccExvCalibOffset m11 : 32|8@1- (4,0) [-510|510] "ticks"  Receiver
 SG_ VCFRONT_lccExvRange m7 : 32|9@1+ (3,0) [0|1500] "ticks"  Receiver
 SG_ VCFRONT_lccInletTempEstimate m13 : 19|8@1- (1,0) [-40|85] "C"  Receiver
 SG_ VCFRONT_lccPassiveHeatPower m12 : 32|8@1+ (60,0) [0|15000] "W"  Receiver
 SG_ VCFRONT_lowSideLiftEnergyDrive m8 : 49|7@1+ (150,0) [0|19000] "Wh"  Receiver
 SG_ VCFRONT_lowSideWattsLift m8 : 56|7@1+ (60,0) [0|7600] "W"  Receiver
 SG_ VCFRONT_maxAllowedEvapPowerInSer m12 : 40|8@1+ (40,0) [0|10000] "W"  Receiver
 SG_ VCFRONT_maxChillerCoolingPower m15 : 40|8@1+ (100,0) [0|20000] "W"  Receiver
 SG_ VCFRONT_maxCompressorRPMAllowed m14 : 56|7@1+ (90,0) [0|11430] "rpm"  Receiver
 SG_ VCFRONT_minAllowedChillerPowerIn m12 : 48|8@1+ (40,0) [0|10000] "W"  Receiver
 SG_ VCFRONT_minAllowedSuctionPressur m14 : 48|7@1+ (0.02,0) [0|2.5] "bar"  Receiver
 SG_ VCFRONT_minFlowPDCont m14 : 16|8@1+ (0.5,0) [0|100] "%"  Receiver
 SG_ VCFRONT_modeDesired m0 : 14|2@1+ (1,0) [0|3] ""  Receiver
 SG_ VCFRONT_modeTransitionID m0 : 8|6@1+ (1,0) [0|39] ""  Receiver
 SG_ VCFRONT_modelLoadCoolingDominant m9 : 60|1@1+ (1,0) [0|1] ""  Receiver
 SG_ VCFRONT_passiveCoolingState m9 : 56|2@1+ (1,0) [0|3] ""  Receiver
 SG_ VCFRONT_ptLoopWorthCooling m16 : 16|1@1+ (1,0) [0|1] ""  Receiver
 SG_ VCFRONT_pumpBatteryFETTemp m1 : 36|8@1+ (1,-40) [-40|150] "C"  Receiver
 SG_ VCFRONT_pumpPowertrainFETTemp m1 : 44|8@1+ (1,-40) [-40|150] "C"  Receiver
 SG_ VCFRONT_radActiveRejectEstimate m13 : 49|15@1+ (1,0) [0|30000] "W"  Receiver
 SG_ VCFRONT_radPassiveRejectEstimate m13 : 5|14@1+ (1,0) [0|15000] "W"  Receiver
 SG_ VCFRONT_radiatorFanFETTemp m1 : 52|8@1+ (1,-40) [-40|150] "C"  Receiver
 SG_ VCFRONT_radiatorFanRunReason m1 : 60|4@1+ (1,0) [0|8] ""  Receiver
 SG_ VCFRONT_recircExvCalibFailed m11 : 58|1@1+ (1,0) [0|1] ""  Receiver
 SG_ VCFRONT_recircExvCalibOffset m11 : 24|8@1- (4,0) [-510|510] "ticks"  Receiver
 SG_ VCFRONT_recircExvRange m7 : 23|9@1+ (3,0) [0|1500] "ticks"  Receiver
 SG_ VCFRONT_subcoolActual m8 : 5|7@1- (0.4,15.2) [-10|40] "C"  Receiver
 SG_ VCFRONT_suctionPressureTarget m14 : 32|6@1+ (0.15,0) [0|8] "bar"  Receiver
 SG_ VCFRONT_targetBatActiveCool m0 : 32|7@1+ (1,0) [0|100] "C"  Receiver
 SG_ VCFRONT_targetBatActiveHeat m0 : 48|7@1+ (1,-40) [-40|60] "C"  Receiver
 SG_ VCFRONT_targetBatPassive m0 : 40|7@1+ (1,-20) [-20|80] "C"  Receiver
 SG_ VCFRONT_targetPTActiveCool m0 : 16|8@1+ (1,-40) [-40|120] "C"  Receiver
 SG_ VCFRONT_targetPTPassive m0 : 24|8@1+ (1,-40) [-40|120] "C"  Receiver
 SG_ VCFRONT_tempRefrigSuction m1 : 28|8@1+ (0.5,-40) [-40|85] "C"  Receiver
 SG_ VCFRONT_totalLoadCoolingDominant m9 : 58|1@1+ (1,0) [0|1] ""  Receiver
 SG_ VCFRONT_wiperCycles m18 : 48|16@1+ (100,0) [0|6553500] "Cycles"  Receiver

BO_ 899 VCRIGHT_thsStatus: 8 VEH
 SG_ VCRIGHT_estimatedThsSolarLoad : 53|10@1+ (1,0) [0|0] "W/m2" Vector__XXX
 SG_ VCRIGHT_thsActive : 0|1@1+ (1,0) [0|0] "" Vector__XXX
 SG_ VCRIGHT_thsHumidity : 17|8@1+ (1,0) [0|0] "%" Vector__XXX
 SG_ VCRIGHT_thsSolarLoadInfrared : 33|10@1+ (1,0) [0|0] "W/m2" Vector__XXX
 SG_ VCRIGHT_thsSolarLoadVisible : 43|10@1+ (1,0) [0|0] "W/m2" Vector__XXX
 SG_ VCRIGHT_thsTemperature : 1|8@1- (1,-40) [0|0] "degC" Vector__XXX

BO_ 900 PMS_alertMatrix1: 8 VEH
 SG_ PMS_w001_absoluteTorque : 0|1@1+ (1,0) [0|0] "" Vector__XXX
 SG_ PMS_w002_accumulatedTorque : 1|1@1+ (1,0) [0|0] "" Vector__XXX
 SG_ PMS_w003_torqueReversal : 2|1@1+ (1,0) [0|0] "" Vector__XXX
 SG_ PMS_w004_regenTorque : 3|1@1+ (1,0) [0|0] "" Vector__XXX
 SG_ PMS_w005_torqueInNeutral : 4|1@1+ (1,0) [0|0] "" Vector__XXX
 SG_ PMS_w006_inconsistentDIGear : 5|1@1+ (1,0) [0|0] "" Vector__XXX
 SG_ PMS_w007_watchdogReset : 6|1@1+ (1,0) [0|0] "" Vector__XXX
 SG_ PMS_w008_memoryError : 7|1@1+ (1,0) [0|0] "" Vector__XXX
 SG_ PMS_w009_espMIA : 8|1@1+ (1,0) [0|0] "" Vector__XXX
 SG_ PMS_w010_diMIA : 9|1@1+ (1,0) [0|0] "" Vector__XXX
 SG_ PMS_w011_phaseCurrentIrrational : 10|1@1+ (1,0) [0|0] "" Vector__XXX
 SG_ PMS_w012_canDataBusA : 11|1@1+ (1,0) [0|0] "" Vector__XXX
 SG_ PMS_w013_canHardwareBusA : 12|1@1+ (1,0) [0|0] "" Vector__XXX
 SG_ PMS_w018_encoderIrrational : 17|1@1+ (1,0) [0|0] "" Vector__XXX
 SG_ PMS_w019_statorTempIrrational : 18|1@1+ (1,0) [0|0] "" Vector__XXX
 SG_ PMS_w026_diHeartBeatMIA : 25|1@1+ (1,0) [0|0] "" Vector__XXX
 SG_ PMS_w027_torqueOutOfMap : 26|1@1+ (1,0) [0|0] "" Vector__XXX
 SG_ PMS_w028_torqueCmdError : 27|1@1+ (1,0) [0|0] "" Vector__XXX
 SG_ PMS_w031_highStackUsage : 30|1@1+ (1,0) [0|0] "" Vector__XXX
 SG_ PMS_w032_registerConfigError : 31|1@1+ (1,0) [0|0] "" Vector__XXX
 SG_ PMS_w033_selfTest : 32|1@1+ (1,0) [0|0] "" Vector__XXX
 SG_ PMS_w034_trqCrossCheck : 33|1@1+ (1,0) [0|0] "" Vector__XXX
 SG_ PMS_w038_inconsistentTorqueSign : 37|1@1+ (1,0) [0|0] "" Vector__XXX
 SG_ PMS_w039_disMIA : 38|1@1+ (1,0) [0|0] "" Vector__XXX
 SG_ PMS_w040_pmMIA : 39|1@1+ (1,0) [0|0] "" Vector__XXX
 SG_ PMS_w042_gtwMIA : 41|1@1+ (1,0) [0|0] "" Vector__XXX
 SG_ PMS_w043_inconsistentConfig : 42|1@1+ (1,0) [0|0] "" Vector__XXX
 SG_ PMS_w045_motorMovementDetected : 44|1@1+ (1,0) [0|0] "" Vector__XXX
 SG_ PMS_w053_vcfrontMIA : 52|1@1+ (1,0) [0|0] "" Vector__XXX
 SG_ PMS_w054_uiMIA : 53|1@1+ (1,0) [0|0] "" Vector__XXX
 SG_ PMS_w055_resolver : 54|1@1+ (1,0) [0|0] "" Vector__XXX
 SG_ PMS_w056_canHardwareBusB : 55|1@1+ (1,0) [0|0] "" Vector__XXX
 SG_ PMS_w057_canDataBusB : 56|1@1+ (1,0) [0|0] "" Vector__XXX
 SG_ PMS_w061_DIPMVersionMismatch : 60|1@1+ (1,0) [0|0] "" Vector__XXX
 SG_ PMS_w063_debugAlert : 62|1@1+ (1,0) [0|0] "" Vector__XXX
 SG_ PMS_w064_torqueIntervention : 63|1@1+ (1,0) [0|0] "" Vector__XXX

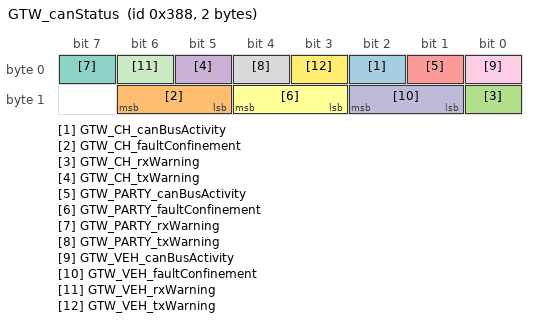
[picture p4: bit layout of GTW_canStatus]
BO_ 904 GTW_canStatus: 2 VEH
 SG_ GTW_CH_canBusActivity : 2|1@1+ (1,0) [0|0] "" Vector__XXX
 SG_ GTW_CH_faultConfinement : 13|2@1+ (1,0) [0|0] "" Vector__XXX
 SG_ GTW_CH_rxWarning : 8|1@1+ (1,0) [0|0] "" Vector__XXX
 SG_ GTW_CH_txWarning : 5|1@1+ (1,0) [0|0] "" Vector__XXX
 SG_ GTW_PARTY_canBusActivity : 1|1@1+ (1,0) [0|0] "" Vector__XXX
 SG_ GTW_PARTY_faultConfinement : 11|2@1+ (1,0) [0|0] "" Vector__XXX
 SG_ GTW_PARTY_rxWarning : 7|1@1+ (1,0) [0|0] "" Vector__XXX
 SG_ GTW_PARTY_txWarning : 4|1@1+ (1,0) [0|0] "" Vector__XXX
 SG_ GTW_VEH_canBusActivity : 0|1@1+ (1,0) [0|0] "" Vector__XXX
 SG_ GTW_VEH_faultConfinement : 9|2@1+ (1,0) [0|0] "" Vector__XXX
 SG_ GTW_VEH_rxWarning : 6|1@1+ (1,0) [0|0] "" Vector__XXX
 SG_ GTW_VEH_txWarning : 3|1@1+ (1,0) [0|0] "" Vector__XXX

BO_ 905 DAS_status2: 8 CH
 SG_ DAS_ACC_report : 26|5@1+ (1,0) [0|0] "" Vector__XXX
 SG_ DAS_accSpeedLimit : 0|10@1+ (0.2,0) [0|0] "mph" Vector__XXX
 SG_ DAS_activationFailureStatus : 14|2@1+ (1,0) [0|0] "" Vector__XXX
 SG_ DAS_driverInteractionLevel : 38|2@1+ (1,0) [0|0] "" Vector__XXX
 SG_ DAS_longCollisionWarning : 48|4@1+ (1,0) [0|0] "" Vector__XXX
 SG_ DAS_lssState : 31|3@1+ (1,0) [0|0] "" Vector__XXX
 SG_ DAS_pmmCameraFaultReason : 24|2@1+ (1,0) [0|0] "" Vector__XXX
 SG_ DAS_pmmLoggingRequest : 13|1@1+ (1,0) [0|0] "" Vector__XXX
 SG_ DAS_pmmObstacleSeverity : 10|3@1+ (1,0) [0|0] "" Vector__XXX
 SG_ DAS_pmmRadarFaultReason : 19|2@1+ (1,0) [0|0] "" Vector__XXX
 SG_ DAS_pmmSysFaultReason : 21|3@1+ (1,0) [0|0] "" Vector__XXX
 SG_ DAS_pmmUltrasonicsFaultReason : 16|3@1+ (1,0) [0|0] "" Vector__XXX
 SG_ DAS_ppOffsetDesiredRamp : 40|8@1+ (0.01,-1.28) [0|0] "m" Vector__XXX
 SG_ DAS_radarTelemetry : 34|2@1+ (1,0) [0|0] "" Vector__XXX
 SG_ DAS_robState : 36|2@1+ (1,0) [0|0] "" Vector__XXX
 SG_ DAS_status2Checksum : 56|8@1+ (1,0) [0|0] "" Vector__XXX
 SG_ DAS_status2Counter : 52|4@1+ (1,0) [0|0] "" Vector__XXX

BO_ 909 TAS_warningMatrix3: 8 VEH
 SG_ TAS_w129_openCircuitFL : 0|1@1+ (1,0) [0|0] "" Vector__XXX
 SG_ TAS_w130_openCircuitFR : 1|1@1+ (1,0) [0|0] "" Vector__XXX
 SG_ TAS_w131_openCircuitRL : 2|1@1+ (1,0) [0|0] "" Vector__XXX
 SG_ TAS_w132_openCircuitRR : 3|1@1+ (1,0) [0|0] "" Vector__XXX
 SG_ TAS_w133_openCircuitReservoir : 4|1@1+ (1,0) [0|0] "" Vector__XXX
 SG_ TAS_w134_openCircuitExhaust : 5|1@1+ (1,0) [0|0] "" Vector__XXX
 SG_ TAS_w135_openCircuitBoost : 6|1@1+ (1,0) [0|0] "" Vector__XXX
 SG_ TAS_w136_openCircuitCompressor : 7|1@1+ (1,0) [0|0] "" Vector__XXX
 SG_ TAS_w137_shortCircuitFL : 8|1@1+ (1,0) [0|0] "" Vector__XXX
 SG_ TAS_w138_shortCircuitFR : 9|1@1+ (1,0) [0|0] "" Vector__XXX
 SG_ TAS_w139_shortCircuitRL : 10|1@1+ (1,0) [0|0] "" Vector__XXX
 SG_ TAS_w140_shortCircuitRR : 11|1@1+ (1,0) [0|0] "" Vector__XXX
 SG_ TAS_w141_shortCircuitReservoir : 12|1@1+ (1,0) [0|0] "" Vector__XXX
 SG_ TAS_w142_shortCircuitExhaust : 13|1@1+ (1,0) [0|0] "" Vector__XXX
 SG_ TAS_w143_shortCircuitBoost : 14|1@1+ (1,0) [0|0] "" Vector__XXX
 SG_ TAS_w144_shortCircuitCompressor : 15|1@1+ (1,0) [0|0] "" Vector__XXX
 SG_ TAS_w145_boardFaultFL : 16|1@1+ (1,0) [0|0] "" Vector__XXX
 SG_ TAS_w146_boardFaultFR : 17|1@1+ (1,0) [0|0] "" Vector__XXX
 SG_ TAS_w147_boardFaultRL : 18|1@1+ (1,0) [0|0] "" Vector__XXX
 SG_ TAS_w148_boardFaultRR : 19|1@1+ (1,0) [0|0] "" Vector__XXX
 SG_ TAS_w149_boardFaultReservoir : 20|1@1+ (1,0) [0|0] "" Vector__XXX
 SG_ TAS_w150_boardFaultExhaust : 21|1@1+ (1,0) [0|0] "" Vector__XXX
 SG_ TAS_w151_boardFaultBoost : 22|1@1+ (1,0) [0|0] "" Vector__XXX
 SG_ TAS_w152_boardFaultCompressor : 23|1@1+ (1,0) [0|0] "" Vector__XXX
 SG_ TAS_w153_otherCircuitFL : 24|1@1+ (1,0) [0|0] "" Vector__XXX
 SG_ TAS_w154_otherCircuitFR : 25|1@1+ (1,0) [0|0] "" Vector__XXX
 SG_ TAS_w155_otherCircuitRL : 26|1@1+ (1,0) [0|0] "" Vector__XXX
 SG_ TAS_w156_otherCircuitRR : 27|1@1+ (1,0) [0|0] "" Vector__XXX
 SG_ TAS_w157_otherCircuitReservoir : 28|1@1+ (1,0) [0|0] "" Vector__XXX
 SG_ TAS_w158_otherCircuitExhaust : 29|1@1+ (1,0) [0|0] "" Vector__XXX
 SG_ TAS_w159_otherCircuitBoost : 30|1@1+ (1,0) [0|0] "" Vector__XXX
 SG_ TAS_w160_otherCircuitCompressor : 31|1@1+ (1,0) [0|0] "" Vector__XXX
 SG_ TAS_w161_valveBlockOpenGND : 32|1@1+ (1,0) [0|0] "" Vector__XXX
 SG_ TAS_w162_compressorValveOpenGND : 33|1@1+ (1,0) [0|0] "" Vector__XXX
 SG_ TAS_w163_reservoirFillDisabled : 34|1@1+ (1,0) [0|0] "" Vector__XXX
 SG_ TAS_w164_calibrationVersion : 35|1@1+ (1,0) [0|0] "" Vector__XXX

BO_ 913 EPAS3S_alertMatrix: 8 CH
 SG_ EPAS3S_matrixIndex M : 0|4@1+ (1,0) [0|0] "" Vector__XXX
 SG_ EPAS3S_a001_sent1Mia m0 : 4|1@1+ (1,0) [0|0] "" Vector__XXX
 SG_ EPAS3S_a002_sent1Error m0 : 5|1@1+ (1,0) [0|0] "" Vector__XXX
 SG_ EPAS3S_a003_trqSens1Supply m0 : 6|1@1+ (1,0) [0|0] "" Vector__XXX
 SG_ EPAS3S_a004_trqSens1Eeprom m0 : 7|1@1+ (1,0) [0|0] "" Vector__XXX
 SG_ EPAS3S_a005_sent2Mia m0 : 8|1@1+ (1,0) [0|0] "" Vector__XXX
 SG_ EPAS3S_a006_sent2Error m0 : 9|1@1+ (1,0) [0|0] "" Vector__XXX
 SG_ EPAS3S_a007_trqSens2Supply m0 : 10|1@1+ (1,0) [0|0] "" Vector__XXX
 SG_ EPAS3S_a008_trqSens2Eeprom m0 : 11|1@1+ (1,0) [0|0] "" Vector__XXX
 SG_ EPAS3S_a009_sentDiff m0 : 12|1@1+ (1,0) [0|0] "" Vector__XXX
 SG_ EPAS3S_a010_trqSensCalError m0 : 13|1@1+ (1,0) [0|0] "" Vector__XXX
 SG_ EPAS3S_a011_currentSensError m0 : 14|1@1+ (1,0) [0|0] "" Vector__XXX
 SG_ EPAS3S_a012_currentSensCalError m0 : 15|1@1+ (1,0) [0|0] "" Vector__XXX
 SG_ EPAS3S_a013_gateDriveError m0 : 16|1@1+ (1,0) [0|0] "" Vector__XXX
 SG_ EPAS3S_a014_gateDriveTxError m0 : 17|1@1+ (1,0) [0|0] "" Vector__XXX
 SG_ EPAS3S_a015_gateDriveEeprom m0 : 18|1@1+ (1,0) [0|0] "" Vector__XXX
 SG_ EPAS3S_a016_phaseUhighUv m0 : 19|1@1+ (1,0) [0|0] "" Vector__XXX
 SG_ EPAS3S_a017_phaseUlowUv m0 : 20|1@1+ (1,0) [0|0] "" Vector__XXX
 SG_ EPAS3S_a018_phaseVhighUv m0 : 21|1@1+ (1,0) [0|0] "" Vector__XXX
 SG_ EPAS3S_a019_phaseVlowUv m0 : 22|1@1+ (1,0) [0|0] "" Vector__XXX
 SG_ EPAS3S_a020_phaseWhighUv m0 : 23|1@1+ (1,0) [0|0] "" Vector__XXX
 SG_ EPAS3S_a021_phaseWlowUv m0 : 24|1@1+ (1,0) [0|0] "" Vector__XXX
 SG_ EPAS3S_a022_phaseUhighOv m0 : 25|1@1+ (1,0) [0|0] "" Vector__XXX
 SG_ EPAS3S_a023_phaseUlowOv m0 : 26|1@1+ (1,0) [0|0] "" Vector__XXX
 SG_ EPAS3S_a024_phaseVhighOv m0 : 27|1@1+ (1,0) [0|0] "" Vector__XXX
 SG_ EPAS3S_a025_phaseVlowOv m0 : 28|1@1+ (1,0) [0|0] "" Vector__XXX
 SG_ EPAS3S_a026_phaseWhighOv m0 : 29|1@1+ (1,0) [0|0] "" Vector__XXX
 SG_ EPAS3S_a027_phaseWlowOv m0 : 30|1@1+ (1,0) [0|0] "" Vector__XXX
 SG_ EPAS3S_a028_phaseUbootUv m0 : 31|1@1+ (1,0) [0|0] "" Vector__XXX
 SG_ EPAS3S_a029_phaseVbootUv m0 : 32|1@1+ (1,0) [0|0] "" Vector__XXX
 SG_ EPAS3S_a030_phaseWbootUv m0 : 33|1@1+ (1,0) [0|0] "" Vector__XXX
 SG_ EPAS3S_a031_phaseFeedbackError m0 : 34|1@1+ (1,0) [0|0] "" Vector__XXX
 SG_ EPAS3S_a032_vRegOutputUv m0 : 35|1@1+ (1,0) [0|0] "" Vector__XXX
 SG_ EPAS3S_a033_vRegOutputOv m0 : 36|1@1+ (1,0) [0|0] "" Vector__XXX
 SG_ EPAS3S_a034_vRegError m0 : 37|1@1+ (1,0) [0|0] "" Vector__XXX
 SG_ EPAS3S_a035_vbbSupplyUv m0 : 38|1@1+ (1,0) [0|0] "" Vector__XXX
 SG_ EPAS3S_a036_vbbSupplyOv m0 : 39|1@1+ (1,0) [0|0] "" Vector__XXX
 SG_ EPAS3S_a037_motPos1ParityError m0 : 40|1@1+ (1,0) [0|0] "" Vector__XXX
 SG_ EPAS3S_a038_motPos1Uv m0 : 41|1@1+ (1,0) [0|0] "" Vector__XXX
 SG_ EPAS3S_a039_motPos1MagnetMia m0 : 42|1@1+ (1,0) [0|0] "" Vector__XXX
 SG_ EPAS3S_a040_motPos1LogicError m0 : 43|1@1+ (1,0) [0|0] "" Vector__XXX
 SG_ EPAS3S_a041_motPos1tempError m0 : 44|1@1+ (1,0) [0|0] "" Vector__XXX
 SG_ EPAS3S_a042_motPos2ParityError m0 : 45|1@1+ (1,0) [0|0] "" Vector__XXX
 SG_ EPAS3S_a043_motPos2Uv m0 : 46|1@1+ (1,0) [0|0] "" Vector__XXX
 SG_ EPAS3S_a044_motPos2MagnetMia m0 : 47|1@1+ (1,0) [0|0] "" Vector__XXX
 SG_ EPAS3S_a045_motPos2LogicError m0 : 48|1@1+ (1,0) [0|0] "" Vector__XXX
 SG_ EPAS3S_a046_motPos2tempError m0 : 49|1@1+ (1,0) [0|0] "" Vector__XXX
 SG_ EPAS3S_a047_motPosCorrError m0 : 50|1@1+ (1,0) [0|0] "" Vector__XXX
 SG_ EPAS3S_a048_motPosCalError m0 : 51|1@1+ (1,0) [0|0] "" Vector__XXX
 SG_ EPAS3S_a049_piCtrlError m0 : 52|1@1+ (1,0) [0|0] "" Vector__XXX
 SG_ EPAS3S_a050_mcuSmuError m0 : 53|1@1+ (1,0) [0|0] "" Vector__XXX
 SG_ EPAS3S_a051_mcuSupError m0 : 54|1@1+ (1,0) [0|0] "" Vector__XXX
 SG_ EPAS3S_a052_intWatchdogError m0 : 55|1@1+ (1,0) [0|0] "" Vector__XXX
 SG_ EPAS3S_a053_extWatchdogError m0 : 56|1@1+ (1,0) [0|0] "" Vector__XXX
 SG_ EPAS3S_a054_memoryProtectError m0 : 57|1@1+ (1,0) [0|0] "" Vector__XXX
 SG_ EPAS3S_a055_floatPointError m0 : 58|1@1+ (1,0) [0|0] "" Vector__XXX
 SG_ EPAS3S_a056_battUv m0 : 59|1@1+ (1,0) [0|0] "" Vector__XXX
 SG_ EPAS3S_a057_battUvReduced m0 : 60|1@1+ (1,0) [0|0] "" Vector__XXX
 SG_ EPAS3S_a058_battOv m0 : 61|1@1+ (1,0) [0|0] "" Vector__XXX
 SG_ EPAS3S_a059_battOvReduced m0 : 62|1@1+ (1,0) [0|0] "" Vector__XXX
 SG_ EPAS3S_a060_battBridgeDiff m0 : 63|1@1+ (1,0) [0|0] "" Vector__XXX
 SG_ EPAS3S_a061_bridgeUv m1 : 4|1@1+ (1,0) [0|0] "" Vector__XXX
 SG_ EPAS3S_a062_assistCorrError m1 : 5|1@1+ (1,0) [0|0] "" Vector__XXX
 SG_ EPAS3S_a063_dampCorrError m1 : 6|1@1+ (1,0) [0|0] "" Vector__XXX
 SG_ EPAS3S_a064_phaseCompCorrError m1 : 7|1@1+ (1,0) [0|0] "" Vector__XXX
 SG_ EPAS3S_a065_trqTarCorrError m1 : 8|1@1+ (1,0) [0|0] "" Vector__XXX
 SG_ EPAS3S_a066_returnCorrError m1 : 9|1@1+ (1,0) [0|0] "" Vector__XXX
 SG_ EPAS3S_a067_yawDampCorrError m1 : 10|1@1+ (1,0) [0|0] "" Vector__XXX
 SG_ EPAS3S_a068_hystCorrError m1 : 11|1@1+ (1,0) [0|0] "" Vector__XXX
 SG_ EPAS3S_a069_eacCorrError m1 : 12|1@1+ (1,0) [0|0] "" Vector__XXX
 SG_ EPAS3S_a070_hodCorrError m1 : 13|1@1+ (1,0) [0|0] "" Vector__XXX
 SG_ EPAS3S_a071_vehSpdCorrError m1 : 14|1@1+ (1,0) [0|0] "" Vector__XXX
 SG_ EPAS3S_a072_motFeedFwdError m1 : 15|1@1+ (1,0) [0|0] "" Vector__XXX
 SG_ EPAS3S_a073_motParEstError m1 : 16|1@1+ (1,0) [0|0] "" Vector__XXX
 SG_ EPAS3S_a074_overHeatProtect m1 : 17|1@1+ (1,0) [0|0] "" Vector__XXX
 SG_ EPAS3S_a075_fspPwrCut m1 : 18|1@1+ (1,0) [0|0] "" Vector__XXX
 SG_ EPAS3S_a076_tempSensOutofRange m1 : 19|1@1+ (1,0) [0|0] "" Vector__XXX
 SG_ EPAS3S_a077_highSideFetError m1 : 20|1@1+ (1,0) [0|0] "" Vector__XXX
 SG_ EPAS3S_a078_phaseDisconnectError m1 : 21|1@1+ (1,0) [0|0] "" Vector__XXX
 SG_ EPAS3S_a079_backupCurrentPlaus m1 : 22|1@1+ (1,0) [0|0] "" Vector__XXX
 SG_ EPAS3S_a080_ecuInitArbError m1 : 23|1@1+ (1,0) [0|0] "" Vector__XXX
 SG_ EPAS3S_a081_coggCompError m1 : 24|1@1+ (1,0) [0|0] "" Vector__XXX
 SG_ EPAS3S_a082_polarityCalError m1 : 25|1@1+ (1,0) [0|0] "" Vector__XXX
 SG_ EPAS3S_a083_crcMismatch m1 : 26|1@1+ (1,0) [0|0] "" Vector__XXX
 SG_ EPAS3S_a084_eacCancelled m1 : 27|1@1+ (1,0) [0|0] "" Vector__XXX
 SG_ EPAS3S_a085_canBusOff m1 : 28|1@1+ (1,0) [0|0] "" Vector__XXX
 SG_ EPAS3S_a086_dasMia m1 : 29|1@1+ (1,0) [0|0] "" Vector__XXX
 SG_ EPAS3S_a087_dasCntError m1 : 30|1@1+ (1,0) [0|0] "" Vector__XXX
 SG_ EPAS3S_a088_dasCsError m1 : 31|1@1+ (1,0) [0|0] "" Vector__XXX
 SG_ EPAS3S_a089_espWsMia m1 : 32|1@1+ (1,0) [0|0] "" Vector__XXX
 SG_ EPAS3S_a090_espWsCntError m1 : 33|1@1+ (1,0) [0|0] "" Vector__XXX
 SG_ EPAS3S_a091_espWsCsError m1 : 34|1@1+ (1,0) [0|0] "" Vector__XXX
 SG_ EPAS3S_a092_espWrMia m1 : 35|1@1+ (1,0) [0|0] "" Vector__XXX
 SG_ EPAS3S_a093_espWrCntError m1 : 36|1@1+ (1,0) [0|0] "" Vector__XXX
 SG_ EPAS3S_a094_espWrCsError m1 : 37|1@1+ (1,0) [0|0] "" Vector__XXX
 SG_ EPAS3S_a095_espWsStatus m1 : 38|1@1+ (1,0) [0|0] "" Vector__XXX
 SG_ EPAS3S_a096_rcmMia m1 : 39|1@1+ (1,0) [0|0] "" Vector__XXX
 SG_ EPAS3S_a097_rcmCntError m1 : 40|1@1+ (1,0) [0|0] "" Vector__XXX
 SG_ EPAS3S_a098_rcmCsError m1 : 41|1@1+ (1,0) [0|0] "" Vector__XXX
 SG_ EPAS3S_a099_yawRateStatus m1 : 42|1@1+ (1,0) [0|0] "" Vector__XXX
 SG_ EPAS3S_a100_diMia m1 : 43|1@1+ (1,0) [0|0] "" Vector__XXX
 SG_ EPAS3S_a101_diCntError m1 : 44|1@1+ (1,0) [0|0] "" Vector__XXX
 SG_ EPAS3S_a102_diCsError m1 : 45|1@1+ (1,0) [0|0] "" Vector__XXX
 SG_ EPAS3S_a103_vcFrontMia m1 : 46|1@1+ (1,0) [0|0] "" Vector__XXX
 SG_ EPAS3S_a104_vcFrontCntError m1 : 47|1@1+ (1,0) [0|0] "" Vector__XXX
 SG_ EPAS3S_a105_vcFrontCsError m1 : 48|1@1+ (1,0) [0|0] "" Vector__XXX
 SG_ EPAS3S_a106_vcFrontTempMia m1 : 49|1@1+ (1,0) [0|0] "" Vector__XXX
 SG_ EPAS3S_a107_uiTuneReqMia m1 : 50|1@1+ (1,0) [0|0] "" Vector__XXX
 SG_ EPAS3S_a108_uiTuneReqCntError m1 : 51|1@1+ (1,0) [0|0] "" Vector__XXX
 SG_ EPAS3S_a109_uiTuneReqCsError m1 : 52|1@1+ (1,0) [0|0] "" Vector__XXX
 SG_ EPAS3S_a110_sasMia m1 : 53|1@1+ (1,0) [0|0] "" Vector__XXX
 SG_ EPAS3S_a111_sasCntError m1 : 54|1@1+ (1,0) [0|0] "" Vector__XXX
 SG_ EPAS3S_a112_sasCsError m1 : 55|1@1+ (1,0) [0|0] "" Vector__XXX
 SG_ EPAS3S_a113_sasStatusError m1 : 56|1@1+ (1,0) [0|0] "" Vector__XXX
 SG_ EPAS3S_a114_gtwConfigMia m1 : 57|1@1+ (1,0) [0|0] "" Vector__XXX
 SG_ EPAS3S_a115_ecuStatMia m1 : 58|1@1+ (1,0) [0|0] "" Vector__XXX
 SG_ EPAS3S_a116_ecuStatCntError m1 : 59|1@1+ (1,0) [0|0] "" Vector__XXX
 SG_ EPAS3S_a117_ecuStatCrcError m1 : 60|1@1+ (1,0) [0|0] "" Vector__XXX
 SG_ EPAS3S_a118_privateBusOff m1 : 61|1@1+ (1,0) [0|0] "" Vector__XXX
 SG_ EPAS3S_a119_pvtEcuStatMia m1 : 62|1@1+ (1,0) [0|0] "" Vector__XXX
 SG_ EPAS3S_a120_pvtEcuStatCntError m1 : 63|1@1+ (1,0) [0|0] "" Vector__XXX
 SG_ EPAS3S_a121_pvtEcuStatCrcError m2 : 4|1@1+ (1,0) [0|0] "" Vector__XXX
 SG_ EPAS3S_a122_olpActive m2 : 5|1@1+ (1,0) [0|0] "" Vector__XXX
 SG_ EPAS3S_a123_combEcu2StatFail m2 : 6|1@1+ (1,0) [0|0] "" Vector__XXX
 SG_ EPAS3S_a124_tempSensStuckInRange m2 : 7|1@1+ (1,0) [0|0] "" Vector__XXX
 SG_ EPAS3S_a125_trqSensTrimOutRange m2 : 8|1@1+ (1,0) [0|0] "" Vector__XXX
 SG_ EPAS3S_a126_apsMia m2 : 9|1@1+ (1,0) [0|0] "" Vector__XXX
 SG_ EPAS3S_a127_apsCntError m2 : 10|1@1+ (1,0) [0|0] "" Vector__XXX
 SG_ EPAS3S_a128_apsCsError m2 : 11|1@1+ (1,0) [0|0] "" Vector__XXX
 SG_ EPAS3S_a129_combEcu1StatFail m2 : 12|1@1+ (1,0) [0|0] "" Vector__XXX
 SG_ EPAS3S_a130_sasOffsetNotCal m2 : 13|1@1+ (1,0) [0|0] "" Vector__XXX

BO_ 914 ID392BMS_packConfig: 8 VehicleBus
 SG_ BMS_packConfigMultiplexer M : 0|8@1+ (1,0) [0|1] ""   X
 SG_ BMS_moduleType m1 : 8|3@1+ (1,0) [0|4] ""   X
 SG_ BMS_packMass m1 : 16|8@1+ (1,300) [342|469] "kg"   X
 SG_ BMS_reservedConfig_0 m0 : 8|5@1+ (1,0) [0|31] ""   X
 SG_ BMS_platformMaxBusVoltage m1 : 24|10@1+ (0.1,375) [0|0] "V"   X

BO_ 915 ID393VCRIGHT_epbmDebug: 8 VEH
 SG_ VCRIGHT_epbmDebugIndex M : 0|1@1+ (1,0) [0|1] ""  Receiver
 SG_ VCRIGHT_cdpEnumDummy m1 : 24|2@1+ (1,0) [0|2] ""  Receiver
 SG_ VCRIGHT_epbFaultStatus m0 : 58|2@1+ (1,0) [0|3] ""  Receiver
 SG_ VCRIGHT_epbMotorCurrent m0 : 5|11@1+ (0.01,0) [0|20.47] "A"  Receiver
 SG_ VCRIGHT_epbSummonState m0 : 45|3@1+ (1,0) [0|6] ""  Receiver
 SG_ VCRIGHT_epbUnitStatus m0 : 51|5@1+ (1,0) [0|22] ""  Receiver
 SG_ VCRIGHT_epbmApplyVoltage m0 : 16|11@1+ (0.01,0) [0|20.47] "A"  Receiver
 SG_ VCRIGHT_epbmCaliperState m0 : 1|3@1+ (1,0) [0|6] ""  Receiver
 SG_ VCRIGHT_epbmDynApplyingAllowed m1 : 9|1@1+ (1,0) [0|1] ""  Receiver
 SG_ VCRIGHT_epbmDynamicAllowed m1 : 2|1@1+ (1,0) [0|1] ""  Receiver
 SG_ VCRIGHT_epbmFaultAllowed m1 : 11|1@1+ (1,0) [0|1] ""  Receiver
 SG_ VCRIGHT_epbmFaultStatus m0 : 56|2@1+ (1,0) [0|3] "" Vector__XXX
 SG_ VCRIGHT_epbmMotorEnabled m0 : 4|1@1+ (1,0) [0|1] ""  Receiver
 SG_ VCRIGHT_epbmOpenAllowed m1 : 1|1@1+ (1,0) [0|1] ""  Receiver
 SG_ VCRIGHT_epbmParkAllowed m1 : 3|1@1+ (1,0) [0|1] ""  Receiver
 SG_ VCRIGHT_epbmParkingAllowed m1 : 8|1@1+ (1,0) [0|1] ""  Receiver
 SG_ VCRIGHT_epbmReleaseVoltage m0 : 27|11@1+ (0.01,0) [0|20.47] "A"  Receiver
 SG_ VCRIGHT_epbmReleasingAllowed m1 : 10|1@1+ (1,0) [0|1] ""  Receiver
 SG_ VCRIGHT_epbmServiceAllowed m1 : 5|1@1+ (1,0) [0|1] ""  Receiver
 SG_ VCRIGHT_epbmStartAllowed m1 : 4|1@1+ (1,0) [0|1] ""  Receiver
 SG_ VCRIGHT_epbmSummonAllowed m1 : 12|1@1+ (1,0) [0|1] ""  Receiver
 SG_ VCRIGHT_epbmSummonParkAllowed m1 : 13|1@1+ (1,0) [0|1] ""  Receiver
 SG_ VCRIGHT_epbmSummonReleaseAllowed m1 : 14|1@1+ (1,0) [0|1] ""  Receiver
 SG_ VCRIGHT_epbmSummonState m0 : 48|3@1+ (1,0) [0|6] ""  Receiver
 SG_ VCRIGHT_epbmSystemStatus m0 : 60|4@1+ (1,0) [0|8] ""  Receiver
 SG_ VCRIGHT_epbmUnknownAllowed m1 : 16|1@1+ (1,0) [0|1] ""  Receiver
 SG_ VCRIGHT_epbmWinchAllowed m1 : 6|1@1+ (1,0) [0|1] ""  Receiver
 SG_ VCRIGHT_epbmWinchReleaseAllowed m1 : 7|1@1+ (1,0) [0|1] ""  Receiver
 SG_ VCRIGHT_summonActiveAllowed m1 : 19|1@1+ (1,0) [0|1] ""  Receiver
 SG_ VCRIGHT_summonArmedAllowed m1 : 18|1@1+ (1,0) [0|1] ""  Receiver
 SG_ VCRIGHT_summonCompleteAllowed m1 : 20|1@1+ (1,0) [0|1] ""  Receiver
 SG_ VCRIGHT_summonFaultAllowed m1 : 21|1@1+ (1,0) [0|1] ""  Receiver
 SG_ VCRIGHT_summonFaultReason m0 : 40|5@1+ (1,0) [0|28] ""  Receiver
 SG_ VCRIGHT_summonIdleAllowed m1 : 17|1@1+ (1,0) [0|1] ""  Receiver
 SG_ VCRIGHT_summonInitAllowed m1 : 15|1@1+ (1,0) [0|1] ""  Receiver
 SG_ VCRIGHT_summonUnavailableAllowed m1 : 22|1@1+ (1,0) [0|1] ""  Receiver

BA_DEF_ BO_  "GenMsgSendType" ENUM  "Cyclic";
BA_DEF_ BO_  "GenMsgCycleTime" INT 0 10000;
BA_ "GenMsgSendType" BO_ 873 0;
BA_ "GenMsgCycleTime" BO_ 873 1000;
BA_ "GenMsgSendType" BO_ 876 0;
BA_ "GenMsgCycleTime" BO_ 876 1000;
BA_ "GenMsgSendType" BO_ 848 0;
BA_ "GenMsgCycleTime" BO_ 848 1000;
BA_ "GenMsgSendType" BO_ 850 0;
BA_ "GenMsgCycleTime" BO_ 850 1000;
BA_ "GenMsgSendType" BO_ 867 0;
BA_ "GenMsgCycleTime" BO_ 867 1000;
BA_ "GenMsgSendType" BO_ 905 0;
BA_ "GenMsgCycleTime" BO_ 905 500;
BA_ "GenMsgSendType" BO_ 890 0;
BA_ "GenMsgCycleTime" BO_ 890 40;
BA_ "GenMsgSendType" BO_ 874 0;
BA_ "GenMsgCycleTime" BO_ 874 1000;
BA_ "GenMsgSendType" BO_ 841 0;
BA_ "GenMsgCycleTime" BO_ 841 1000;
BA_ "GenMsgSendType" BO_ 854 0;
BA_ "GenMsgCycleTime" BO_ 854 1000;
BA_ "GenMsgSendType" BO_ 855 0;
BA_ "GenMsgCycleTime" BO_ 855 1000;
BA_ "GenMsgSendType" BO_ 858 0;
BA_ "GenMsgCycleTime" BO_ 858 1000;
BA_ "GenMsgSendType" BO_ 859 0;
BA_ "GenMsgCycleTime" BO_ 859 1000;
BA_ "GenMsgSendType" BO_ 886 0;
BA_ "GenMsgCycleTime" BO_ 886 1000;
BA_ "GenMsgSendType" BO_ 914 0;
BA_ "GenMsgCycleTime" BO_ 914 1000;
BA_ "GenMsgSendType" BO_ 883 0;
BA_ "GenMsgCycleTime" BO_ 883 10;
BA_ "GenMsgSendType" BO_ 913 0;
BA_ "GenMsgCycleTime" BO_ 913 1000;
BA_ "GenMsgSendType" BO_ 882 0;
BA_ "GenMsgCycleTime" BO_ 882 10;
BA_ "GenMsgSendType" BO_ 895 0;
BA_ "GenMsgCycleTime" BO_ 895 1000;
BA_ "GenMsgSendType" BO_ 888 0;
BA_ "GenMsgCycleTime" BO_ 888 1000;
BA_ "GenMsgSendType" BO_ 904 0;
BA_ "GenMsgCycleTime" BO_ 904 1000;
BA_ "GenMsgSendType" BO_ 840 0;
BA_ "GenMsgCycleTime" BO_ 840 1000;
BA_ "GenMsgSendType" BO_ 872 0;
BA_ "GenMsgCycleTime" BO_ 872 1000;
BA_ "GenMsgSendType" BO_ 861 0;
BA_ "GenMsgCycleTime" BO_ 861 1000;
BA_ "GenMsgSendType" BO_ 846 0;
BA_ "GenMsgCycleTime" BO_ 846 100;
BA_ "GenMsgSendType" BO_ 862 0;
BA_ "GenMsgCycleTime" BO_ 862 100;
BA_ "GenMsgSendType" BO_ 894 0;
BA_ "GenMsgCycleTime" BO_ 894 1000;
BA_ "GenMsgSendType" BO_ 900 0;
BA_ "GenMsgCycleTime" BO_ 900 1000;
BA_ "GenMsgSendType" BO_ 837 0;
BA_ "GenMsgCycleTime" BO_ 837 1000;
BA_ "GenMsgSendType" BO_ 881 0;
BA_ "GenMsgCycleTime" BO_ 881 1000;
BA_ "GenMsgSendType" BO_ 849 0;
BA_ "GenMsgCycleTime" BO_ 849 10000;
BA_ "GenMsgSendType" BO_ 869 0;
BA_ "GenMsgCycleTime" BO_ 869 1000;
BA_ "GenMsgSendType" BO_ 880 0;
BA_ "GenMsgCycleTime" BO_ 880 1000;
BA_ "GenMsgSendType" BO_ 845 0;
BA_ "GenMsgCycleTime" BO_ 845 1000;
BA_ "GenMsgSendType" BO_ 877 0;
BA_ "GenMsgCycleTime" BO_ 877 1000;
BA_ "GenMsgSendType" BO_ 909 0;
BA_ "GenMsgCycleTime" BO_ 909 1000;
BA_ "GenMsgSendType" BO_ 832 0;
BA_ "GenMsgCycleTime" BO_ 832 100;
BA_ "GenMsgSendType" BO_ 897 0;
BA_ "GenMsgCycleTime" BO_ 897 250;
BA_ "GenMsgSendType" BO_ 864 0;
BA_ "GenMsgCycleTime" BO_ 864 100;
BA_ "GenMsgSendType" BO_ 915 0;
BA_ "GenMsgCycleTime" BO_ 915 50;
BA_ "GenMsgSendType" BO_ 899 0;
BA_ "GenMsgCycleTime" BO_ 899 100;
BA_ "GenMsgSendType" BO_ 857 0;
BA_ "GenMsgCycleTime" BO_ 857 100;
VAL_ 832 VCFRONT_matrixIndex 0 "AlertMatrix0" 1 "AlertMatrix1" 2 "AlertMatrix2" 3 "AlertMatrix3" 4 "AlertMatrix4" ;
VAL_ 837 PTC_infoIndex 0 "DEPRECATED_0" 1 "DEPRECATED_1" 2 "DEPRECATED_2" 3 "DEPRECATED_3" 4 "DEPRECATED_4" 5 "DEPRECATED_5" 6 "DEPRECATED_6" 7 "DEPRECATED_7" 8 "DEPRECATED_8" 9 "DEPRECATED_9" 10 "BUILD_HWID_COMPONENTID" 11 "PCBAID_ASSYID_USAGEID" 13 "APP_CRC" 14 "BOOTLOADER_SVN" 15 "BOOTLOADER_CRC" 16 "SUBCOMPONENT" 17 "APP_GITHASH" 18 "BOOTLOADER_GITHASH" 19 "VERSION_DEPRECATED" 20 "UDS_PROTOCOL_BOOTCRC" 22 "VARIANTCRC" 25 "PACKAGE_PN_1_7" 26 "PACKAGE_PN_8_14" 27 "PACKAGE_PN_15_20" 29 "PACKAGE_SN_1_7" 30 "PACKAGE_SN_8_14" 31 "SUBCOMPONENT_GITHASH" 255 "END" ;
VAL_ 837 PTC_infoBuildType 0 "UNKNOWN_BUILD" 1 "PLATFORM_BUILD" 2 "LOCAL_BUILD" 3 "TRACEABLE_CI_BUILD" 4 "MFG_BUILD" ;
VAL_ 837 PTC_infoAssemblyId 1 "ASSEMBLY1" 255 "ASSEMBLY_SNA" ;
VAL_ 840 GTW_vehicleVersionMatchStatus 0 "NOT_CALCULATED_YET" 1 "MISMATCHED" 2 "MATCHED" ;
VAL_ 846 PARK_frontLeftMiddleRawDistData 255 "SNA" ;
VAL_ 846 PARK_frontMiddleRawDistData 255 "SNA" ;
VAL_ 846 PARK_frontRightMiddleRawDistData 255 "SNA" ;
VAL_ 849 RCM_infoIndex 0 "DEPRECATED_0" 1 "DEPRECATED_1" 2 "DEPRECATED_2" 3 "DEPRECATED_3" 4 "DEPRECATED_4" 5 "DEPRECATED_5" 6 "DEPRECATED_6" 7 "DEPRECATED_7" 8 "DEPRECATED_8" 9 "DEPRECATED_9" 10 "BUILD_HWID_COMPONENTID" 11 "PCBAID_ASSYID_USAGEID" 13 "APP_CRC" 14 "BOOTLOADER_SVN" 15 "BOOTLOADER_CRC" 16 "SUBCOMPONENT" 17 "APP_GITHASH" 18 "BOOTLOADER_GITHASH" 19 "VERSION_DEPRECATED" 20 "UDS_PROTOCOL_BOOTCRC" 22 "VARIANTCRC" 25 "PACKAGE_PN_1_7" 26 "PACKAGE_PN_8_14" 27 "PACKAGE_PN_15_20" 29 "PACKAGE_SN_1_7" 30 "PACKAGE_SN_8_14" 31 "SUBCOMPONENT_GITHASH" 255 "END" ;
VAL_ 849 RCM_infoBuildType 0 "UNKNOWN_BUILD" 1 "PLATFORM_BUILD" 2 "LOCAL_BUILD" 3 "TRACEABLE_CI_BUILD" 4 "MFG_BUILD" ;
VAL_ 850 BMS_nominalFullPackEnergy 2047 "SNA" ;
VAL_ 850 BMS_nominalEnergyRemaining 2047 "SNA" ;
VAL_ 850 BMS_idealEnergyRemaining 2047 "SNA" ;
VAL_ 850 BMS_energyBuffer 255 "SNA" ;
VAL_ 850 BMS_expectedEnergyRemaining 2047 "SNA" ;
VAL_ 850 BMS_energyToChargeComplete 2047 "SNA" ;
VAL_ 851 UI_autopilotTrial 0 "NONE" 1 "START" 2 "STOP" 3 "ACTIVE" ;
VAL_ 851 UI_cellNetworkTechnology 0 "NONE" 1 "GPRS" 2 "EDGE" 3 "UMTS" 4 "HSDPA" 5 "HSUPA" 6 "HSPA" 7 "LTE" 15 "SNA" ;
VAL_ 851 UI_cellSignalBars 0 "ZERO" 1 "ONE" 2 "TWO" 3 "THREE" 4 "FOUR" 5 "FIVE" 7 "SNA" ;
VAL_ 851 UI_factoryReset 0 "NONE_SNA" 1 "DEVELOPER" 2 "DIAGNOSTIC" 3 "CUSTOMER" ;
VAL_ 856 UI_TPMSLearnIDMode 0 "NO_ID_LEARN_FUNCTION" 1 "AUTO_LEARN_ACTIVE_BY_MANUAL" 2 "AUTO_LOCATION_ACTIVE_BY_MANUAL" 3 "AUTO_LEARN_ACTIVE_AFTER_PWR" 4 "AUTO_LOCATION_ACTIVE_AFTER_PWR" ;
VAL_ 856 UI_TPMSMode 0 "UNUSED_MODE" 1 "NORMAL_MODE" 2 "PERFORMANCE_MODE" ;
VAL_ 856 UI_sizeOfWheelSelect 0 "UNUSED" 1 "18_INCH_WHEEL" 2 "19_INCH_WHEEL" ;
VAL_ 857 VCSEC_BLEConnectionStatus 0 "NOT_CONNECTED" 1 "CONNECTED" 2 "WRITE" 3 "NOTIFICATION" 4 "READ" 5 "UPDATE_SPEED" ;
VAL_ 857 VCSEC_BLEDeviceLocation 0 "NOT_PRESENT" 1 "CONNECTION_RANGE" 2 "AUTHENTICATION_RANGE" ;
VAL_ 857 VCSEC_BLEDevicePairingStatus 0 "IDLE" 1 "STEP1" 2 "STEP2" 3 "STEP3" 4 "SUCCESS" 5 "FAILURE" ;
VAL_ 857 VCSEC_BLEDeviceType 0 "UNKNOWN" 1 "ANDROID" 2 "IOS" 3 "OTHER" ;
VAL_ 861 IBST_matrixIndex 0 "AlertMatrix0" 1 "AlertMatrix1" 2 "AlertMatrix2" ;
VAL_ 862 PARK_rearLeftMiddleRawDistData 255 "SNA" ;
VAL_ 862 PARK_rearMiddleRawDistData 255 "SNA" ;
VAL_ 862 PARK_rearRightMiddleRawDistData 255 "SNA" ;
VAL_ 864 VCLEFT_matrixIndex 0 "AlertMatrix0" 1 "AlertMatrix1" 2 "AlertMatrix2" 3 "AlertMatrix3" 4 "AlertMatrix4" 5 "AlertMatrix5" ;
VAL_ 867 CMP_infoIndex 0 "DEPRECATED_0" 1 "DEPRECATED_1" 2 "DEPRECATED_2" 3 "DEPRECATED_3" 4 "DEPRECATED_4" 5 "DEPRECATED_5" 6 "DEPRECATED_6" 7 "DEPRECATED_7" 8 "DEPRECATED_8" 9 "DEPRECATED_9" 10 "BUILD_HWID_COMPONENTID" 11 "PCBAID_ASSYID_USAGEID" 13 "APP_CRC" 14 "BOOTLOADER_SVN" 15 "BOOTLOADER_CRC" 16 "SUBCOMPONENT" 17 "APP_GITHASH" 18 "BOOTLOADER_GITHASH" 19 "VERSION_DEPRECATED" 20 "UDS_PROTOCOL_BOOTCRC" 22 "VARIANTCRC" 25 "PACKAGE_PN_1_7" 26 "PACKAGE_PN_8_14" 27 "PACKAGE_PN_15_20" 29 "PACKAGE_SN_1_7" 30 "PACKAGE_SN_8_14" 31 "SUBCOMPONENT_GITHASH" 255 "END" ;
VAL_ 867 CMP_infoBuildType 0 "UNKNOWN_BUILD" 1 "PLATFORM_BUILD" 2 "LOCAL_BUILD" 3 "TRACEABLE_CI_BUILD" 4 "MFG_BUILD" ;
VAL_ 867 CMP_infoAssemblyId 1 "ASSEMBLY1" 255 "ASSEMBLY_SNA" ;
VAL_ 872 GTW_offboardUpdateState 0 "WAITING_FOR_CONNECTION" 1 "WAIT_UPDATE_TRIGGER" 2 "PREPARING" 3 "RUNNING" 4 "CONFIRM_UPDATE" 5 "LATCH_RESULT" ;
VAL_ 872 GTW_offboardUpdateStatus 0 "OK" 1 "FILE_OPEN_ERROR" 2 "UNPLUGGED" 3 "UDS_FAILED" 4 "SUCCESS" 5 "LOST_DIGITAL_COMMS" 6 "NOT_NEEDED" 7 "APPTRIPLE_MISMATCH" ;
VAL_ 879 TPMS_learningStatus 0 "FAILED" 1 "ONGOING" 2 "STOPPED" 3 "PASSED" ;
VAL_ 879 TPMS_localisationStatus 0 "FAILED" 1 "ONGOING" 2 "STOPPED" 3 "PASSED" ;
VAL_ 881 RCM_matrixIndex 0 "AlertMatrix0" 1 "AlertMatrix1" ;
VAL_ 882 EPAS3S_currentTuneMode 0 "DM_COMFORT" 1 "DM_STANDARD" 2 "DM_SPORT" 3 "RWD_COMFORT" 4 "RWD_STANDARD" 5 "RWD_SPORT" ;
VAL_ 882 EPAS3S_eacErrorCode 0 "EAC_ERROR_IDLE" 1 "EAC_ERROR_MIN_SPEED" 2 "EAC_ERROR_MAX_SPEED" 3 "EAC_ERROR_HANDS_ON" 4 "EAC_ERROR_TMP_FAULT" 5 "EAR_ERROR_MAX_STEER_DELTA" 6 "EAC_ERROR_HIGH_ANGLE_REQ" 7 "EAC_ERROR_HIGH_ANGLE_RATE_REQ" 8 "EAC_ERROR_HIGH_ANGLE_SAFETY" 9 "EAC_ERROR_HIGH_ANGLE_RATE_SAFETY" 10 "EAC_ERROR_HIGH_MMOT_SAFETY" 11 "EAC_ERROR_HIGH_TORSION_SAFETY" 12 "EAC_ERROR_LOW_ASSIST" 13 "EAC_ERROR_PINION_VEL_DIFF" 14 "EAC_EXTERNAL_MONITOR_INHIBIT" 15 "SNA" ;
VAL_ 882 EPAS3S_handsOnLevel 0 "0" 1 "1" 2 "2" 3 "3" ;
VAL_ 882 EPAS3S_internalSASQF 0 "UNDEFINABLE_ACCURACY" 1 "IN_SPEC" ;
VAL_ 882 EPAS3S_steeringFault 0 "NO_FAULT" 1 "FAULT" ;
VAL_ 882 EPAS3S_steeringRackForce 1022 "NOT_IN_SPEC" 1023 "SNA" ;
VAL_ 882 EPAS3S_steeringReduced 0 "NORMAL_ASSIST" 1 "REDUCED_ASSIST" ;
VAL_ 882 EPAS3S_torsionBarTorque 4094 "UNDEFINABLE_DATA" 4095 "SNA" ;
VAL_ 883 EPAS3P_currentTuneMode 0 "DM_COMFORT" 1 "DM_STANDARD" 2 "DM_SPORT" 3 "RWD_COMFORT" 4 "RWD_STANDARD" 5 "RWD_SPORT" ;
VAL_ 883 EPAS3P_eacErrorCode 0 "EAC_ERROR_IDLE" 1 "EAC_ERROR_MIN_SPEED" 2 "EAC_ERROR_MAX_SPEED" 3 "EAC_ERROR_HANDS_ON" 4 "EAC_ERROR_TMP_FAULT" 5 "EAR_ERROR_MAX_STEER_DELTA" 6 "EAC_ERROR_HIGH_ANGLE_REQ" 7 "EAC_ERROR_HIGH_ANGLE_RATE_REQ" 8 "EAC_ERROR_HIGH_ANGLE_SAFETY" 9 "EAC_ERROR_HIGH_ANGLE_RATE_SAFETY" 10 "EAC_ERROR_HIGH_MMOT_SAFETY" 11 "EAC_ERROR_HIGH_TORSION_SAFETY" 12 "EAC_ERROR_LOW_ASSIST" 13 "EAC_ERROR_PINION_VEL_DIFF" 14 "EAC_EXTERNAL_MONITOR_INHIBIT" 15 "SNA" ;
VAL_ 883 EPAS3P_eacStatus 0 "EAC_INHIBITED" 1 "EAC_AVAILABLE" 2 "EAC_ACTIVE" 3 "EAC_FAULT" 4 "LANE_KEEP_ASSIST" 5 "EMERGENCY_LANE_KEEP" 7 "SNA" ;
VAL_ 883 EPAS3P_handsOnLevel 0 "0" 1 "1" 2 "2" 3 "3" ;
VAL_ 883 EPAS3P_internalSASQF 0 "UNDEFINABLE_ACCURACY" 1 "IN_SPEC" ;
VAL_ 883 EPAS3P_steeringFault 0 "NO_FAULT" 1 "FAULT" ;
VAL_ 883 EPAS3P_steeringRackForce 1022 "NOT_IN_SPEC" 1023 "SNA" ;
VAL_ 883 EPAS3P_steeringReduced 0 "NORMAL_ASSIST" 1 "REDUCED_ASSIST" ;
VAL_ 883 EPAS3P_torsionBarTorque 4094 "UNDEFINABLE_DATA" 4095 "SNA" ;
VAL_ 886 DI_frontInverterTQF 0 "INIT" 1 "IRRATIONAL" 2 "RATIONAL" 3 "UNKNOWN" ;
VAL_ 890 DAS_TP_multiplexer 0 "START" 1 "LEFT_LANE" 2 "RIGHT_LANE" 3 "HPP" 4 "NAV" 5 "VIRTUAL_LANE" 6 "LEFT_BOTTS_DOTS" 7 "RIGHT_BOTTS_DOTS" 8 "LANE_INFO" 9 "END" ;
VAL_ 890 DAS_TP_llType 0 "UNDECIDED" 1 "SOLID" 2 "ROAD_EDGE" 3 "DASHED" 4 "DOUBLE_LANE" 5 "BOTTS_DOTS" 6 "BARRIER" 7 "INVALID" ;
VAL_ 890 DAS_TP_rlType 0 "UNDECIDED" 1 "SOLID" 2 "ROAD_EDGE" 3 "DASHED" 4 "DOUBLE_LANE" 5 "BOTTS_DOTS" 6 "BARRIER" 7 "INVALID" ;
VAL_ 894 PARK_matrixIndex 0 "AlertMatrix0" 1 "AlertMatrix1" ;
VAL_ 897 VCFRONT_logging1HzIndex 18 "BODY_CONTROL" 0 "COOLANT" 19 "COOLANT_2" 2 "COOLANT_VALVE" 20 "END" 1 "FAN_DEMAND_CONDENSER_AND_FET_TEMPS" 3 "HCML_LED_TEMPS" 4 "HCMR_LED_TEMPS" 6 "HEADLAMP_AIM" 5 "HOMELINK" 15 "HP_ARBITRATION" 9 "HP_CONTROL_LOOP_AND_STATE" 10 "HP_CYCLE_MODEL" 8 "HP_DATA_AND_ACCUMULATORS" 12 "HP_DISSIPATION_AND_POWER" 11 "HP_EXV_CALIBRATION" 7 "HP_EXV_RANGE" 17 "HP_MODE_OPTIONS_AND_ESTIMATES" 16 "HP_MODE_SELECT_AND_ESTIMATES" 14 "HP_PRESSURE_CONTROL" 13 "HP_TEMPS_AND_DEMANDS" ;
VAL_ 897 VCFRONT_HCML_bladeTemp 128 "SNA" ;
VAL_ 897 VCFRONT_HCML_diffuseTemp 128 "SNA" ;
VAL_ 897 VCFRONT_HCML_highBeamTemp 128 "SNA" ;
VAL_ 897 VCFRONT_HCML_lowBeamSpotTemp 128 "SNA" ;
VAL_ 897 VCFRONT_HCML_turnTemp 128 "SNA" ;
VAL_ 897 VCFRONT_HCMR_bladeTemp 128 "SNA" ;
VAL_ 897 VCFRONT_HCMR_diffuseTemp 128 "SNA" ;
VAL_ 897 VCFRONT_HCMR_highBeamTemp 128 "SNA" ;
VAL_ 897 VCFRONT_HCMR_lowBeamSpotTemp 128 "SNA" ;
VAL_ 897 VCFRONT_HCMR_turnTemp 128 "SNA" ;
VAL_ 897 VCFRONT_coolantValveCountRange 1023 "SNA" ;
VAL_ 897 VCFRONT_coolantValveRadBypass 127 "SNA" ;
VAL_ 897 VCFRONT_coolantValveRecalReason 3 "CALIBRATION_FAULT_NO_TRAVEL" 2 "GENERAL_FAULT" 1 "MAX_TRAVEL" 5 "MOTOR_FEEDBACK_INTERRUPTED" 6 "NVRAM_LOSS" 4 "SELF_TEST" 7 "SYSTEM_LEVEL_FAULT_RESPONSE" 0 "UNDEFINED" ;
VAL_ 897 VCFRONT_drlMode 2 "DRL_MODE_DRL" 0 "DRL_MODE_OFF" 1 "DRL_MODE_POSITION" ;
VAL_ 897 VCFRONT_homelinkRegionCode 5 "HOMELINK_REGION_CODE_AMERICAS" 9 "HOMELINK_REGION_CODE_CHINA" 1 "HOMELINK_REGION_CODE_EUROPE" 8 "HOMELINK_REGION_CODE_REST_OF_WORLD" 0 "HOMELINK_REGION_CODE_UNKNOWN" ;
VAL_ 897 VCFRONT_hpMode 2 "AMBIENT_SOURCE" 15 "BATTERY_COOL" 17 "BATTERY_COOL_CABIN_CONDENSER" 16 "BATTERY_COOL_CABIN_CONDENSER_REHEAT" 18 "BATTERY_COOL_CABIN_REHEAT" 19 "BATTERY_COOL_EVAPORATOR" 13 "BATTERY_HEAT_AMBIENT_SOURCE" 14 "BATTERY_HEAT_COP1" 11 "CABIN_COOL_EVAPORATOR" 12 "CABIN_COOL_EVAPORATOR_REHEAT" 4 "CABIN_HEAT_AMBIENT_SOURCE" 10 "CABIN_HEAT_BATTERY_COOL_REHEAT" 9 "CABIN_HEAT_BATTERY_HEAT_REHEAT_AMBIENT_SOURCE" 7 "CABIN_HEAT_BLEND" 8 "CABIN_HEAT_COP1" 6 "CABIN_HEAT_REHEAT_AMBIENT_SOURCE" 5 "CABIN_HEAT_REHEAT_SCAVENGE" 3 "CABIN_HEAT_SCAVENGE_ONLY" 1 "GENERAL" 0 "NONE" ;
VAL_ 897 VCFRONT_hpRefrigerantPurgeState 2 "COMPLETE" 1 "EVAP_PURGE" 0 "IDLE" ;
VAL_ 897 VCFRONT_modeDesired 3 "AMBIENT_SOURCE" 2 "BLEND" 1 "PARALLEL" 0 "SERIES" ;
VAL_ 897 VCFRONT_modeTransitionID 23 "ENTER_AMBIENTSOURCE" 24 "EXIT_AMBIENTSOURCE" 20 "INIT" 21 "OVERRIDE" 6 "PARALLEL_2_drive_batteryWantsHeat" 7 "PARALLEL_3_drive_batteryWantsCool" 8 "PARALLEL_4_drive_batteryNeedsCool" 11 "PARALLEL_5_charge_batteryWantsHeat" 12 "PARALLEL_6_charge_batteryWantsCool" 15 "PARALLEL_7_fastCharge_batteryWantsCool" 16 "PARALLEL_8_fastCharge_batteryWantsHeat" 19 "PARALLEL_9_drive_batteryThermalLimiting" 0 "PARALLEL_F1_noFlowRequest" 33 "PAR_1_drive_battNeedsActiveCooling_evapDisabled" 34 "PAR_2_drive_ptNeedsActiveCooling" 35 "PAR_3_drive_chillerPassivelyCoolsBatt" 36 "PAR_4_drive_cannotPassivelyCoolBatt" 37 "PAR_5_drive_battAboveHotStagnationTemp" 38 "PAR_6_FC_battNeedsActiveCooling_evapDisabled" 39 "PAR_7_FC_battNeedsActiveCooling_evapEnabled" 40 "PAR_8_charge_battAbovePassiveTarget" 3 "SERIES_1_drive_batteryWantsCool" 4 "SERIES_2_drive_batteryNeedsHeat" 5 "SERIES_3_drive_batteryWantsHeat" 9 "SERIES_4_charge_batteryNeedsHeat" 10 "SERIES_5_charge_batteryWantsHeat" 13 "SERIES_6_fastCharge_batteryNeedsHeat" 14 "SERIES_7_fastCharge_batteryWantsCool" 17 "SERIES_8_preConditioning_batteryNeedsHeat" 18 "SERIES_9_drive_driveUnitThermalLimiting" 1 "SERIES_F2_faultPumps" 2 "SERIES_F3_faultTempSensors" 25 "SER_1_drive_battNeedsActiveCooling_evapEnabled" 26 "SER_2_drive_battBelowHotStagnationTemp" 27 "SER_3_drive_chillerPassivelyCools" 28 "SER_4_drive_radPassivelyCoolsBatt" 29 "SER_5_FC_battHeatingNeeded" 30 "SER_6_FC_battNeedsActiveCooling_evapDisabled" 31 "SER_7_FC_battNeedsActiveCooling_evapEnabled" 32 "SER_8_charge_battBelowPassiveTarget" 22 "UNDEFINED" ;
VAL_ 897 VCFRONT_passiveCoolingState 3 "CannotCoolBattery" 2 "ChillerAndRadCoolSeriesLoop" 1 "ChillerCoolsParallelBattLoop" 0 "ChillerCoolsSeriesLoop" ;
VAL_ 897 VCFRONT_pumpBatteryFETTemp 255 "SNA" ;
VAL_ 897 VCFRONT_pumpPowertrainFETTemp 255 "SNA" ;
VAL_ 897 VCFRONT_radiatorFanFETTemp 255 "SNA" ;
VAL_ 897 VCFRONT_radiatorFanRunReason 1 "ACTIVE_MANAGER" 2 "AMBIENT_SNIFF" 5 "COAST_MODE" 4 "HEAT_PUMP" 6 "MIN_ON_GLOBAL" 7 "MIN_ON_NVH" 0 "NONE" 3 "NVH_MASKING" 8 "UDS" ;
VAL_ 897 VCFRONT_tempRefrigSuction 255 "SNA" ;
VAL_ 899 VCRIGHT_estimatedThsSolarLoad 1023 "SNA" ;
VAL_ 899 VCRIGHT_estimatedVehicleSituatio 1 "VEHICLE_SITUATION_INDOOR" 2 "VEHICLE_SITUATION_OUTDOOR" 0 "VEHICLE_SITUATION_UNKNOWN" ;
VAL_ 899 VCRIGHT_thsHumidity 255 "SNA" ;
VAL_ 899 VCRIGHT_thsSolarLoadInfrared 1023 "SNA" ;
VAL_ 899 VCRIGHT_thsSolarLoadVisible 1023 "SNA" ;
VAL_ 899 VCRIGHT_thsTemperature 128 "SNA" ;
VAL_ 904 GTW_CH_faultConfinement 0 "ERROR_ACTIVE" 1 "ERROR_PASSIVE" 2 "BUS_OFF" ;
VAL_ 904 GTW_PARTY_faultConfinement 0 "ERROR_ACTIVE" 1 "ERROR_PASSIVE" 2 "BUS_OFF" ;
VAL_ 904 GTW_VEH_faultConfinement 0 "ERROR_ACTIVE" 1 "ERROR_PASSIVE" 2 "BUS_OFF" ;
VAL_ 905 DAS_ACC_report 0 "TARGET_NONE" 1 "TARGET_CIPV" 2 "TARGET_IN_FRONT_OF_CIPV" 3 "TARGET_MCVL" 4 "TARGET_MCVR" 5 "TARGET_CUTIN" 6 "TARGET_TYPE_STOP_SIGN" 7 "TARGET_TYPE_TRAFFIC_LIGHT" 8 "TARGET_TYPE_IPSO" 9 "TARGET_TYPE_FAULT" 10 "CSA" 11 "LC_HANDS_ON_REQD_STRUCK_OUT" 12 "LC_EXTERNAL_STATE_ABORTING" 13 "LC_EXTERNAL_STATE_ABORTED" 14 "LC_EXTERNAL_STATE_ACTIVE_RESTRICTED" 15 "RADAR_OBJ_ONE" 16 "RADAR_OBJ_TWO" 17 "TARGET_MCP" 18 "FLEET_SPEEDS" 19 "MCVLR_DPP" 20 "MCVLR_IN_PATH" 21 "CIPV_CUTTING_OUT" 22 "RADAR_OBJ_FIVE" 23 "CAMERA_ONLY" 24 "BEHAVIOR_REPORT" ;
VAL_ 905 DAS_accSpeedLimit 0 "NONE" 1023 "SNA" ;
VAL_ 905 DAS_activationFailureStatus 0 "IDLE" 1 "FAILED_1" 2 "FAILED_2" ;
VAL_ 905 DAS_driverInteractionLevel 0 "DRIVER_INTERACTING" 1 "DRIVER_NOT_INTERACTING" 2 "CONTINUED_DRIVER_NOT_INTERACTING" ;
VAL_ 905 DAS_longCollisionWarning 0 "NONE" 1 "VEHICLE_UNKNOWN" 2 "PEDESTRIAN" 3 "IPSO" 4 "STOPSIGN_STOPLINE" 5 "TFL_STOPLINE" 6 "VEHICLE_CIPV" 7 "VEHICLE_CUTIN" 8 "VEHICLE_MCVL" 9 "VEHICLE_MCVL2" 10 "VEHICLE_MCVR" 11 "VEHICLE_MCVR2" 12 "VEHICLE_CIPV2" 15 "SNA" ;
VAL_ 905 DAS_lssState 0 "FAULT" 1 "LDW" 2 "LKA" 3 "ELK" 4 "MONITOR" 5 "BLINDSPOT" 6 "ABORT" 7 "OFF" ;
VAL_ 905 DAS_pmmCameraFaultReason 0 "NO_FAULT" 1 "BLOCKED_FRONT" 2 "INVALID_MIA" ;
VAL_ 905 DAS_pmmLoggingRequest 0 "FALSE" 1 "TRUE" ;
VAL_ 905 DAS_pmmObstacleSeverity 0 "NONE" 1 "IMMINENT_REAR" 2 "IMMINENT_FRONT" 3 "BRAKE_REQUEST" 4 "CRASH_REAR" 5 "CRASH_FRONT" 6 "ACCEL_LIMIT" 7 "SNA" ;
VAL_ 905 DAS_pmmRadarFaultReason 0 "NO_FAULT" 1 "BLOCKED_FRONT" 2 "INVALID_MIA" ;
VAL_ 905 DAS_pmmSysFaultReason 0 "NONE" 1 "DAS_DISABLED" 2 "SPEED" 3 "DI_FAULT" 4 "STEERING_ANGLE_RATE" 5 "DISABLED_BY_USER" 6 "ROAD_TYPE" 7 "BRAKE_PEDAL_INHIBIT" ;
VAL_ 905 DAS_pmmUltrasonicsFaultReason 0 "NO_FAULT" 1 "BLOCKED_FRONT" 2 "BLOCKED_REAR" 3 "BLOCKED_BOTH" 4 "INVALID_MIA" ;
VAL_ 905 DAS_ppOffsetDesiredRamp 128 "PP_NO_OFFSET" ;
VAL_ 905 DAS_radarTelemetry 0 "IDLE" 1 "NORMAL" 2 "URGENT" ;
VAL_ 905 DAS_robState 0 "INHIBITED" 1 "MEASURE" 2 "ACTIVE" 3 "MAPLESS" ;
VAL_ 913 EPAS3S_matrixIndex 0 "AlertMatrix0" 1 "AlertMatrix1" 2 "AlertMatrix2" ;
VAL_ 914 EPAS3P_matrixIndex 0 "AlertMatrix0" 1 "AlertMatrix1" 2 "AlertMatrix2" ;
VAL_ 914 BMS_moduleType 0 "UNKNOWN" 1 "E3_NCT" 2 "E1_NCT" 3 "E3_CT" 4 "E1_CT" 5 "E1_CP" ;
VAL_ 914 BMS_moduleType 0 "UNKNOWN" 1 "E3_NCT" 2 "E1_NCT" 3 "E3_CT" 4 "E1_CT" 5 "E1_CP" ;
VAL_ 914 BMS_packConfigMultiplexer 0 "Mux0" 1 "Mux1" ;
VAL_ 914 BMS_reservedConfig_0 0 "BMS_CONFIG_0" 1 "BMS_CONFIG_1" 10 "BMS_CONFIG_10" 11 "BMS_CONFIG_11" 12 "BMS_CONFIG_12" 13 "BMS_CONFIG_13" 14 "BMS_CONFIG_14" 15 "BMS_CONFIG_15" 16 "BMS_CONFIG_16" 17 "BMS_CONFIG_17" 18 "BMS_CONFIG_18" 19 "BMS_CONFIG_19" 2 "BMS_CONFIG_2" 20 "BMS_CONFIG_20" 21 "BMS_CONFIG_21" 22 "BMS_CONFIG_22" 23 "BMS_CONFIG_23" 24 "BMS_CONFIG_24" 25 "BMS_CONFIG_25" 26 "BMS_CONFIG_26" 27 "BMS_CONFIG_27" 28 "BMS_CONFIG_28" 29 "BMS_CONFIG_29" 3 "BMS_CONFIG_3" 30 "BMS_CONFIG_30" 31 "BMS_CONFIG_31" 4 "BMS_CONFIG_4" 5 "BMS_CONFIG_5" 6 "BMS_CONFIG_6" 7 "BMS_CONFIG_7" 8 "BMS_CONFIG_8" 9 "BMS_CONFIG_9" ;
VAL_ 915 VCRIGHT_epbmDebugIndex 0 "STATES" 1 "TRANSITIONS" ;
VAL_ 915 VCRIGHT_cdpEnumDummy 0 "IDLE" 1 "VALID" 2 "INVALID" ;
VAL_ 915 VCRIGHT_epbFaultStatus 0 "NOMINAL" 1 "RETRY" 2 "FAULT" 3 "FAULT_IDLE" ;
VAL_ 915 VCRIGHT_epbSummonState 0 "INIT" 1 "IDLE" 2 "ARMED" 3 "ACTIVE" 4 "COMPLETE" 5 "FAULT" 6 "UNAVAILABLE" ;
VAL_ 915 VCRIGHT_epbUnitStatus 0 "UNKNOWN" 1 "OPEN" 2 "DYNAMIC" 3 "PARK" 4 "START" 5 "SERVICE" 6 "WINCHMODE" 7 "WINCHMODE_RELEASING" 8 "PARKING" 9 "DYNAMIC_APPLYING" 10 "RELEASING" 11 "SERVICE_RELEASING" 12 "PARK_PENDING" 13 "WINCHMODE_PENDING" 14 "SUMMON" 15 "SUMMON_RELEASING" 16 "SUMMON_PARKING" 17 "EXTERNAL_DYNAMIC" 18 "RELEASING_FOR_EXTERNAL_PARK" 19 "EXTERNAL_PARKING" 20 "DYNAMIC_PARKING" 21 "COUNT" ;
VAL_ 915 VCRIGHT_epbmCaliperState 0 "UNSAVED" 1 "UNKNOWN" 2 "REAPPLY" 3 "PARK" 4 "OPEN" 5 "SERVICE" ;
VAL_ 915 VCRIGHT_epbmFaultStatus 0 "NOMINAL" 1 "RETRY" 2 "FAULT" 3 "FAULT_IDLE" ;
VAL_ 915 VCRIGHT_epbmSummonState 0 "INIT" 1 "IDLE" 2 "ARMED" 3 "ACTIVE" 4 "COMPLETE" 5 "FAULT" 6 "UNAVAILABLE" ;
VAL_ 915 VCRIGHT_summonFaultReason 0 "NONE" 1 "DI_MIA" 2 "DAS_MIA" 3 "ESP_MIA" 4 "EPBM_MIA" 5 "DI_FAULT" 6 "DI_APC_FAULT" 7 "DAS_FAULT" 8 "ESP_FAULT" 9 "VEH_CAN_FAULT" 10 "EAC_NOT_ALLOWED" 11 "EPBM_REQUEST" 12 "SPEED" 13 "EXTERNAL" 14 "PARK_MIA" 15 "PM_MIA" 16 "PM_REQUEST" 17 "OOC" 18 "MISMATCH" 19 "EPB_FAULT" 20 "DI_STATE_INVALID" 21 "PASSIVE_REQUEST" 22 "EPBREMOTE_MIA" 23 "REMOTE_SUMMON_FAULTED" 24 "LOCAL_UNIT_FAULTED" 25 "REMOTE_UNIT_FAULTED" 26 "START_IN_UNAVAILABLE" 27 "INVALID_REMOTE_STATE" 28 "REMOTE_DID_NOT_START" ;
